VERSION ""

NS_ :

BS_:

BU_: Sender
VAL_TABLE_ FMI 31 "ConditionExists" 19 "Received network data in error" 18 "Below normal (moderately severe)" 17 "Below normal (least severe)" 16 "Above normal (moderately severe)" 15 "Above normal (least severe)" 14 "Special intstructions" 13 "Out of calibration" 12 "Bad intelligent device" 11 "Root cause not known" 10 "Abnormal rate of change" 9 "Abnormal update rate" 8 "Abnormal frequency" 7 "Mechanical system not responding" 6 "Current above normal" 5 "Current below normal" 4 "Voltage below normal" 3 "Voltage above normal" 2 "Data erratic" 1 "Below normal (most severe)" 0 "Above normal (most severe)" ;

BO_ 3221225472 VECTOR__INDEPENDENT_SIG_MSG: 0 Vector__XXX
 SG_ TireTemp : 0|16@1+ (0.03125,-273) [-273|1735] "deg" Vector__XXX
 SG_ TirePress : 0|8@1+ (4,0) [0|1000] "kPa" Vector__XXX
 SG_ SPN5 : 0|16@1+ (1,0) [0|65536] "" Vector__XXX
 SG_ SPN4 : 0|16@1+ (1,0) [0|65536] "" Vector__XXX
 SG_ SPN3 : 0|16@1+ (1,0) [0|65536] "" Vector__XXX
 SG_ SPN2 : 0|16@1+ (1,0) [0|65536] "" Vector__XXX
 SG_ FailureModeIdentifier5 : 0|5@1+ (1,0) [0|0] "" Vector__XXX
 SG_ FailureModeIdentifier4 : 0|5@1+ (1,0) [0|0] "" Vector__XXX
 SG_ FlashRedStopLamp : 0|2@1+ (1,0) [0|3] "" Vector__XXX
 SG_ FlashProtectLamp : 0|2@1+ (1,0) [0|3] "" Vector__XXX
 SG_ FlashMalfuncIndicatorLamp : 0|2@1+ (1,0) [0|3] "" Vector__XXX
 SG_ FlashAmberWarningLamp : 0|2@1+ (1,0) [0|3] "" Vector__XXX
 SG_ FailureModeIdentifier3 : 0|5@1+ (1,0) [0|0] "" Vector__XXX
 SG_ FailureModeIdentifier2 : 0|5@1+ (1,0) [0|0] "" Vector__XXX
 SG_ SPNConversionMethod5 : 0|1@1+ (1,0) [0|1] "" Vector__XXX
 SG_ SPNConversionMethod4 : 0|1@1+ (1,0) [0|1] "" Vector__XXX
 SG_ SPNConversionMethod3 : 0|1@1+ (1,0) [0|1] "" Vector__XXX
 SG_ SPNConversionMethod2 : 0|1@1+ (1,0) [0|1] "" Vector__XXX
 SG_ SPNConversionMethod1 : 0|1@1+ (1,0) [0|1] "" Vector__XXX
 SG_ FailureModeIdentifier1 : 0|5@1+ (1,0) [0|0] "" Vector__XXX
 SG_ SPN1 : 0|16@1+ (1,0) [0|65536] "" Vector__XXX
 SG_ MalfunctionIndicatorLampStatus : 0|2@1+ (1,0) [0|3] "" Vector__XXX
 SG_ RedStopLampState : 0|2@1+ (1,0) [0|3] "" Vector__XXX
 SG_ AmberWarningLampStatus : 0|2@1+ (1,0) [0|3] "" Vector__XXX
 SG_ ProtectLampStatus : 0|2@1+ (1,0) [0|3] "" Vector__XXX
 SG_ SPN5High : 0|3@1+ (1,0) [0|7] "" Vector__XXX
 SG_ SPN4High : 0|3@1+ (1,0) [0|7] "" Vector__XXX
 SG_ SPN3High : 0|3@1+ (1,0) [0|7] "" Vector__XXX
 SG_ SPN2High : 0|3@1+ (1,0) [0|7] "" Vector__XXX
 SG_ SPN1High : 0|3@1+ (1,0) [0|7] "" Vector__XXX
 SG_ SPNConversionMethod1 : 0|1@1+ (1,0) [0|1] "" Vector__XXX
 SG_ FailureModeIdentifier1 : 0|5@1+ (1,0) [0|0] "" Vector__XXX
 SG_ SPN1 : 0|16@1+ (1,0) [0|65536] "" Vector__XXX
 SG_ SPN1High : 0|3@1+ (1,0) [0|7] "" Vector__XXX
 SG_ SPNConversionMethod1 : 0|1@1+ (1,0) [0|1] "" Vector__XXX
 SG_ FailureModeIdentifier1 : 0|5@1+ (1,0) [0|0] "" Vector__XXX
 SG_ SPN1 : 0|16@1+ (1,0) [0|65536] "" Vector__XXX
 SG_ SPN1High : 0|3@1+ (1,0) [0|7] "" Vector__XXX
 SG_ SPN5 : 0|16@1+ (1,0) [0|65536] "" Vector__XXX
 SG_ SPN4 : 0|16@1+ (1,0) [0|65536] "" Vector__XXX
 SG_ SPN3 : 0|16@1+ (1,0) [0|65536] "" Vector__XXX
 SG_ SPN2 : 0|16@1+ (1,0) [0|65536] "" Vector__XXX
 SG_ FailureModeIdentifier5 : 0|5@1+ (1,0) [0|0] "" Vector__XXX
 SG_ FailureModeIdentifier4 : 0|5@1+ (1,0) [0|0] "" Vector__XXX
 SG_ SPNConversionMethod1 : 0|1@1+ (1,0) [0|1] "" Vector__XXX
 SG_ FailureModeIdentifier1 : 0|5@1+ (1,0) [0|0] "" Vector__XXX
 SG_ SPN1 : 0|16@1+ (1,0) [0|65536] "" Vector__XXX
 SG_ MalfunctionIndicatorLampStatus : 0|2@1+ (1,0) [0|3] "" Vector__XXX
 SG_ RedStopLampState : 0|2@1+ (1,0) [0|3] "" Vector__XXX
 SG_ AmberWarningLampStatus : 0|2@1+ (1,0) [0|3] "" Vector__XXX
 SG_ ProtectLampStatus : 0|2@1+ (1,0) [0|3] "" Vector__XXX
 SG_ FailureModeIdentifier3 : 0|5@1+ (1,0) [0|0] "" Vector__XXX
 SG_ FlashRedStopLamp : 0|2@1+ (1,0) [0|3] "" Vector__XXX
 SG_ FlashProtectLamp : 0|2@1+ (1,0) [0|3] "" Vector__XXX
 SG_ FlashMalfuncIndicatorLamp : 0|2@1+ (1,0) [0|3] "" Vector__XXX
 SG_ FlashAmberWarningLamp : 0|2@1+ (1,0) [0|3] "" Vector__XXX
 SG_ FailureModeIdentifier2 : 0|5@1+ (1,0) [0|0] "" Vector__XXX
 SG_ SPNConversionMethod5 : 0|1@1+ (1,0) [0|1] "" Vector__XXX
 SG_ SPNConversionMethod4 : 0|1@1+ (1,0) [0|1] "" Vector__XXX
 SG_ SPNConversionMethod3 : 0|1@1+ (1,0) [0|1] "" Vector__XXX
 SG_ SPNConversionMethod2 : 0|1@1+ (1,0) [0|1] "" Vector__XXX
 SG_ SPN5High : 0|3@1+ (1,0) [0|7] "" Vector__XXX
 SG_ SPN4High : 0|3@1+ (1,0) [0|7] "" Vector__XXX
 SG_ SPN3High : 0|3@1+ (1,0) [0|7] "" Vector__XXX
 SG_ SPN2High : 0|3@1+ (1,0) [0|7] "" Vector__XXX
 SG_ SPN1High : 0|3@1+ (1,0) [0|7] "" Vector__XXX
 SG_ SPN5 : 0|16@1+ (1,0) [0|65536] "" Vector__XXX
 SG_ SPN4 : 0|16@1+ (1,0) [0|65536] "" Vector__XXX
 SG_ SPN3 : 0|16@1+ (1,0) [0|65536] "" Vector__XXX
 SG_ SPN2 : 0|16@1+ (1,0) [0|65536] "" Vector__XXX
 SG_ FlashRedStopLamp : 0|2@1+ (1,0) [0|3] "" Vector__XXX
 SG_ FlashProtectLamp : 0|2@1+ (1,0) [0|3] "" Vector__XXX
 SG_ FailureModeIdentifier5 : 0|5@1+ (1,0) [0|0] "" Vector__XXX
 SG_ FailureModeIdentifier4 : 0|5@1+ (1,0) [0|0] "" Vector__XXX
 SG_ FailureModeIdentifier3 : 0|5@1+ (1,0) [0|0] "" Vector__XXX
 SG_ SPNConversionMethod1 : 0|1@1+ (1,0) [0|1] "" Vector__XXX
 SG_ FailureModeIdentifier1 : 0|5@1+ (1,0) [0|0] "" Vector__XXX
 SG_ MalfunctionIndicatorLampStatus : 0|2@1+ (1,0) [0|3] "" Vector__XXX
 SG_ RedStopLampState : 0|2@1+ (1,0) [0|3] "" Vector__XXX
 SG_ AmberWarningLampStatus : 0|2@1+ (1,0) [0|3] "" Vector__XXX
 SG_ ProtectLampStatus : 0|2@1+ (1,0) [0|3] "" Vector__XXX
 SG_ FlashMalfuncIndicatorLamp : 0|2@1+ (1,0) [0|3] "" Vector__XXX
 SG_ FlashAmberWarningLamp : 0|2@1+ (1,0) [0|3] "" Vector__XXX
 SG_ FailureModeIdentifier2 : 0|5@1+ (1,0) [0|0] "" Vector__XXX
 SG_ SPNConversionMethod5 : 0|1@1+ (1,0) [0|1] "" Vector__XXX
 SG_ SPNConversionMethod4 : 0|1@1+ (1,0) [0|1] "" Vector__XXX
 SG_ SPNConversionMethod3 : 0|1@1+ (1,0) [0|1] "" Vector__XXX
 SG_ SPNConversionMethod2 : 0|1@1+ (1,0) [0|1] "" Vector__XXX
 SG_ SPN5High : 0|3@1+ (1,0) [0|7] "" Vector__XXX
 SG_ SPN4High : 0|3@1+ (1,0) [0|7] "" Vector__XXX
 SG_ SPN3High : 0|3@1+ (1,0) [0|7] "" Vector__XXX
 SG_ SPN2High : 0|3@1+ (1,0) [0|7] "" Vector__XXX
 SG_ SPN1High : 0|3@1+ (1,0) [0|7] "" Vector__XXX
 SG_ SPN5 : 0|16@1+ (1,0) [0|65536] "" Vector__XXX
 SG_ SPN4 : 0|16@1+ (1,0) [0|65536] "" Vector__XXX
 SG_ SPN3 : 0|16@1+ (1,0) [0|65536] "" Vector__XXX
 SG_ SPN2 : 0|16@1+ (1,0) [0|65536] "" Vector__XXX
 SG_ FailureModeIdentifier5 : 0|5@1+ (1,0) [0|0] "" Vector__XXX
 SG_ FailureModeIdentifier4 : 0|5@1+ (1,0) [0|0] "" Vector__XXX
 SG_ FailureModeIdentifier3 : 0|5@1+ (1,0) [0|0] "" Vector__XXX
 SG_ SPNConversionMethod1 : 0|1@1+ (1,0) [0|1] "" Vector__XXX
 SG_ FailureModeIdentifier1 : 0|5@1+ (1,0) [0|0] "" Vector__XXX
 SG_ SPN1 : 0|16@1+ (1,0) [0|65536] "" Vector__XXX
 SG_ FailureModeIdentifier2 : 0|5@1+ (1,0) [0|0] "" Vector__XXX
 SG_ SPNConversionMethod5 : 0|1@1+ (1,0) [0|1] "" Vector__XXX
 SG_ SPNConversionMethod4 : 0|1@1+ (1,0) [0|1] "" Vector__XXX
 SG_ SPNConversionMethod3 : 0|1@1+ (1,0) [0|1] "" Vector__XXX
 SG_ SPNConversionMethod2 : 0|1@1+ (1,0) [0|1] "" Vector__XXX
 SG_ SPN5High : 0|3@1+ (1,0) [0|7] "" Vector__XXX
 SG_ SPN4High : 0|3@1+ (1,0) [0|7] "" Vector__XXX
 SG_ SPN3High : 0|3@1+ (1,0) [0|7] "" Vector__XXX
 SG_ SPN2High : 0|3@1+ (1,0) [0|7] "" Vector__XXX
 SG_ SPN1High : 0|3@1+ (1,0) [0|7] "" Vector__XXX
 SG_ LocalHourOffset : 0|8@1+ (1,-125) [-125|125] "hr" Vector__XXX
 SG_ LocalMinuteOffset : 0|8@1+ (1,-125) [-125|125] "mins" Vector__XXX
 SG_ Year : 0|8@1+ (1,1985) [1985|2235] "years" Vector__XXX
 SG_ Day : 0|8@1+ (0.25,0) [0|62.5] "days" Vector__XXX
 SG_ Month : 0|8@1+ (1,0) [0|250] "months" Vector__XXX
 SG_ Hours : 0|8@1+ (1,0) [0|250] "hr" Vector__XXX
 SG_ Minutes : 0|8@1+ (1,0) [0|250] "mins" Vector__XXX
 SG_ Seconds : 0|8@1+ (0.25,0) [0|62.5] "s" Vector__XXX
 SG_ ControlPurpose : 0|5@1+ (1,0) [0|31] "" Vector__XXX
 SG_ TransmissionRate : 0|3@1+ (1,0) [0|7] "" Vector__XXX
 SG_ EngRqedTorque_TorqueLimit : 0|8@1+ (1,-125) [-125|125] "%" Vector__XXX
 SG_ EngRqedSpeed_SpeedLimit : 0|16@1+ (0.125,0) [0|8031.875] "rpm" Vector__XXX
 SG_ OverrideCtrlModePriority : 0|2@1+ (1,0) [0|3] "" Vector__XXX
 SG_ EngRqedSpeedCtrlConditions : 0|2@1+ (1,0) [0|3] "" Vector__XXX
 SG_ EngOverrideCtrlMode : 0|2@1+ (1,0) [0|3] "" Vector__XXX
 SG_ ControlPurpose : 0|5@1+ (1,0) [0|31] "" Vector__XXX
 SG_ TransmissionRate : 0|3@1+ (1,0) [0|7] "" Vector__XXX
 SG_ EngRqedTorque_TorqueLimit : 0|8@1+ (1,-125) [-125|125] "%" Vector__XXX
 SG_ EngRqedSpeed_SpeedLimit : 0|16@1+ (0.125,0) [0|8031.875] "rpm" Vector__XXX
 SG_ OverrideCtrlModePriority : 0|2@1+ (1,0) [0|3] "" Vector__XXX
 SG_ EngRqedSpeedCtrlConditions : 0|2@1+ (1,0) [0|3] "" Vector__XXX
 SG_ EngOverrideCtrlMode : 0|2@1+ (1,0) [0|3] "" Vector__XXX
 SG_ ControlPurpose : 0|5@1+ (1,0) [0|31] "" Vector__XXX
 SG_ TransmissionRate : 0|3@1+ (1,0) [0|7] "" Vector__XXX
 SG_ EngRqed_TorqueLimit : 0|8@1+ (1,-125) [-125|125] "%" Vector__XXX
 SG_ EngRqed_SpeedLimit : 0|16@1+ (0.125,0) [0|8031.875] "rpm" Vector__XXX
 SG_ OverrideCtrlModePrio : 0|2@1+ (1,0) [0|3] "" Vector__XXX
 SG_ EngRqedSpeedCtrlCond : 0|2@1+ (1,0) [0|3] "" Vector__XXX
 SG_ EngOverrideCtrlMode : 0|2@1+ (1,0) [0|3] "" Vector__XXX
 SG_ ControlPurpose : 0|5@1+ (1,0) [0|31] "" Vector__XXX
 SG_ TransmissionRate : 0|3@1+ (1,0) [0|7] "" Vector__XXX
 SG_ EngRqedTorque_TorqueLimit : 0|8@1+ (1,-125) [-125|125] "%" Vector__XXX
 SG_ EngRqedSpeed_SpeedLimit : 0|16@1+ (0.125,0) [0|8031.875] "rpm" Vector__XXX
 SG_ OverrideCtrlModePriority : 0|2@1+ (1,0) [0|3] "" Vector__XXX
 SG_ EngRqedSpeedCtrlConditions : 0|2@1+ (1,0) [0|3] "" Vector__XXX
 SG_ EngOverrideCtrlMode : 0|2@1+ (1,0) [0|3] "" Vector__XXX
 SG_ ControlPurpose : 0|5@1+ (1,0) [0|31] "" Vector__XXX
 SG_ TransmissionRate : 0|3@1+ (1,0) [0|7] "" Vector__XXX
 SG_ EngRqedTorque_TorqueLimit : 0|8@1+ (1,-125) [-125|125] "%" Vector__XXX
 SG_ EngRqedSpeed_SpeedLimit : 0|16@1+ (0.125,0) [0|8031.875] "rpm" Vector__XXX
 SG_ OverrideCtrlModePriority : 0|2@1+ (1,0) [0|3] "" Vector__XXX
 SG_ EngRqedSpeedCtrlConditions : 0|2@1+ (1,0) [0|3] "" Vector__XXX
 SG_ EngOverrideCtrlMode : 0|2@1+ (1,0) [0|3] "" Vector__XXX
 SG_ ControlPurpose : 0|5@1+ (1,0) [0|31] "" Vector__XXX
 SG_ TransmissionRate : 0|3@1+ (1,0) [0|7] "" Vector__XXX
 SG_ EngRqed_TorqueLimit : 0|8@1+ (1,-125) [-125|125] "%" Vector__XXX
 SG_ EngRqed_SpeedLimit : 0|16@1+ (0.125,0) [0|8031.875] "rpm" Vector__XXX
 SG_ OverrideCtrlModePrio : 0|2@1+ (1,0) [0|3] "" Vector__XXX
 SG_ EngRqedSpeedCtrlCond : 0|2@1+ (1,0) [0|3] "" Vector__XXX
 SG_ EngOverrideCtrlMode : 0|2@1+ (1,0) [0|3] "" Vector__XXX
 SG_ TestLimitMinimum : 0|16@1+ (1,0) [0|64255] "" Vector__XXX
 SG_ TestLimitMaximum : 0|16@1+ (1,0) [0|64255] "" Vector__XXX
 SG_ TestValue : 0|16@1+ (1,0) [0|64255] "" Vector__XXX
 SG_ TestType : 0|8@1+ (1,0) [1|64] "" Vector__XXX
 SG_ TestIdentifier : 0|8@1+ (1,0) [1|64] "" Vector__XXX
 SG_ TestLimitMinimum : 0|16@1+ (1,0) [0|64255] "" Vector__XXX
 SG_ TestLimitMaximum : 0|16@1+ (1,0) [0|64255] "" Vector__XXX
 SG_ TestValue : 0|16@1+ (1,0) [0|64255] "" Vector__XXX
 SG_ TestType : 0|8@1+ (1,0) [1|64] "" Vector__XXX
 SG_ TestIdentifier : 0|8@1+ (1,0) [1|64] "" Vector__XXX
 SG_ TestLimitMinimum : 0|16@1+ (1,0) [0|64255] "" Vector__XXX
 SG_ TestLimitMaximum : 0|16@1+ (1,0) [0|64255] "" Vector__XXX
 SG_ TestValue : 0|16@1+ (1,0) [0|64255] "" Vector__XXX
 SG_ SlotId : 0|16@1+ (1,0) [0|64255] "" Vector__XXX
 SG_ TestIdentifier : 0|8@1+ (1,0) [1|64] "" Vector__XXX
 SG_ FailureModeIdentifier1 : 0|5@1+ (1,0) [0|0] "" Vector__XXX
 SG_ SPN1High : 0|3@1+ (1,0) [0|7] "" Vector__XXX
 SG_ SPN1 : 0|16@1+ (1,0) [0|65536] "" Vector__XXX
 SG_ TestLimitMinimum : 0|16@1+ (1,0) [0|64255] "" Vector__XXX
 SG_ TestLimitMaximum : 0|16@1+ (1,0) [0|64255] "" Vector__XXX
 SG_ TestValue : 0|16@1+ (1,0) [0|64255] "" Vector__XXX
 SG_ SlotId : 0|16@1+ (1,0) [0|64255] "" Vector__XXX
 SG_ TestIdentifier : 0|8@1+ (1,0) [1|64] "" Vector__XXX
 SG_ FailureModeIdentifier1 : 0|5@1+ (1,0) [0|0] "" Vector__XXX
 SG_ SPN1High : 0|3@1+ (1,0) [0|7] "" Vector__XXX
 SG_ SPN1 : 0|16@1+ (1,0) [0|65536] "" Vector__XXX
 SG_ PercentTorqueAtPeakTorquePoint5 : 0|8@1+ (1,-125) [-125|125] "%" Vector__XXX
 SG_ ReferenceRetarderTorque : 0|16@1+ (1,0) [0|64255] "Nm" Vector__XXX
 SG_ RetarderSpeedAtPeakTorquePoint5 : 0|16@1+ (0.125,0) [0|8031.875] "rpm" Vector__XXX
 SG_ PercentTorqueAtPoint4 : 0|8@1+ (1,-125) [-125|125] "%" Vector__XXX
 SG_ RetarderSpeedAtPoint4 : 0|16@1+ (0.125,0) [0|8031.875] "rpm" Vector__XXX
 SG_ PercentTorqueAtPoint3 : 0|8@1+ (1,-125) [-125|125] "%" Vector__XXX
 SG_ RetarderSpeedAtPoint3 : 0|16@1+ (0.125,0) [0|8031.875] "rpm" Vector__XXX
 SG_ PercentTorqueAtMaxSpeedPoint2 : 0|8@1+ (1,-125) [-125|125] "%" Vector__XXX
 SG_ MaxRetarderSpeedPoint2 : 0|16@1+ (0.125,0) [0|8031.875] "rpm" Vector__XXX
 SG_ PercentTorqueAtIdlePoint1 : 0|8@1+ (1,-125) [-125|125] "%" Vector__XXX
 SG_ RetarderSpeedAtIdlePoint1 : 0|16@1+ (0.125,0) [0|8031.875] "rpm" Vector__XXX
 SG_ RetarderCtrlMethod : 0|8@1+ (1,0) [0|250] "steps" Vector__XXX
 SG_ RetarderLocation : 0|4@1+ (1,0) [0|15] "" Vector__XXX
 SG_ RetarderType : 0|4@1+ (1,0) [0|15] "" Vector__XXX
 SG_ RetarderSelectionNonEng : 0|8@1+ (0.4,0) [0|100] "%" Vector__XXX
 SG_ ActlMxAvlblRtarderPercentTorque : 0|8@1+ (1,-125) [-125|125] "%" Vector__XXX
 SG_ DrvrsDmandRetarderPercentTorque : 0|8@1+ (1,-125) [-125|125] "%" Vector__XXX
 SG_ SrcAddrssOfCtrllngDvcFrRtrdrCtrl : 0|8@1+ (1,0) [0|255] "" Vector__XXX
 SG_ RetarderRqingBrakeLight : 0|2@1+ (1,0) [0|3] "" Vector__XXX
 SG_ EngCoolantLoadIncrease : 0|2@1+ (1,0) [0|3] "" Vector__XXX
 SG_ IntendedRetarderPercentTorque : 0|8@1+ (1,-125) [-125|125] "%" Vector__XXX
 SG_ ActualRetarderPercentTorque : 0|8@1+ (1,-125) [-125|125] "%" Vector__XXX
 SG_ RetarderEnableShiftAssistSwitch : 0|2@1+ (1,0) [0|3] "" Vector__XXX
 SG_ RetarderEnableBrakeAssistSwitch : 0|2@1+ (1,0) [0|3] "" Vector__XXX
 SG_ RetarderTorqueMode : 0|4@1+ (1,0) [0|15] "" Vector__XXX

BO_ 2684354558 CAPL_MSG: 1785 Sender

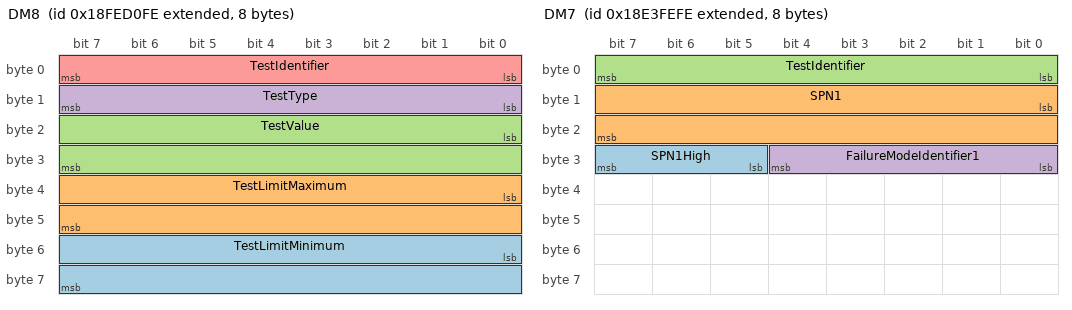
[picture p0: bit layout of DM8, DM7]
BO_ 2566836478 DM8: 8 Sender
 SG_ TestLimitMinimum : 48|16@1+ (1,0) [0|64255] "" Vector__XXX
 SG_ TestLimitMaximum : 32|16@1+ (1,0) [0|64255] "" Vector__XXX
 SG_ TestValue : 16|16@1+ (1,0) [0|64255] "" Vector__XXX
 SG_ TestType : 8|8@1+ (1,0) [1|64] "" Vector__XXX
 SG_ TestIdentifier : 0|8@1+ (1,0) [1|64] "" Vector__XXX

BO_ 2565078782 DM7: 8 Sender
 SG_ SPN1High : 29|3@1+ (1,0) [0|7] "" Vector__XXX
 SG_ SPN1 : 8|16@1+ (1,0) [0|65536] "" Vector__XXX
 SG_ TestIdentifier : 0|8@1+ (1,0) [1|64] "" Vector__XXX
 SG_ FailureModeIdentifier1 : 24|5@1+ (1,0) [0|0] "" Vector__XXX

BO_ 2560950014 DM30: 12 Sender
 SG_ TestLimitMinimum : 80|16@1+ (1,0) [0|64255] "" Vector__XXX
 SG_ TestLimitMaximum : 64|16@1+ (1,0) [0|64255] "" Vector__XXX
 SG_ TestValue : 48|16@1+ (1,0) [0|64255] "" Vector__XXX
 SG_ SlotId : 32|16@1+ (1,0) [0|64255] "" Vector__XXX
 SG_ TestIdentifier : 0|8@1+ (1,0) [1|64] "" Vector__XXX
 SG_ FailureModeIdentifier1 : 24|5@1+ (1,0) [0|0] "" Vector__XXX
 SG_ SPN1High : 29|3@1+ (1,0) [0|7] "" Vector__XXX
 SG_ SPN1 : 8|16@1+ (1,0) [0|65536] "" Vector__XXX

BO_ 2348941054 TC1: 8 Sender
 SG_ TrnsShftSlctorDisplayModeSwitch : 54|2@1+ (1,0) [0|3] "" Vector__XXX
 SG_ TransMode4 : 46|2@1+ (1,0) [0|3] "" Vector__XXX
 SG_ TransMode3 : 44|2@1+ (1,0) [0|3] "" Vector__XXX
 SG_ TransMode2 : 42|2@1+ (1,0) [0|3] "" Vector__XXX
 SG_ TransMode1 : 40|2@1+ (1,0) [0|3] "" Vector__XXX
 SG_ DisengageDiffLockRqCentralRear : 36|2@1+ (1,0) [0|3] "" Vector__XXX
 SG_ DisengageDiffLockRqCentralFront : 34|2@1+ (1,0) [0|3] "" Vector__XXX
 SG_ DisengageDiffLockRqCentral : 32|2@1+ (1,0) [0|3] "" Vector__XXX
 SG_ DisengageDiffLockRqRearAxle2 : 30|2@1+ (1,0) [0|3] "" Vector__XXX
 SG_ DisengageDiffLockRqRearAxle1 : 28|2@1+ (1,0) [0|3] "" Vector__XXX
 SG_ DisengageDiffLockRqFrontAxle2 : 26|2@1+ (1,0) [0|3] "" Vector__XXX
 SG_ DisengageDiffLockRqFrontAxle1 : 24|2@1+ (1,0) [0|3] "" Vector__XXX
 SG_ TransRqedGear : 16|8@1+ (1,-125) [-125|125] "" Vector__XXX
 SG_ RqedPercentClutchSlip : 8|8@1+ (0.4,0) [0|100] "%" Vector__XXX
 SG_ DisengageDrivelineRq : 4|2@1+ (1,0) [0|3] "" Vector__XXX
 SG_ TorqueConverterLockupDisableRq : 2|2@1+ (1,0) [0|3] "" Vector__XXX
 SG_ TransGearShiftInhibitRq : 0|2@1+ (1,0) [0|3] "" Vector__XXX

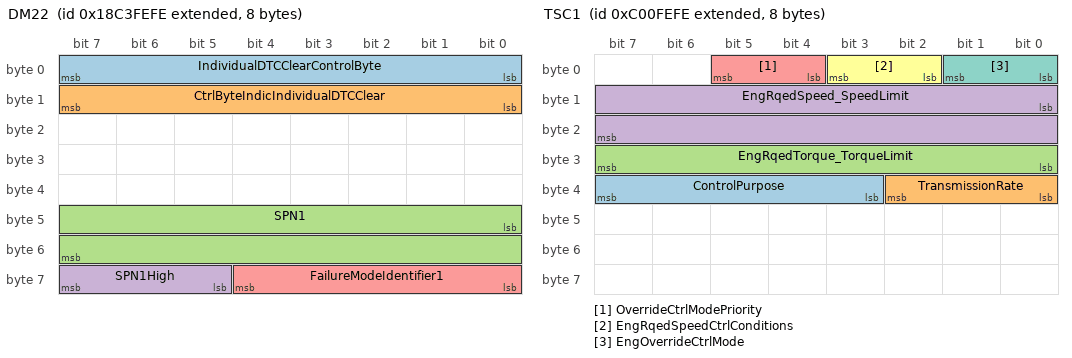
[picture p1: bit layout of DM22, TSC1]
BO_ 2562981630 DM22: 8 Sender
 SG_ IndividualDTCClearControlByte : 0|8@1+ (1,0) [0|255] "" Vector__XXX
 SG_ CtrlByteIndicIndividualDTCClear : 8|8@1+ (1,0) [0|255] "" Vector__XXX
 SG_ SPN1 : 40|16@1+ (1,0) [0|65536] "" Vector__XXX
 SG_ SPN1High : 61|3@1+ (1,0) [0|7] "" Vector__XXX
 SG_ FailureModeIdentifier1 : 56|5@1+ (1,0) [0|0] "" Vector__XXX

BO_ 2348875518 TSC1: 8 Sender
 SG_ ControlPurpose : 35|5@1+ (1,0) [0|31] "" Vector__XXX
 SG_ TransmissionRate : 32|3@1+ (1,0) [0|7] "" Vector__XXX
 SG_ EngRqedTorque_TorqueLimit : 24|8@1+ (1,-125) [-125|125] "%" Vector__XXX
 SG_ EngRqedSpeed_SpeedLimit : 8|16@1+ (0.125,0) [0|8031.875] "rpm" Vector__XXX
 SG_ OverrideCtrlModePriority : 4|2@1+ (1,0) [0|3] "" Vector__XXX
 SG_ EngRqedSpeedCtrlConditions : 2|2@1+ (1,0) [0|3] "" Vector__XXX
 SG_ EngOverrideCtrlMode : 0|2@1+ (1,0) [0|3] "" Vector__XXX

BO_ 2566840830 RC: 19 Sender
 SG_ PercentTorqueAtPeakTorquePoint5 : 144|8@1+ (1,-125) [-125|125] "%" Vector__XXX
 SG_ ReferenceRetarderTorque : 128|16@1+ (1,0) [0|64255] "Nm" Vector__XXX
 SG_ RetarderSpeedAtPeakTorquePoint5 : 112|16@1+ (0.125,0) [0|8031.875] "rpm" Vector__XXX
 SG_ PercentTorqueAtPoint4 : 104|8@1+ (1,-125) [-125|125] "%" Vector__XXX
 SG_ RetarderSpeedAtPoint4 : 88|16@1+ (0.125,0) [0|8031.875] "rpm" Vector__XXX
 SG_ PercentTorqueAtPoint3 : 80|8@1+ (1,-125) [-125|125] "%" Vector__XXX
 SG_ RetarderSpeedAtPoint3 : 64|16@1+ (0.125,0) [0|8031.875] "rpm" Vector__XXX
 SG_ PercentTorqueAtMaxSpeedPoint2 : 56|8@1+ (1,-125) [-125|125] "%" Vector__XXX
 SG_ MaxRetarderSpeedPoint2 : 40|16@1+ (0.125,0) [0|8031.875] "rpm" Vector__XXX
 SG_ PercentTorqueAtIdlePoint1 : 32|8@1+ (1,-125) [-125|125] "%" Vector__XXX
 SG_ RetarderSpeedAtIdlePoint1 : 16|16@1+ (0.125,0) [0|8031.875] "rpm" Vector__XXX
 SG_ RetarderCtrlMethod : 8|8@1+ (1,0) [0|250] "steps" Vector__XXX
 SG_ RetarderLocation : 4|4@1+ (1,0) [0|15] "" Vector__XXX
 SG_ RetarderType : 0|4@1+ (1,0) [0|15] "" Vector__XXX

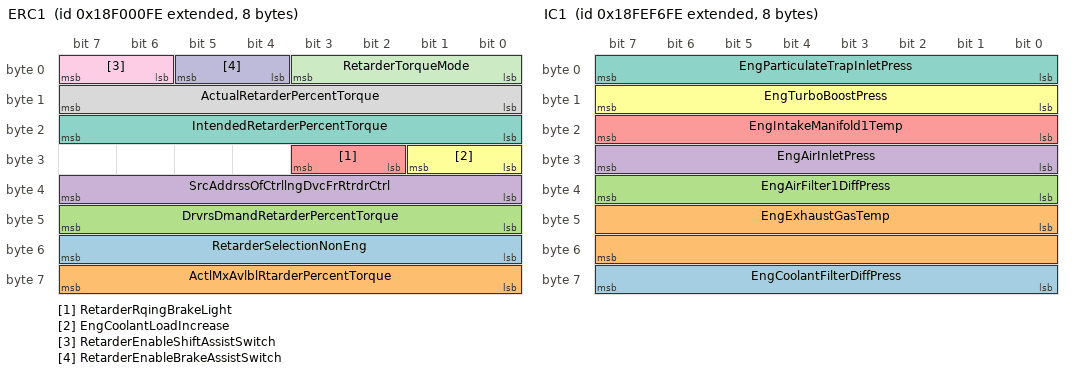
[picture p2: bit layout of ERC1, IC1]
BO_ 2565865726 ERC1: 8 Sender
 SG_ RetarderSelectionNonEng : 48|8@1+ (0.4,0) [0|100] "%" Vector__XXX
 SG_ ActlMxAvlblRtarderPercentTorque : 56|8@1+ (1,-125) [-125|125] "%" Vector__XXX
 SG_ DrvrsDmandRetarderPercentTorque : 40|8@1+ (1,-125) [-125|125] "%" Vector__XXX
 SG_ SrcAddrssOfCtrllngDvcFrRtrdrCtrl : 32|8@1+ (1,0) [0|255] "" Vector__XXX
 SG_ RetarderRqingBrakeLight : 26|2@1+ (1,0) [0|3] "" Vector__XXX
 SG_ EngCoolantLoadIncrease : 24|2@1+ (1,0) [0|3] "" Vector__XXX
 SG_ IntendedRetarderPercentTorque : 16|8@1+ (1,-125) [-125|125] "%" Vector__XXX
 SG_ ActualRetarderPercentTorque : 8|8@1+ (1,-125) [-125|125] "%" Vector__XXX
 SG_ RetarderEnableShiftAssistSwitch : 6|2@1+ (1,0) [0|3] "" Vector__XXX
 SG_ RetarderEnableBrakeAssistSwitch : 4|2@1+ (1,0) [0|3] "" Vector__XXX
 SG_ RetarderTorqueMode : 0|4@1+ (1,0) [0|15] "" Vector__XXX

BO_ 2566846206 IC1: 8 Sender
 SG_ EngCoolantFilterDiffPress : 56|8@1+ (0.5,0) [0|125] "kPa" Vector__XXX
 SG_ EngExhaustGasTemp : 40|16@1+ (0.03125,-273) [-273|1735] "deg" Vector__XXX
 SG_ EngAirFilter1DiffPress : 32|8@1+ (0.05,0) [0|12.5] "kPa" Vector__XXX
 SG_ EngAirInletPress : 24|8@1+ (2,0) [0|500] "kPa" Vector__XXX
 SG_ EngIntakeManifold1Temp : 16|8@1+ (1,-40) [-40|210] "deg" Vector__XXX
 SG_ EngTurboBoostPress : 8|8@1+ (2,0) [0|500] "kPa" Vector__XXX
 SG_ EngParticulateTrapInletPress : 0|8@1+ (0.5,0) [0|125] "kPa" Vector__XXX

BO_ 2566841854 HOURS: 8 Sender
 SG_ EngTotalRevolutions : 32|32@1+ (1000,0) [0|4211081215000] "r" Vector__XXX
 SG_ EngTotalHoursOfOperation : 0|32@1+ (0.05,0) [0|210554060.75] "hr" Vector__XXX

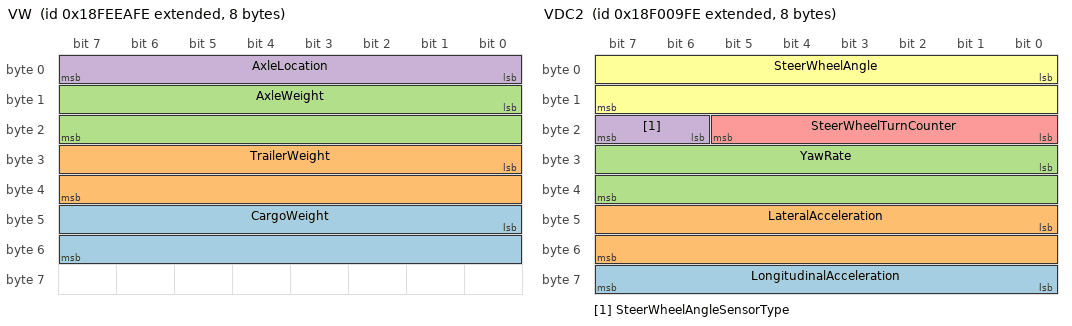
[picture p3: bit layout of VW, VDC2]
BO_ 2566843134 VW: 8 Sender
 SG_ CargoWeight : 40|16@1+ (2,0) [0|128510] "kg" Vector__XXX
 SG_ TrailerWeight : 24|16@1+ (2,0) [0|128510] "kg" Vector__XXX
 SG_ AxleWeight : 8|16@1+ (0.5,0) [0|32127.5] "kg" Vector__XXX
 SG_ AxleLocation : 0|8@1+ (1,0) [0|255] "" Vector__XXX

BO_ 2566843646 VI: 8 Sender
 SG_ VehicleIdentificationNumber : 0|8@1+ (1,0) [0|255] "" Vector__XXX

BO_ 2566832638 VDHR: 8 Sender
 SG_ HighResolutionTripDistance : 32|32@1+ (5,0) [0|21055406] "km" Vector__XXX
 SG_ HghRslutionTotalVehicleDistance : 0|32@1+ (5,0) [0|21055406] "km" Vector__XXX

BO_ 2565868030 VDC2: 8 Sender
 SG_ LongitudinalAcceleration : 56|8@1+ (0.1,-12.5) [-12.5|12.5] "m/s²" Vector__XXX
 SG_ LateralAcceleration : 40|16@1+ (0.000488281,-15.687) [-15.687|15.687] "m/s²" Vector__XXX
 SG_ YawRate : 24|16@1+ (0.00012207,-3.92) [-3.92|3.92] "rad/s" Vector__XXX
 SG_ SteerWheelAngleSensorType : 22|2@1+ (1,0) [0|3] "" Vector__XXX
 SG_ SteerWheelTurnCounter : 16|6@1+ (1,-32) [-32|29] "turns" Vector__XXX
 SG_ SteerWheelAngle : 0|16@1+ (0.000976563,-31.374) [-31.374|31.374] "rad" Vector__XXX

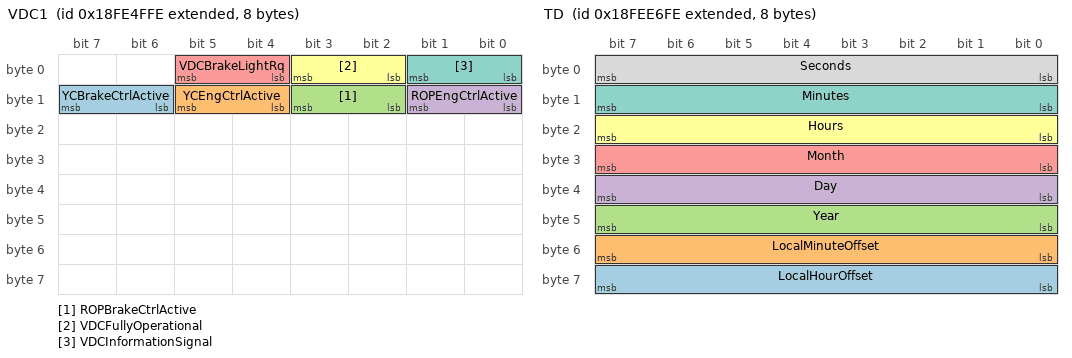
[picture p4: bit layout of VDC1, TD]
BO_ 2566803454 VDC1: 8 Sender
 SG_ YCBrakeCtrlActive : 14|2@1+ (1,0) [0|3] "" Vector__XXX
 SG_ YCEngCtrlActive : 12|2@1+ (1,0) [0|3] "" Vector__XXX
 SG_ ROPBrakeCtrlActive : 10|2@1+ (1,0) [0|3] "" Vector__XXX
 SG_ ROPEngCtrlActive : 8|2@1+ (1,0) [0|3] "" Vector__XXX
 SG_ VDCBrakeLightRq : 4|2@1+ (1,0) [0|3] "" Vector__XXX
 SG_ VDCFullyOperational : 2|2@1+ (1,0) [0|3] "" Vector__XXX
 SG_ VDCInformationSignal : 0|2@1+ (1,0) [0|3] "" Vector__XXX

BO_ 2566840574 VD: 8 Sender
 SG_ TotalVehicleDistance : 32|32@1+ (0.125,0) [0|526385151.9] "km" Vector__XXX
 SG_ TripDistance : 0|32@1+ (0.125,0) [0|526385151.9] "km" Vector__XXX

BO_ 2561605374 TPRS: 8 Sender
 SG_ ReferenceTirePressSetting : 8|8@1+ (8,0) [0|2000] "kPa" Vector__XXX
 SG_ TireLocation : 0|8@1+ (1,0) [0|255] "" Vector__XXX

BO_ 2566765054 TPRI: 8 Sender
 SG_ ReferenceTirePress : 8|8@1+ (8,0) [0|2000] "kPa" Vector__XXX
 SG_ TireLocation : 0|8@1+ (1,0) [0|255] "" Vector__XXX

BO_ 2566845694 TIRE: 8 Sender
 SG_ TireTemp_21 m33 : 16|16@1+ (0.03125,-273) [-273|1735] "deg" Vector__XXX
 SG_ TireTemp_20 m32 : 16|16@1+ (0.03125,-273) [-273|1735] "deg" Vector__XXX
 SG_ TireTemp_11 m17 : 16|16@1+ (0.03125,-273) [-273|1735] "deg" Vector__XXX
 SG_ TireTemp_10 m16 : 16|16@1+ (0.03125,-273) [-273|1735] "deg" Vector__XXX
 SG_ TireTemp_01 m1 : 16|16@1+ (0.03125,-273) [-273|1735] "deg" Vector__XXX
 SG_ TireTemp_00 m0 : 16|16@1+ (0.03125,-273) [-273|1735] "deg" Vector__XXX
 SG_ TirePressThresholdDetection_21 m33 : 61|3@1+ (1,0) [0|7] "" Vector__XXX
 SG_ TirePressThresholdDetection_20 m32 : 61|3@1+ (1,0) [0|7] "" Vector__XXX
 SG_ TirePressThresholdDetection_11 m17 : 61|3@1+ (1,0) [0|7] "" Vector__XXX
 SG_ TirePressThresholdDetection_10 m16 : 61|3@1+ (1,0) [0|7] "" Vector__XXX
 SG_ TirePressThresholdDetection_01 m1 : 61|3@1+ (1,0) [0|7] "" Vector__XXX
 SG_ TirePressThresholdDetection_00 m0 : 61|3@1+ (1,0) [0|7] "" Vector__XXX
 SG_ TirePress_21 m33 : 8|8@1+ (4,0) [0|1000] "kPa" Vector__XXX
 SG_ TirePress_20 m32 : 8|8@1+ (4,0) [0|1000] "kPa" Vector__XXX
 SG_ TirePress_11 m17 : 8|8@1+ (4,0) [0|1000] "kPa" Vector__XXX
 SG_ TirePress_10 m16 : 8|8@1+ (4,0) [0|1000] "kPa" Vector__XXX
 SG_ TirePress_01 m1 : 8|8@1+ (4,0) [0|1000] "kPa" Vector__XXX
 SG_ TirePress_00 m0 : 8|8@1+ (4,0) [0|1000] "kPa" Vector__XXX
 SG_ TireAirLeakageRate_21 m33 : 40|16@1+ (0.1,0) [0|6425.5] "Pa/s" Vector__XXX
 SG_ TireAirLeakageRate_20 m32 : 40|16@1+ (0.1,0) [0|6425.5] "Pa/s" Vector__XXX
 SG_ TireAirLeakageRate_11 m17 : 40|16@1+ (0.1,0) [0|6425.5] "Pa/s" Vector__XXX
 SG_ TireAirLeakageRate_10 m16 : 40|16@1+ (0.1,0) [0|6425.5] "Pa/s" Vector__XXX
 SG_ TireAirLeakageRate_01 m1 : 40|16@1+ (0.1,0) [0|6425.5] "Pa/s" Vector__XXX
 SG_ TireAirLeakageRate_00 m0 : 40|16@1+ (0.1,0) [0|6425.5] "Pa/s" Vector__XXX
 SG_ CTIWheelSensorStatus_21 m33 : 32|2@1+ (1,0) [0|3] "" Vector__XXX
 SG_ CTIWheelSensorStatus_20 m32 : 32|2@1+ (1,0) [0|3] "" Vector__XXX
 SG_ CTIWheelSensorStatus_11 m17 : 32|2@1+ (1,0) [0|3] "" Vector__XXX
 SG_ CTIWheelSensorStatus_10 m16 : 32|2@1+ (1,0) [0|3] "" Vector__XXX
 SG_ CTIWheelSensorStatus_01 m1 : 32|2@1+ (1,0) [0|3] "" Vector__XXX
 SG_ CTIWheelSensorStatus_00 m0 : 32|2@1+ (1,0) [0|3] "" Vector__XXX
 SG_ CTIWheelEndElectricalFault_21 m33 : 36|2@1+ (1,0) [0|3] "" Vector__XXX
 SG_ CTIWheelEndElectricalFault_20 m32 : 36|2@1+ (1,0) [0|3] "" Vector__XXX
 SG_ CTIWheelEndElectricalFault_11 m17 : 36|2@1+ (1,0) [0|3] "" Vector__XXX
 SG_ CTIWheelEndElectricalFault_10 m16 : 36|2@1+ (1,0) [0|3] "" Vector__XXX
 SG_ CTIWheelEndElectricalFault_01 m1 : 36|2@1+ (1,0) [0|3] "" Vector__XXX
 SG_ CTIWheelEndElectricalFault_00 m0 : 36|2@1+ (1,0) [0|3] "" Vector__XXX
 SG_ CTITireStatus_21 m33 : 34|2@1+ (1,0) [0|3] "" Vector__XXX
 SG_ CTITireStatus_20 m32 : 34|2@1+ (1,0) [0|3] "" Vector__XXX
 SG_ CTITireStatus_11 m17 : 34|2@1+ (1,0) [0|3] "" Vector__XXX
 SG_ CTITireStatus_10 m16 : 34|2@1+ (1,0) [0|3] "" Vector__XXX
 SG_ CTITireStatus_01 m1 : 34|2@1+ (1,0) [0|3] "" Vector__XXX
 SG_ CTITireStatus_00 m0 : 34|2@1+ (1,0) [0|3] "" Vector__XXX
 SG_ TireLocation M : 0|8@1+ (1,0) [0|255] "" Vector__XXX

BO_ 2566842110 TD: 8 Sender
 SG_ LocalHourOffset : 56|8@1+ (1,-125) [-125|125] "hr" Vector__XXX
 SG_ LocalMinuteOffset : 48|8@1+ (1,-125) [-125|125] "mins" Vector__XXX
 SG_ Year : 40|8@1+ (1,1985) [1985|2235] "years" Vector__XXX
 SG_ Day : 32|8@1+ (0.25,0) [0|62.5] "days" Vector__XXX
 SG_ Month : 24|8@1+ (1,0) [0|250] "months" Vector__XXX
 SG_ Hours : 16|8@1+ (1,0) [0|250] "hr" Vector__XXX
 SG_ Minutes : 8|8@1+ (1,0) [0|250] "mins" Vector__XXX
 SG_ Seconds : 0|8@1+ (0.25,0) [0|62.5] "s" Vector__XXX

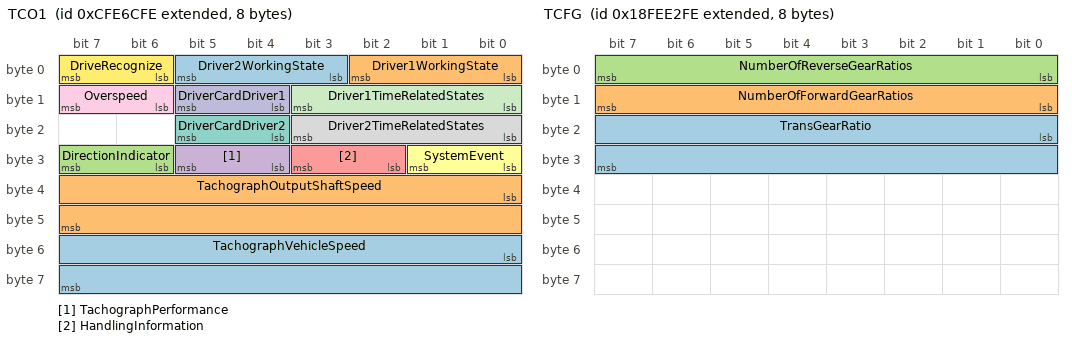
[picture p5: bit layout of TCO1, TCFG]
BO_ 2365484286 TCO1: 8 Sender
 SG_ TachographVehicleSpeed : 48|16@1+ (0.00390625,0) [0|250.996] "km/h" Vector__XXX
 SG_ TachographOutputShaftSpeed : 32|16@1+ (0.125,0) [0|8031.875] "rpm" Vector__XXX
 SG_ DirectionIndicator : 30|2@1+ (1,0) [0|3] "" Vector__XXX
 SG_ TachographPerformance : 28|2@1+ (1,0) [0|3] "" Vector__XXX
 SG_ HandlingInformation : 26|2@1+ (1,0) [0|3] "" Vector__XXX
 SG_ SystemEvent : 24|2@1+ (1,0) [0|3] "" Vector__XXX
 SG_ DriverCardDriver2 : 20|2@1+ (1,0) [0|3] "" Vector__XXX
 SG_ Driver2TimeRelatedStates : 16|4@1+ (1,0) [0|15] "" Vector__XXX
 SG_ Overspeed : 14|2@1+ (1,0) [0|3] "" Vector__XXX
 SG_ DriverCardDriver1 : 12|2@1+ (1,0) [0|3] "" Vector__XXX
 SG_ Driver1TimeRelatedStates : 8|4@1+ (1,0) [0|15] "" Vector__XXX
 SG_ DriveRecognize : 6|2@1+ (1,0) [0|3] "" Vector__XXX
 SG_ Driver2WorkingState : 3|3@1+ (1,0) [0|7] "" Vector__XXX
 SG_ Driver1WorkingState : 0|3@1+ (1,0) [0|7] "" Vector__XXX

BO_ 2566802430 TCFG2: 8 Sender
 SG_ TransTorqueLimit : 0|16@1+ (1,0) [0|64255] "Nm" Vector__XXX

BO_ 2566841086 TCFG: 8 Sender
 SG_ TransGearRatio : 16|16@1+ (0.001,0) [0|64.255] "" Vector__XXX
 SG_ NumberOfForwardGearRatios : 8|8@1+ (1,0) [0|250] "" Vector__XXX
 SG_ NumberOfReverseGearRatios : 0|8@1+ (1,0) [0|250] "" Vector__XXX

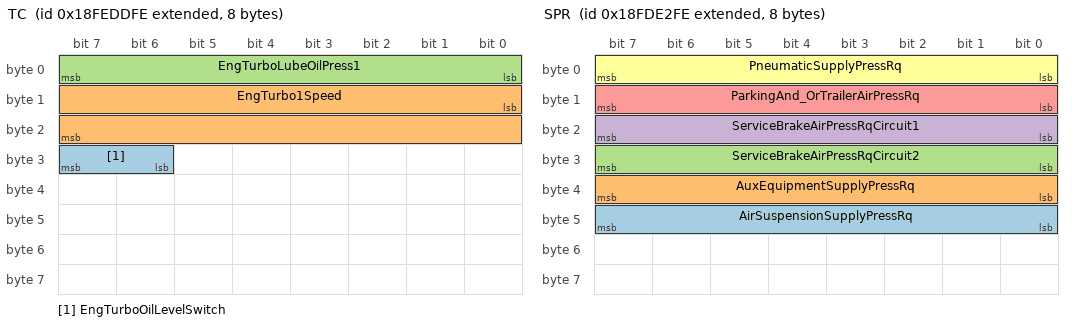
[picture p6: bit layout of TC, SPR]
BO_ 2566839806 TC: 8 Sender
 SG_ EngTurboOilLevelSwitch : 30|2@1+ (1,0) [0|3] "" Vector__XXX
 SG_ EngTurbo1Speed : 8|16@1+ (4,0) [0|257020] "rpm" Vector__XXX
 SG_ EngTurboLubeOilPress1 : 0|8@1+ (4,0) [0|1000] "kPa" Vector__XXX

BO_ 2566775550 SPR: 8 Sender
 SG_ AirSuspensionSupplyPressRq : 40|8@1+ (8,0) [0|2000] "kPa" Vector__XXX
 SG_ AuxEquipmentSupplyPressRq : 32|8@1+ (8,0) [0|2000] "kPa" Vector__XXX
 SG_ ServiceBrakeAirPressRqCircuit2 : 24|8@1+ (8,0) [0|2000] "kPa" Vector__XXX
 SG_ ServiceBrakeAirPressRqCircuit1 : 16|8@1+ (8,0) [0|2000] "kPa" Vector__XXX
 SG_ ParkingAnd_OrTrailerAirPressRq : 8|8@1+ (8,0) [0|2000] "kPa" Vector__XXX
 SG_ PneumaticSupplyPressRq : 0|8@1+ (8,0) [0|2000] "kPa" Vector__XXX

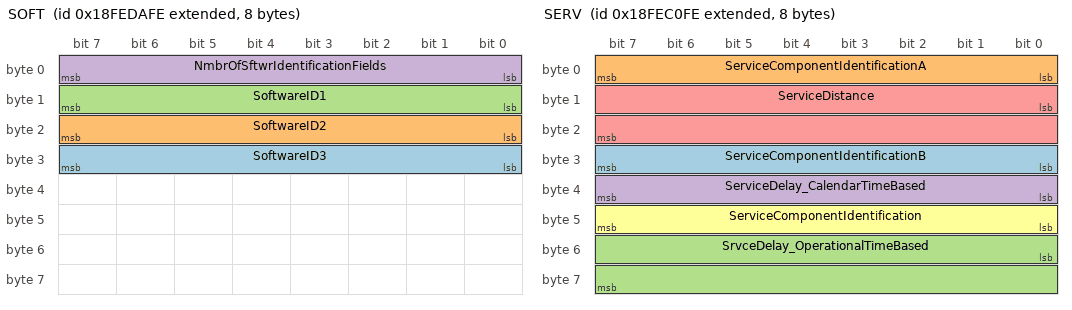
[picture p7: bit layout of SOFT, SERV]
BO_ 2566839038 SOFT: 8 Sender
 SG_ SoftwareID3 : 24|8@1+ (1,0) [0|255] "" Vector__XXX
 SG_ SoftwareID2 : 16|8@1+ (1,0) [0|255] "" Vector__XXX
 SG_ SoftwareID1 : 8|8@1+ (1,0) [0|255] "" Vector__XXX
 SG_ NmbrOfSftwrIdentificationFields : 0|8@1+ (1,0) [0|250] "steps" Vector__XXX

BO_ 2566841598 SHUTDOW: 8 Sender
 SG_ EngOverspeedTest : 54|2@1+ (1,0) [0|3] "" Vector__XXX
 SG_ EngAirShutoffCmdStatus : 52|2@1+ (1,0) [0|3] "" Vector__XXX
 SG_ EngAlarmOutputCmdStatus : 50|2@1+ (1,0) [0|3] "" Vector__XXX
 SG_ EngAlarmAcknowledge : 48|2@1+ (1,0) [0|3] "" Vector__XXX
 SG_ EngProtectionSystemConfig : 46|2@1+ (1,0) [0|3] "" Vector__XXX
 SG_ EngProtectionSystemTimerState : 38|2@1+ (1,0) [0|3] "" Vector__XXX
 SG_ EngPrtectionSystemTimerOverride : 36|2@1+ (1,0) [0|3] "" Vector__XXX
 SG_ EngPrtctnSystmApprchingShutdown : 34|2@1+ (1,0) [0|3] "" Vector__XXX
 SG_ EngPrtctionSystemHasShutdownEng : 32|2@1+ (1,0) [0|3] "" Vector__XXX
 SG_ EngWaitToStartLamp : 24|2@1+ (1,0) [0|3] "" Vector__XXX
 SG_ RefrigerantHighPressSwitch : 20|2@1+ (1,0) [0|3] "" Vector__XXX
 SG_ RefrigerantLowPressSwitch : 18|2@1+ (1,0) [0|3] "" Vector__XXX
 SG_ A_CHighPressFanSwitch : 16|2@1+ (1,0) [0|3] "" Vector__XXX
 SG_ EngIdleShutdownTimerFunction : 14|2@1+ (1,0) [0|3] "" Vector__XXX
 SG_ EngIdleShutdownTimerState : 6|2@1+ (1,0) [0|3] "" Vector__XXX
 SG_ EngIdleShutdownTimerOverride : 4|2@1+ (1,0) [0|3] "" Vector__XXX
 SG_ EngIdleShutdownDriverAlertMode : 2|2@1+ (1,0) [0|3] "" Vector__XXX
 SG_ EngIdleShutdownHasShutdownEng : 0|2@1+ (1,0) [0|3] "" Vector__XXX

BO_ 2566832382 SERV: 8 Sender
 SG_ ServiceComponentIdentificationB : 24|8@1+ (1,0) [0|250] "ID" Vector__XXX
 SG_ ServiceComponentIdentificationA : 0|8@1+ (1,0) [0|250] "ID" Vector__XXX
 SG_ SrvceDelay_OperationalTimeBased : 48|16@1+ (1,-31873) [-31873|32128] "hr" Vector__XXX
 SG_ ServiceDelay_CalendarTimeBased : 32|8@1+ (1,-125) [-125|125] "weeks" Vector__XXX
 SG_ ServiceDistance : 8|16@1+ (5,-159365) [-159365|160640] "km" Vector__XXX
 SG_ ServiceComponentIdentification : 40|8@1+ (1,0) [0|250] "ID" Vector__XXX

BO_ 2566847486 RF: 8 Sender
 SG_ HydRetarderOilTemp : 8|8@1+ (1,-40) [-40|210] "deg" Vector__XXX
 SG_ HydRetarderPress : 0|8@1+ (16,0) [0|4000] "kPa" Vector__XXX

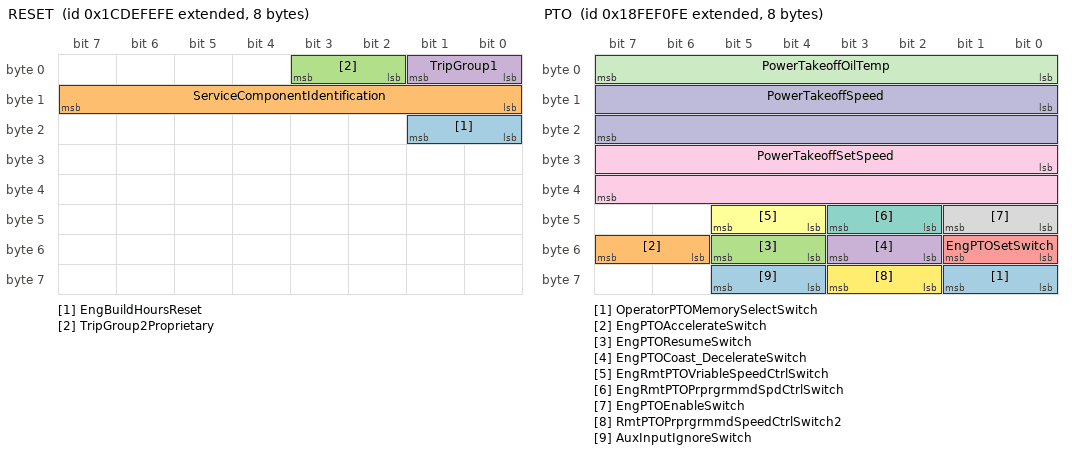
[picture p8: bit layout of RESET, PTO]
BO_ 2631859966 RESET: 8 Sender
 SG_ EngBuildHoursReset : 16|2@1+ (1,0) [0|3] "" Vector__XXX
 SG_ ServiceComponentIdentification : 8|8@1+ (1,0) [0|250] "ID" Vector__XXX
 SG_ TripGroup2Proprietary : 2|2@1+ (1,0) [0|3] "" Vector__XXX
 SG_ TripGroup1 : 0|2@1+ (1,0) [0|3] "" Vector__XXX

BO_ 2566844670 PTO: 8 Sender
 SG_ OperatorPTOMemorySelectSwitch : 56|2@1+ (1,0) [0|3] "" Vector__XXX
 SG_ EngPTOAccelerateSwitch : 54|2@1+ (1,0) [0|3] "" Vector__XXX
 SG_ EngPTOResumeSwitch : 52|2@1+ (1,0) [0|3] "" Vector__XXX
 SG_ EngPTOCoast_DecelerateSwitch : 50|2@1+ (1,0) [0|3] "" Vector__XXX
 SG_ EngPTOSetSwitch : 48|2@1+ (1,0) [0|3] "" Vector__XXX
 SG_ EngRmtPTOVriableSpeedCtrlSwitch : 44|2@1+ (1,0) [0|3] "" Vector__XXX
 SG_ EngRmtPTOPrprgrmmdSpdCtrlSwitch : 42|2@1+ (1,0) [0|3] "" Vector__XXX
 SG_ EngPTOEnableSwitch : 40|2@1+ (1,0) [0|3] "" Vector__XXX
 SG_ PowerTakeoffSetSpeed : 24|16@1+ (0.125,0) [0|8031.875] "rpm" Vector__XXX
 SG_ PowerTakeoffSpeed : 8|16@1+ (0.125,0) [0|8031.875] "rpm" Vector__XXX
 SG_ PowerTakeoffOilTemp : 0|8@1+ (1,-40) [-40|210] "deg" Vector__XXX
 SG_ RmtPTOPrprgrmmdSpeedCtrlSwitch2 : 58|2@1+ (1,0) [0|3] "" Vector__XXX
 SG_ AuxInputIgnoreSwitch : 60|2@1+ (1,0) [0|3] "" Vector__XXX

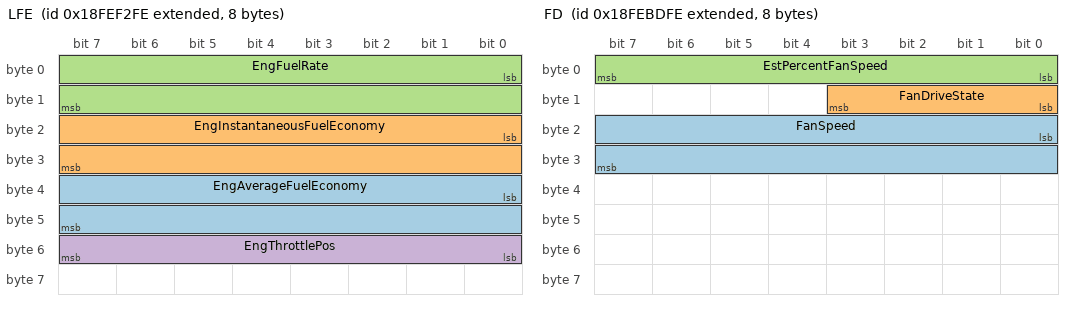
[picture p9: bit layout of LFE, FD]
BO_ 2566845182 LFE: 8 Sender
 SG_ EngAverageFuelEconomy : 32|16@1+ (0.001953125,0) [0|125.5] "km/L" Vector__XXX
 SG_ EngInstantaneousFuelEconomy : 16|16@1+ (0.001953125,0) [0|125.5] "km/L" Vector__XXX
 SG_ EngFuelRate : 0|16@1+ (0.05,0) [0|3212.75] "L/h" Vector__XXX
 SG_ EngThrottlePos : 48|8@1+ (0.4,0) [0|100] "%" Vector__XXX

BO_ 2566842878 LFC: 8 Sender
 SG_ EngTotalFuelUsed : 32|32@1+ (0.5,0) [0|2105540607.5] "L" Vector__XXX
 SG_ EngTripFuel : 0|32@1+ (0.5,0) [0|2105540607.5] "L" Vector__XXX

BO_ 2566831614 FD: 8 Sender
 SG_ FanSpeed : 16|16@1+ (0.125,0) [0|8031.875] "rpm" Vector__XXX
 SG_ FanDriveState : 8|4@1+ (1,0) [0|15] "" Vector__XXX
 SG_ EstPercentFanSpeed : 0|8@1+ (0.4,0) [0|100] "%" Vector__XXX

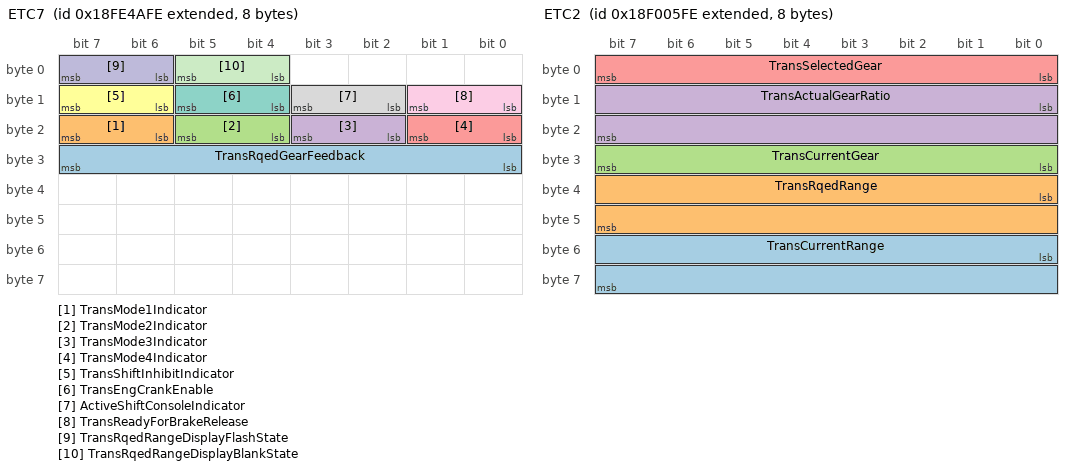
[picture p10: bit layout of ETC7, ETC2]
BO_ 2566802174 ETC7: 8 Sender
 SG_ TransRqedGearFeedback : 24|8@1+ (1,-125) [-125|125] "" Vector__XXX
 SG_ TransMode1Indicator : 22|2@1+ (1,0) [0|3] "" Vector__XXX
 SG_ TransMode2Indicator : 20|2@1+ (1,0) [0|3] "" Vector__XXX
 SG_ TransMode3Indicator : 18|2@1+ (1,0) [0|3] "" Vector__XXX
 SG_ TransMode4Indicator : 16|2@1+ (1,0) [0|3] "" Vector__XXX
 SG_ TransShiftInhibitIndicator : 14|2@1+ (1,0) [0|3] "" Vector__XXX
 SG_ TransEngCrankEnable : 12|2@1+ (1,0) [0|3] "" Vector__XXX
 SG_ ActiveShiftConsoleIndicator : 10|2@1+ (1,0) [0|3] "" Vector__XXX
 SG_ TransReadyForBrakeRelease : 8|2@1+ (1,0) [0|3] "" Vector__XXX
 SG_ TransRqedRangeDisplayFlashState : 6|2@1+ (1,0) [0|3] "" Vector__XXX
 SG_ TransRqedRangeDisplayBlankState : 4|2@1+ (1,0) [0|3] "" Vector__XXX

BO_ 2565867006 ETC2: 8 Sender
 SG_ TransCurrentRange : 48|16@1+ (1,0) [0|255] "" Vector__XXX
 SG_ TransRqedRange : 32|16@1+ (1,0) [0|255] "" Vector__XXX
 SG_ TransCurrentGear : 24|8@1+ (1,-125) [-125|125] "" Vector__XXX
 SG_ TransActualGearRatio : 8|16@1+ (0.001,0) [0|64.255] "" Vector__XXX
 SG_ TransSelectedGear : 0|8@1+ (1,-125) [-125|125] "" Vector__XXX

CM_ BO_ 3221225472 "This is a message for not used signals, created by Vector CANdb++ DBC OLE DB Provider.";
CM_ SG_ 3221225472 TireTemp "Temperature at the surface of the tire sidewall. (SP242)";
CM_ SG_ 3221225472 TirePress "Pressure at which air is contained in cavity formed by tire and rim. (SP241)";
CM_ SG_ 3221225472 SPN5 "SPN #5 (Conversion Version 4)SPN #5 (Conversion Version 4)SPN #5 (Conversion Version 4)SPN #5 (Conversion Version 4)";
CM_ SG_ 3221225472 SPN4 "SPN #4 (Conversion Version 4)SPN #4 (Conversion Version 4)SPN #4 (Conversion Version 4)SPN #4 (Conversion Version 4)";
CM_ SG_ 3221225472 SPN3 "SPN #3 (Conversion Version 4)SPN #3 (Conversion Version 4)SPN #3 (Conversion Version 4)SPN #3 (Conversion Version 4)";
CM_ SG_ 3221225472 SPN2 "SPN #2 (Conversion Version 4)SPN #2 (Conversion Version 4)SPN #2 (Conversion Version 4)SPN #2 (Conversion Version 4)";
CM_ SG_ 3221225472 FailureModeIdentifier5 "The FMI defines the type of failure detected in the subsystem identified by an SPN.The FMI defines the type of failure detected in the subsystem identified by an SPN.The FMI defines the type of failure detected in the subsystem identified by an SPN.The FMI defines the type of failure detected in the subsystem identified by an SPN.";
CM_ SG_ 3221225472 FailureModeIdentifier4 "The FMI defines the type of failure detected in the subsystem identified by an SPN.The FMI defines the type of failure detected in the subsystem identified by an SPN.The FMI defines the type of failure detected in the subsystem identified by an SPN.The FMI defines the type of failure detected in the subsystem identified by an SPN.";
CM_ SG_ 3221225472 FlashRedStopLamp "This parameter provides the capability to flash the RSL (SPN 3039).This parameter provides the capability to flash the RSL (SPN 3039).This parameter provides the capability to flash the RSL (SPN 3039).";
CM_ SG_ 3221225472 FlashProtectLamp "This parameter provides the capability to flash the engine protect lamp (SPN 3041).This parameter provides the capability to flash the engine protect lamp (SPN 3041).This parameter provides the capability to flash the engine protect lamp (SPN 3041).";
CM_ SG_ 3221225472 FlashMalfuncIndicatorLamp "This parameter provides the capability to flash the MIL (SPN 3038).This parameter provides the capability to flash the MIL (SPN 3038).This parameter provides the capability to flash the MIL (SPN 3038).";
CM_ SG_ 3221225472 FlashAmberWarningLamp "This parameter provides the capability to flash the AWL (SPN 3040). This parameter provides the capability to flash the AWL (SPN 3040). This parameter provides the capability to flash the AWL (SPN 3040). ";
CM_ SG_ 3221225472 FailureModeIdentifier3 "The FMI defines the type of failure detected in the subsystem identified by an SPN.The FMI defines the type of failure detected in the subsystem identified by an SPN.The FMI defines the type of failure detected in the subsystem identified by an SPN.The FMI defines the type of failure detected in the subsystem identified by an SPN.";
CM_ SG_ 3221225472 FailureModeIdentifier2 "The FMI defines the type of failure detected in the subsystem identified by an SPN.The FMI defines the type of failure detected in the subsystem identified by an SPN.The FMI defines the type of failure detected in the subsystem identified by an SPN.The FMI defines the type of failure detected in the subsystem identified by an SPN.";
CM_ SG_ 3221225472 FailureModeIdentifier1 "The FMI defines the type of failure detected in the subsystem identified by an SPN.The FMI defines the type of failure detected in the subsystem identified by an SPN.The FMI defines the type of failure detected in the subsystem identified by an SPN.The FMI defines the type of failure detected in the subsystem identified by an SPN.The FMI defines the type of failure detected in the subsystem identified by an SPN.The FMI defines the type of failure detected in the subsystem identified by an SPN.The FMI defines the type of failure detected in the subsystem identified by an SPN.The FMI defines the type of failure detected in the subsystem identified by an SPN.";
CM_ SG_ 3221225472 SPN1 "SPN #1 (Conversion Version 4)SPN #1 (Conversion Version 4)SPN #1 (Conversion Version 4)SPN #1 (Conversion Version 4)SPN #1 (Conversion Version 4)SPN #1 (Conversion Version 4)SPN #1 (Conversion Version 4)";
CM_ SG_ 3221225472 MalfunctionIndicatorLampStatus "A lamp used to relay only emissions-related trouble code information.A lamp used to relay only emissions-related trouble code information.A lamp used to relay only emissions-related trouble code information.";
CM_ SG_ 3221225472 RedStopLampState "This lamp is uesed to relay trouble code information that is of a severe enought condition that it warrants stopping the vehicle.This lamp is uesed to relay trouble code information that is of a severe enought condition that it warrants stopping the vehicle.This lamp is uesed to relay trouble code information that is of a severe enought condition that it warrants stopping the vehicle.";
CM_ SG_ 3221225472 AmberWarningLampStatus "This lamp is used to relay trouble code information that is reporting a problem with the vehicle system but the vehicle need
not be immediately stopped.This lamp is used to relay trouble code information that is reporting a problem with the vehicle system but the vehicle need
not be immediately stopped.This lamp is used to relay trouble code information that is reporting a problem with the vehicle system but the vehicle need
not be immediately stopped.";
CM_ SG_ 3221225472 ProtectLampStatus "This lamp is used to relay trouble code informatio that is reporting a problem with a vehicle system that is most
probably not electronic subsystem related.This lamp is used to relay trouble code informatio that is reporting a problem with a vehicle system that is most
probably not electronic subsystem related.This lamp is used to relay trouble code informatio that is reporting a problem with a vehicle system that is most
probably not electronic subsystem related.";
CM_ SG_ 3221225472 SPN5High "SPN #5 (Conversion Version 4)SPN #5 (Conversion Version 4)SPN #5 (Conversion Version 4)SPN #5 (Conversion Version 4)";
CM_ SG_ 3221225472 SPN4High "SPN #4 (Conversion Version 4)SPN #4 (Conversion Version 4)SPN #4 (Conversion Version 4)SPN #4 (Conversion Version 4)";
CM_ SG_ 3221225472 SPN3High "SPN #3 (Conversion Version 4)SPN #3 (Conversion Version 4)SPN #3 (Conversion Version 4)SPN #3 (Conversion Version 4)";
CM_ SG_ 3221225472 SPN2High "SPN #2 (Conversion Version 4)SPN #2 (Conversion Version 4)SPN #2 (Conversion Version 4)SPN #2 (Conversion Version 4)";
CM_ SG_ 3221225472 SPN1High "SPN #1 (Conversion Version 4)SPN #1 (Conversion Version 4)SPN #1 (Conversion Version 4)SPN #1 (Conversion Version 4)SPN #1 (Conversion Version 4)SPN #1 (Conversion Version 4)SPN #1 (Conversion Version 4)SPN #1 (Conversion Version 4)";
CM_ SG_ 3221225472 LocalMinuteOffset "Local offset in minutes from a reference time.";
CM_ SG_ 3221225472 Year "Part of a parameter used to represent a calendar date.";
CM_ SG_ 3221225472 Day "Part of a parameter used to represent a calendar date.";
CM_ SG_ 3221225472 Month "Part of a parameter used to represent a calendar date.";
CM_ SG_ 3221225472 Hours "Part of a parameter used to represent time.";
CM_ SG_ 3221225472 Minutes "Part of a parameter used to represent time.";
CM_ SG_ 3221225472 Seconds "Part of a parameter used to represent time.";
CM_ SG_ 3221225472 ControlPurpose "State signal which indicates which control mode the sending device is using to generate the TSC1 command.State signal which indicates which control mode the sending device is using to generate the TSC1 command.State signal which indicates which control mode the sending device is using to generate the TSC1 command.State signal which indicates which control mode the sending device is using to generate the TSC1 command.State signal which indicates which control mode the sending device is using to generate the TSC1 command.State signal which indicates which control mode the sending device is using to generate the TSC1 command.";
CM_ SG_ 3221225472 TransmissionRate "This parameter indicates the transmission rate at which the sending device will transmit the TSC1 message.This parameter indicates the transmission rate at which the sending device will transmit the TSC1 message.This parameter indicates the transmission rate at which the sending device will transmit the TSC1 message.This parameter indicates the transmission rate at which the sending device will transmit the TSC1 message.This parameter indicates the transmission rate at which the sending device will transmit the TSC1 message.This parameter indicates the transmission rate at which the sending device will transmit the TSC1 message.";
CM_ SG_ 3221225472 EngRqedTorque_TorqueLimit "Parameter provided to the engine or retarder in the torque/speed control message for controlling or limiting the output torque.Parameter provided to the engine or retarder in the torque/speed control message for controlling or limiting the output torque.Parameter provided to the engine or retarder in the torque/speed control message for controlling or limiting the output torque.Parameter provided to the engine or retarder in the torque/speed control message for controlling or limiting the output torque.";
CM_ SG_ 3221225472 EngRqedSpeed_SpeedLimit "Parameter provided to the engine from external sources in the torque/speed control message.Parameter provided to the engine from external sources in the torque/speed control message.Parameter provided to the engine from external sources in the torque/speed control message.Parameter provided to the engine from external sources in the torque/speed control message.";
CM_ SG_ 3221225472 EngRqedSpeedCtrlConditions "This mode tells the engine control system the governor characteristics that are desired during speed control.This mode tells the engine control system the governor characteristics that are desired during speed control.This mode tells the engine control system the governor characteristics that are desired during speed control.This mode tells the engine control system the governor characteristics that are desired during speed control.";
CM_ SG_ 3221225472 EngRqed_TorqueLimit "Parameter provided to the engine or retarder in the torque/speed control message for controlling or limiting the output torque.Parameter provided to the engine or retarder in the torque/speed control message for controlling or limiting the output torque.";
CM_ SG_ 3221225472 EngRqed_SpeedLimit "Parameter provided to the engine from external sources in the torque/speed control message.Parameter provided to the engine from external sources in the torque/speed control message.";
CM_ SG_ 3221225472 EngRqedSpeedCtrlCond "This mode tells the engine control system the governor characteristics that are desired during speed control.This mode tells the engine control system the governor characteristics that are desired during speed control.";
CM_ SG_ 3221225472 TestLimitMinimum "The threshold which the test value must be above to pass the test.The threshold which the test value must be above to pass the test.The threshold which the test value must be above to pass the test.The threshold which the test value must be above to pass the test.";
CM_ SG_ 3221225472 TestLimitMaximum "The threshold which the test value must be below to pass the test.The threshold which the test value must be below to pass the test.The threshold which the test value must be below to pass the test.The threshold which the test value must be below to pass the test.";
CM_ SG_ 3221225472 TestValue "The test value collected during the test.The test value collected during the test.The test value collected during the test.The test value collected during the test.";
CM_ SG_ 3221225472 TestType "Identifies the non-continously monitored component identifier that was tested.Identifies the non-continously monitored component identifier that was tested.";
CM_ SG_ 3221225472 TestIdentifier "Designates the test to be run.Designates the test to be run.Designates the test to be run.Designates the test to be run.";
CM_ SG_ 3221225472 SlotId "The SLOT Identifer is used to determine the multiplier and offset to be used to scale the test value.The SLOT Identifer is used to determine the multiplier and offset to be used to scale the test value.";
CM_ SG_ 3221225472 ReferenceRetarderTorque "This parameter is the 100% reference value for all defined indicated retarder torque parameters.";
CM_ SG_ 3221225472 RetarderSpeedAtPoint4 "Retarder speed of point 4 of the engine retarder torque map.";
CM_ SG_ 3221225472 RetarderSpeedAtPoint3 "Retarder speed of point 3 of the engine retarder torque map.";
CM_ SG_ 3221225472 PercentTorqueAtMaxSpeedPoint2 "The torque limit that indicates the available retarder torque which can be provided by the retarder at its maximum speed.";
CM_ SG_ 3221225472 MaxRetarderSpeedPoint2 "Maximum speed of retarder (Please reference PGN 65249).";
CM_ SG_ 3221225472 PercentTorqueAtIdlePoint1 "The torque limit that indicates the available retarder torque which can be provided by the retarder at idle speed.";
CM_ SG_ 3221225472 RetarderCtrlMethod "This parameter identifies the number of steps used by the retarder.";
CM_ SG_ 3221225472 RetarderType "A vehicle retarder is a supplementary device to the wheel brakes for the driver to better control the vehicle.";
CM_ SG_ 3221225472 ActlMxAvlblRtarderPercentTorque "This is the maximum amount of torque that the retarder can immediately deliver.";
CM_ SG_ 3221225472 SrcAddrssOfCtrllngDvcFrRtrdrCtrl "The source address of the SAE J1939 device currently controlling the retarder.";
CM_ SG_ 3221225472 EngCoolantLoadIncrease "Status of an event, external to the engine, that may increase the nominal temperature of the engine coolant liquid.";
CM_ SG_ 3221225472 IntendedRetarderPercentTorque "Braking torque of retarder that the retarder is currently trying to achieve.";
CM_ SG_ 3221225472 ActualRetarderPercentTorque "Actual braking torque of the retarder as a percent of retarder configuration reference torque SPN 556.";
CM_ SG_ 3221225472 RetarderEnableShiftAssistSwitch "Switch signal which indicates whether the operator wishes the retarder to be enabled for transmission shift assist.";
CM_ SG_ 3221225472 RetarderEnableBrakeAssistSwitch "Switch signal which indicates whether the operator wishes the retarder to be enabled for vehicle braking assist.";
CM_ SG_ 3221225472 RetarderTorqueMode "State signal which indicates which retarder torque mode is currently generating, limiting, or controlling the torque.";
CM_ BO_ 2566836478 "Test results for non-continously monitored systems.";
CM_ SG_ 2566836478 TestLimitMinimum "The threshold which the test value must be above to pass the test.";
CM_ SG_ 2566836478 TestLimitMaximum "The threshold which the test value must be below to pass the test.";
CM_ SG_ 2566836478 TestValue "The test value collected during the test.";
CM_ SG_ 2566836478 TestType "Identifies the non-continously monitored component identifier that was tested.";
CM_ SG_ 2566836478 TestIdentifier "Designates the test to be run.";
CM_ BO_ 2565078782 "Command non-continously monitored test";
CM_ SG_ 2565078782 SPN1High "SPN #1 (Conversion Version 4)";
CM_ SG_ 2565078782 SPN1 "SPN #1 (Conversion Version 4)";
CM_ SG_ 2565078782 TestIdentifier "Designates the test to be run.";
CM_ SG_ 2565078782 FailureModeIdentifier1 "The FMI defines the type of failure detected in the subsystem identified by an SPN.";
CM_ BO_ 2560950014 "This message conveys the scaled test results for the applicable test requested in DM7.";
CM_ SG_ 2560950014 TestLimitMinimum "The threshold which the test value must be above to pass the test.";
CM_ SG_ 2560950014 TestLimitMaximum "The threshold which the test value must be below to pass the test.";
CM_ SG_ 2560950014 TestValue "The test value collected during the test.";
CM_ SG_ 2560950014 SlotId "The SLOT Identifer is used to determine the multiplier and offset to be used to scale the test value.";
CM_ SG_ 2560950014 TestIdentifier "Designates the test to be run.";
CM_ SG_ 2560950014 FailureModeIdentifier1 "The FMI defines the type of failure detected in the subsystem identified by an SPN.";
CM_ SG_ 2560950014 SPN1High "SPN #1 (Conversion Version 4)";
CM_ SG_ 2560950014 SPN1 "SPN #1 (Conversion Version 4)";
CM_ BO_ 2348941054 "Transmission Control 1";
CM_ SG_ 2348941054 TrnsShftSlctorDisplayModeSwitch "Status of the operator’s switch used to ‘toggle’ through multiple display modes of a shift selector display.";
CM_ SG_ 2348941054 TransMode4 "Indicates whether transmission mode 4 is enabled.";
CM_ SG_ 2348941054 TransMode3 "Indicates whether transmission mode 3 is enabled.";
CM_ SG_ 2348941054 TransMode2 "Indicates whether transmission mode 2 is enabled.";
CM_ SG_ 2348941054 TransMode1 "Indicates whether transmission mode 1 is enabled.";
CM_ SG_ 2348941054 DisengageDiffLockRqCentralRear "Command signal used to disengage the various differential locks, e.";
CM_ SG_ 2348941054 DisengageDiffLockRqCentralFront "Command signal used to disengage the various differential locks, e.";
CM_ SG_ 2348941054 DisengageDiffLockRqCentral "Command signal used to disengage the various differential locks, e.";
CM_ SG_ 2348941054 DisengageDiffLockRqRearAxle2 "Command signal used to disengage the various differential locks, e.";
CM_ SG_ 2348941054 DisengageDiffLockRqRearAxle1 "Command signal used to disengage the various differential locks, e.";
CM_ SG_ 2348941054 DisengageDiffLockRqFrontAxle2 "Command signal used to disengage the various differential locks, e.";
CM_ SG_ 2348941054 DisengageDiffLockRqFrontAxle1 "Command signal used to disengage the various differential locks, e.";
CM_ SG_ 2348941054 TransRqedGear "Gear requested by the operator, ABS, or engine.";
CM_ SG_ 2348941054 RqedPercentClutchSlip "Parameter which represents the percent clutch slip requested by a device.";
CM_ SG_ 2348941054 DisengageDrivelineRq "Command signal used to simply disengage the driveline, e.";
CM_ SG_ 2348941054 TorqueConverterLockupDisableRq "Command signal to prevent torque converter lockup, which may cause problems in certain circumstances for ASR.";
CM_ SG_ 2348941054 TransGearShiftInhibitRq "Command signal to inhibit gear shifts.";
CM_ BO_ 2562981630 "Individual Clear/Reset of active and previously active DTC.";
CM_ SG_ 2562981630 SPN1 "SPN #1 (Conversion Version 4)";
CM_ SG_ 2562981630 SPN1High "SPN #1 (Conversion Version 4)";
CM_ SG_ 2562981630 FailureModeIdentifier1 "The FMI defines the type of failure detected in the subsystem identified by an SPN.";
CM_ BO_ 2348875518 "Torque/Speed Control 1";
CM_ SG_ 2348875518 ControlPurpose "State signal which indicates which control mode the sending device is using to generate the TSC1 command.";
CM_ SG_ 2348875518 TransmissionRate "This parameter indicates the transmission rate at which the sending device will transmit the TSC1 message.";
CM_ SG_ 2348875518 EngRqedTorque_TorqueLimit "Parameter provided to the engine or retarder in the torque/speed control message for controlling or limiting the output torque.";
CM_ SG_ 2348875518 EngRqedSpeed_SpeedLimit "Parameter provided to the engine from external sources in the torque/speed control message.";
CM_ SG_ 2348875518 EngRqedSpeedCtrlConditions "This mode tells the engine control system the governor characteristics that are desired during speed control.";
CM_ BO_ 2566840830 "Retarder Configuration";
CM_ SG_ 2566840830 ReferenceRetarderTorque "This parameter is the 100% reference value for all defined indicated retarder torque parameters.";
CM_ SG_ 2566840830 RetarderSpeedAtPoint4 "Retarder speed of point 4 of the engine retarder torque map.";
CM_ SG_ 2566840830 RetarderSpeedAtPoint3 "Retarder speed of point 3 of the engine retarder torque map.";
CM_ SG_ 2566840830 PercentTorqueAtMaxSpeedPoint2 "The torque limit that indicates the available retarder torque which can be provided by the retarder at its maximum speed.";
CM_ SG_ 2566840830 MaxRetarderSpeedPoint2 "Maximum speed of retarder (Please reference PGN 65249).";
CM_ SG_ 2566840830 PercentTorqueAtIdlePoint1 "The torque limit that indicates the available retarder torque which can be provided by the retarder at idle speed.";
CM_ SG_ 2566840830 RetarderCtrlMethod "This parameter identifies the number of steps used by the retarder.";
CM_ SG_ 2566840830 RetarderType "A vehicle retarder is a supplementary device to the wheel brakes for the driver to better control the vehicle.";
CM_ BO_ 2565865726 "Electronic Retarder Controller 1";
CM_ SG_ 2565865726 ActlMxAvlblRtarderPercentTorque "This is the maximum amount of torque that the retarder can immediately deliver.";
CM_ SG_ 2565865726 SrcAddrssOfCtrllngDvcFrRtrdrCtrl "The source address of the SAE J1939 device currently controlling the retarder.";
CM_ SG_ 2565865726 EngCoolantLoadIncrease "Status of an event, external to the engine, that may increase the nominal temperature of the engine coolant liquid.";
CM_ SG_ 2565865726 IntendedRetarderPercentTorque "Braking torque of retarder that the retarder is currently trying to achieve.";
CM_ SG_ 2565865726 ActualRetarderPercentTorque "Actual braking torque of the retarder as a percent of retarder configuration reference torque SPN 556.";
CM_ SG_ 2565865726 RetarderEnableShiftAssistSwitch "Switch signal which indicates whether the operator wishes the retarder to be enabled for transmission shift assist.";
CM_ SG_ 2565865726 RetarderEnableBrakeAssistSwitch "Switch signal which indicates whether the operator wishes the retarder to be enabled for vehicle braking assist.";
CM_ SG_ 2565865726 RetarderTorqueMode "State signal which indicates which retarder torque mode is currently generating, limiting, or controlling the torque.";
CM_ BO_ 2566846206 "Inlet/Exhaust Conditions 1";
CM_ SG_ 2566846206 EngExhaustGasTemp "Temperature of combustion byproducts leaving the engine.";
CM_ SG_ 2566846206 EngAirInletPress "Absolute air pressure at inlet to intake manifold or air box.";
CM_ SG_ 2566846206 EngIntakeManifold1Temp "Temperature of pre-combustion air found in intake manifold of engine air supply system.";
CM_ SG_ 2566846206 EngTurboBoostPress "Gage pressure of air measured downstream on the compressor discharge side of the turbocharger.";
CM_ SG_ 2566846206 EngParticulateTrapInletPress "Exhaust back pressure as a result of particle accumulation on filter media placed in the exhaust stream.";
CM_ BO_ 2566841854 "Engine Hours, Revolutions";
CM_ SG_ 2566841854 EngTotalRevolutions "Accumulated number of revolutions of engine crankshaft during its operation.";
CM_ SG_ 2566841854 EngTotalHoursOfOperation "Accumulated time of operation of engine.";
CM_ BO_ 2566843134 "Vehicle Weight";
CM_ SG_ 2566843134 CargoWeight "The mass of freight carried.";
CM_ SG_ 2566843134 TrailerWeight "Total mass of freight-carrying vehicle designed to be pulled by truck, including the weight of the contents.";
CM_ SG_ 2566843134 AxleWeight "Total mass imposed by the tires on the road surface at the specified axle.";
CM_ SG_ 2566843134 AxleLocation "To identify to which of several similar devices (such as tires or fuel tanks) the information applies.";
CM_ BO_ 2566843646 "Vehicle Identification";
CM_ SG_ 2566843646 VehicleIdentificationNumber "Vehicle Identification Number";
CM_ BO_ 2566832638 "High Resolution Vehicle Distance";
CM_ SG_ 2566832638 HighResolutionTripDistance "Distance traveled during all or part of a journey.";
CM_ SG_ 2566832638 HghRslutionTotalVehicleDistance "Accumulated distance traveled by the vehicle during its operation.";
CM_ BO_ 2565868030 "Vehicle Dynamic Stability Control 2";
CM_ SG_ 2565868030 LongitudinalAcceleration "Indicates the longitudinal acceleration of the vehicle.";
CM_ SG_ 2565868030 LateralAcceleration "Indicates a lateral acceleration of the vehicle.";
CM_ SG_ 2565868030 YawRate "Indicates the rotation about the vertical axis.";
CM_ SG_ 2565868030 SteerWheelTurnCounter "Indicates number of steering wheel turns, absolute position or relative position at ignition on.";
CM_ SG_ 2565868030 SteerWheelAngle "The main operator`s steering wheel angle (on the steering column, not the actual wheel angle).";
CM_ BO_ 2566803454 "Vehicle Dynamic Stability Control 1";
CM_ SG_ 2566803454 YCBrakeCtrlActive "State signal which indicates that Yaw Control (YC) has activated brake control.";
CM_ SG_ 2566803454 YCEngCtrlActive "State Signal which indicates that the Yaw Control (YC) has commanded engine control to be active.";
CM_ SG_ 2566803454 ROPBrakeCtrlActive "State signal which indicates that Roll over Prevention (ROP) has activated brake control.";
CM_ SG_ 2566803454 ROPEngCtrlActive "State Signal which indicates that the Roll Over Prevention (ROP) has commanded engine control to be active.";
CM_ SG_ 2566803454 VDCFullyOperational "Signal that indicates whether VDC is fully operational or whether its functionality is reduced by a permanent or temporary (e.";
CM_ SG_ 2566803454 VDCInformationSignal "This parameter commands the VDC information signal, for example a dash lamp.";
CM_ BO_ 2566840574 "Vehicle Distance";
CM_ SG_ 2566840574 TotalVehicleDistance "Accumulated distance traveled by vehicle during its operation.";
CM_ SG_ 2566840574 TripDistance "Distance traveled during all or part of a journey.";
CM_ BO_ 2561605374 "Tire Pressure Reference Setting";
CM_ SG_ 2561605374 TireLocation "Identifies which tire is associated with the parametric data in this PGN.";
CM_ BO_ 2566765054 "Tire Pressure Reference Information";
CM_ SG_ 2566765054 TireLocation "Identifies which tire is associated with the parametric data in this PGN.";
CM_ BO_ 2566845694 "Tire Condition";
CM_ SG_ 2566845694 TireTemp_21 "Temperature at the surface of the tire sidewall. (SP242)";
CM_ SG_ 2566845694 TireTemp_20 "Temperature at the surface of the tire sidewall. (SP242)";
CM_ SG_ 2566845694 TireTemp_11 "Temperature at the surface of the tire sidewall. (SP242)";
CM_ SG_ 2566845694 TireTemp_10 "Temperature at the surface of the tire sidewall. (SP242)";
CM_ SG_ 2566845694 TireTemp_01 "Temperature at the surface of the tire sidewall. (SP242)";
CM_ SG_ 2566845694 TireTemp_00 "Temperature at the surface of the tire sidewall. (SP242)";
CM_ SG_ 2566845694 TirePressThresholdDetection_21 "Signal indicating the pressure level of the tire. (SP2587)";
CM_ SG_ 2566845694 TirePressThresholdDetection_20 "Signal indicating the pressure level of the tire. (SP2587)";
CM_ SG_ 2566845694 TirePressThresholdDetection_11 "Signal indicating the pressure level of the tire. (SP2587)";
CM_ SG_ 2566845694 TirePressThresholdDetection_10 "Signal indicating the pressure level of the tire. (SP2587)";
CM_ SG_ 2566845694 TirePressThresholdDetection_01 "Signal indicating the pressure level of the tire. (SP2587)";
CM_ SG_ 2566845694 TirePressThresholdDetection_00 "Signal indicating the pressure level of the tire. (SP2587)";
CM_ SG_ 2566845694 TirePress_21 "Pressure at which air is contained in cavity formed by tire and rim. (SP241)";
CM_ SG_ 2566845694 TirePress_20 "Pressure at which air is contained in cavity formed by tire and rim. (SP241)";
CM_ SG_ 2566845694 TirePress_11 "Pressure at which air is contained in cavity formed by tire and rim. (SP241)";
CM_ SG_ 2566845694 TirePress_10 "Pressure at which air is contained in cavity formed by tire and rim. (SP241)";
CM_ SG_ 2566845694 TirePress_01 "Pressure at which air is contained in cavity formed by tire and rim. (SP241)";
CM_ SG_ 2566845694 TirePress_00 "Pressure at which air is contained in cavity formed by tire and rim. (SP241)";
CM_ SG_ 2566845694 TireAirLeakageRate_21 "The pressure loss rate of a tire. (SP2586)";
CM_ SG_ 2566845694 TireAirLeakageRate_20 "The pressure loss rate of a tire. (SP2586)";
CM_ SG_ 2566845694 TireAirLeakageRate_11 "The pressure loss rate of a tire. (SP2586)";
CM_ SG_ 2566845694 TireAirLeakageRate_10 "The pressure loss rate of a tire. (SP2586)";
CM_ SG_ 2566845694 TireAirLeakageRate_01 "The pressure loss rate of a tire. (SP2586)";
CM_ SG_ 2566845694 TireAirLeakageRate_00 "The pressure loss rate of a tire. (SP2586)";
CM_ SG_ 2566845694 CTIWheelSensorStatus_21 "Indicates whether the wheel is being monitored by the CTI controller. (SP1699)";
CM_ SG_ 2566845694 CTIWheelSensorStatus_20 "Indicates whether the wheel is being monitored by the CTI controller. (SP1699)";
CM_ SG_ 2566845694 CTIWheelSensorStatus_11 "Indicates whether the wheel is being monitored by the CTI controller. (SP1699)";
CM_ SG_ 2566845694 CTIWheelSensorStatus_10 "Indicates whether the wheel is being monitored by the CTI controller. (SP1699)";
CM_ SG_ 2566845694 CTIWheelSensorStatus_01 "Indicates whether the wheel is being monitored by the CTI controller. (SP1699)";
CM_ SG_ 2566845694 CTIWheelSensorStatus_00 "Indicates whether the wheel is being monitored by the CTI controller. (SP1699)";
CM_ SG_ 2566845694 CTIWheelEndElectricalFault_21 "Indicates the status of electrical fault on CTI wheel interface. (SP1697)";
CM_ SG_ 2566845694 CTIWheelEndElectricalFault_20 "Indicates the status of electrical fault on CTI wheel interface. (SP1697)";
CM_ SG_ 2566845694 CTIWheelEndElectricalFault_11 "Indicates the status of electrical fault on CTI wheel interface. (SP1697)";
CM_ SG_ 2566845694 CTIWheelEndElectricalFault_10 "Indicates the status of electrical fault on CTI wheel interface. (SP1697)";
CM_ SG_ 2566845694 CTIWheelEndElectricalFault_01 "Indicates the status of electrical fault on CTI wheel interface. (SP1697)";
CM_ SG_ 2566845694 CTIWheelEndElectricalFault_00 "Indicates the status of electrical fault on CTI wheel interface. (SP1697)";
CM_ SG_ 2566845694 CTITireStatus_21 "Indicates the status of the tire. (SP1698)";
CM_ SG_ 2566845694 CTITireStatus_20 "Indicates the status of the tire. (SP1698)";
CM_ SG_ 2566845694 CTITireStatus_11 "Indicates the status of the tire. (SP1698)";
CM_ SG_ 2566845694 CTITireStatus_10 "Indicates the status of the tire. (SP1698)";
CM_ SG_ 2566845694 CTITireStatus_01 "Indicates the status of the tire. (SP1698)";
CM_ SG_ 2566845694 CTITireStatus_00 "Indicates the status of the tire. (SP1698)";
CM_ SG_ 2566845694 TireLocation "Identifies which tire is associated with the parametric data in this PGN.";
CM_ BO_ 2566842110 "Time/Date";
CM_ SG_ 2566842110 LocalMinuteOffset "Local offset in minutes from a reference time.";
CM_ SG_ 2566842110 Year "Part of a parameter used to represent a calendar date.";
CM_ SG_ 2566842110 Day "Part of a parameter used to represent a calendar date.";
CM_ SG_ 2566842110 Month "Part of a parameter used to represent a calendar date.";
CM_ SG_ 2566842110 Hours "Part of a parameter used to represent time.";
CM_ SG_ 2566842110 Minutes "Part of a parameter used to represent time.";
CM_ SG_ 2566842110 Seconds "Part of a parameter used to represent time.";
CM_ BO_ 2365484286 "Tachograph";
CM_ SG_ 2365484286 TachographVehicleSpeed "Speed of the vehicle registered by the tachograph.";
CM_ SG_ 2365484286 TachographOutputShaftSpeed "Calculated speed of the transmission output shaft.";
CM_ SG_ 2365484286 DirectionIndicator "Indicates the direction of the vehicle.";
CM_ SG_ 2365484286 HandlingInformation "Indicates that handling information is present.";
CM_ SG_ 2365484286 SystemEvent "Indicates that a tachograph event has occurred.";
CM_ SG_ 2365484286 Driver2TimeRelatedStates "Indicates if the driver approaches or exceeds working time limits (or other limits).";
CM_ SG_ 2365484286 Overspeed "Indicates whether the vehicle is exceeding the legal speed limit set in the tachograph.";
CM_ SG_ 2365484286 Driver1TimeRelatedStates "Indicates if the driver approaches or exceeds working time limits (or other limits).";
CM_ SG_ 2365484286 DriveRecognize "Indicates whether motion of the vehicle is detected or not.";
CM_ SG_ 2365484286 Driver2WorkingState "State of work of the driver.";
CM_ SG_ 2365484286 Driver1WorkingState "State of work of the driver.";
CM_ BO_ 2566802430 "Transmission Configuration 2";
CM_ BO_ 2566841086 "Transmission Configuration";
CM_ SG_ 2566841086 NumberOfForwardGearRatios "Number of forward gear ratios in the transmission, provided as part of the configuration.";
CM_ SG_ 2566841086 NumberOfReverseGearRatios "Number of reverse gear ratios in the transmission, provided as part of the transmission configuration.";
CM_ BO_ 2566839806 "Turbocharger";
CM_ SG_ 2566839806 EngTurbo1Speed "Rotational velocity of rotor in the turbocharger.";
CM_ SG_ 2566839806 EngTurboLubeOilPress1 "Gage pressure of oil in turbocharger lubrication system.";
CM_ BO_ 2566775550 "Supply Pressure Demand";
CM_ SG_ 2566775550 AirSuspensionSupplyPressRq "Command signal to influence the pneumatic pressure in the circuit for the electronically controlled air suspension system.";
CM_ SG_ 2566775550 AuxEquipmentSupplyPressRq "Command signal to influence the pneumatic pressure in the auxiliary circuit.";
CM_ SG_ 2566775550 ServiceBrakeAirPressRqCircuit2 "Command signal to influence the pneumatic pressure in the service brake circuit or reservoir #2.";
CM_ SG_ 2566775550 ServiceBrakeAirPressRqCircuit1 "Command signal to influence the pneumatic pressure in the service brake circuit or reservoir #1.";
CM_ SG_ 2566775550 ParkingAnd_OrTrailerAirPressRq "Command signal to influence the pneumatic pressure in the circuit or reservoir for the parking brake and/or the trailer supply.";
CM_ SG_ 2566775550 PneumaticSupplyPressRq "Command signal to influence the pneumatic pressure in the main reservoir.";
CM_ BO_ 2566839038 "Software Identification";
CM_ SG_ 2566839038 SoftwareID3 "Software ID";
CM_ SG_ 2566839038 SoftwareID2 "Software ID";
CM_ SG_ 2566839038 SoftwareID1 "Software ID";
CM_ SG_ 2566839038 NmbrOfSftwrIdentificationFields "Number of software identification designators represented in the software identification parameter group.";
CM_ BO_ 2566841598 "Shutdown";
CM_ SG_ 2566841598 EngOverspeedTest "The engine overspeed test signal as measured by the reporting ECM.";
CM_ SG_ 2566841598 EngAirShutoffCmdStatus "State signal which indicates when the Air Shutoff driver output is being driven.";
CM_ SG_ 2566841598 EngAlarmOutputCmdStatus "State signal which indicates when the Alarm driver output is being driven.";
CM_ SG_ 2566841598 EngAlarmAcknowledge "The Engine Alarm Acknowledge Input signal as measured by the reporting ECM.";
CM_ SG_ 2566841598 EngProtectionSystemConfig "Parameter which indicates the configuration of the engine shutdown system.";
CM_ SG_ 2566841598 EngProtectionSystemTimerState "Status signal which indicates the current mode of the engine protection system timer system.";
CM_ SG_ 2566841598 EngPrtectionSystemTimerOverride "Status signal which indicates the status of the override feature of the engine protection system timer.";
CM_ SG_ 2566841598 EngPrtctnSystmApprchingShutdown "Status signal which indicates that engine shutdown is imminent.";
CM_ SG_ 2566841598 EngPrtctionSystemHasShutdownEng "Status signal which indicates whether or not the engine protection system has shutdown the engine.";
CM_ SG_ 2566841598 RefrigerantHighPressSwitch "Switch signal which indicates the position of the high pressure switch in the coolant circuit of an air conditioning system.";
CM_ SG_ 2566841598 RefrigerantLowPressSwitch "Switch signal which indicates the position of the low pressure switch in the coolant circuit of an air conditioning system.";
CM_ SG_ 2566841598 EngIdleShutdownTimerFunction "Parameter which indicates the configuration of the idle shutdown timer system.";
CM_ SG_ 2566841598 EngIdleShutdownTimerState "Status signal which indicates the current mode of operation of the idle shutdown timer system.";
CM_ SG_ 2566841598 EngIdleShutdownTimerOverride "Status signal which indicates the status of the override feature of the idle shutdown timer system.";
CM_ SG_ 2566841598 EngIdleShutdownDriverAlertMode "Status signal which indicates the status of the driver alert mode of the idle shutdown timer system.";
CM_ SG_ 2566841598 EngIdleShutdownHasShutdownEng "Status signal which identifies whether or not the engine has been shutdown by the idle shutdown timer system.";
CM_ BO_ 2566832382 "Service Information";
CM_ SG_ 2566832382 ServiceComponentIdentificationB "Identification of component needing service.";
CM_ SG_ 2566832382 ServiceComponentIdentificationA "Identification of component needing service.";
CM_ SG_ 2566832382 SrvceDelay_OperationalTimeBased "The time in vehicle operational time until the next vehicle service inspection is required.";
CM_ SG_ 2566832382 ServiceDelay_CalendarTimeBased "The time in weeks until the next vehicle service inspection is required.";
CM_ SG_ 2566832382 ServiceDistance "The distance which can be traveled by the vehicle before the next service inspection is required.";
CM_ SG_ 2566832382 ServiceComponentIdentification "Identification of component needing service.";
CM_ BO_ 2566847486 "Retarder fluids";
CM_ SG_ 2566847486 HydRetarderOilTemp "Temperature of oil found in a hydraulic retarder.";
CM_ SG_ 2566847486 HydRetarderPress "Gage pressure of oil in hydraulic retarder system.";
CM_ BO_ 2631859966 "Reset";
CM_ SG_ 2631859966 EngBuildHoursReset "Command signal used to reset the engine rebuild hours.";
CM_ SG_ 2631859966 ServiceComponentIdentification "Identification of component needing service.";
CM_ SG_ 2631859966 TripGroup2Proprietary "Command signal used to reset proprietary parameters associated with a trip but not defined within this document.";
CM_ SG_ 2631859966 TripGroup1 "Command signal used to reset the PGNs and parameters as defined in Table SPN988_A.";
CM_ BO_ 2566844670 "Power Takeoff Information";
CM_ SG_ 2566844670 OperatorPTOMemorySelectSwitch "Measured state of the operator PTO memory select switch.";
CM_ SG_ 2566844670 EngPTOAccelerateSwitch "Switch signal of the PTO control activator which indicates that the activator is in the position \"accelerate\".";
CM_ SG_ 2566844670 EngPTOResumeSwitch "Switch signal of the PTO control activator which indicates that the activator is in the position \"resume\".";
CM_ SG_ 2566844670 EngPTOCoast_DecelerateSwitch "Switch signal of the PTO control activator which indicates that the activator is in the position \"coast/decelerate\".";
CM_ SG_ 2566844670 EngPTOSetSwitch "Switch signal of the PTO control activator which indicates that the activator is in the position \"set\".";
CM_ SG_ 2566844670 EngRmtPTOVriableSpeedCtrlSwitch "Switch signal which indicates that the remote PTO toggle switch is in the enabled (ON) position.";
CM_ SG_ 2566844670 EngRmtPTOPrprgrmmdSpdCtrlSwitch "Switch signal which indicates that the remote PTO toggle switch is in the enabled (ON) position.";
CM_ SG_ 2566844670 PowerTakeoffSetSpeed "Rotational velocity selected by operator for device used to transmit engine power to auxiliary equipment.";
CM_ SG_ 2566844670 PowerTakeoffSpeed "Rotational velocity of device used to transmit engine power to auxiliary equipment.";
CM_ SG_ 2566844670 PowerTakeoffOilTemp "Temperature of lubricant in device used to transmit engine power to auxiliary equipment.";
CM_ SG_ 2566844670 RmtPTOPrprgrmmdSpeedCtrlSwitch2 "Switch signal which indicates that the remote PTO toggle switch #2 is in the enabled (ON) position.";
CM_ SG_ 2566844670 AuxInputIgnoreSwitch "Switch signal which overrides other switch input's ability to kick out of an engine's operating condition.";
CM_ BO_ 2566845182 "Fuel Economy (Liquid)";
CM_ SG_ 2566845182 EngAverageFuelEconomy "Average of instantaneous fuel economy for that segment of vehicle operation of interest.";
CM_ SG_ 2566845182 EngInstantaneousFuelEconomy "Current fuel economy at current vehicle velocity.";
CM_ SG_ 2566845182 EngFuelRate "Amount of fuel consumed by engine per unit of time.";
CM_ SG_ 2566845182 EngThrottlePos "The position of the valve used to regulate the supply of a fluid, usually air or fuel/air mixture, to an engine.";
CM_ BO_ 2566842878 "Fuel Consumption (Liquid)";
CM_ SG_ 2566842878 EngTotalFuelUsed "Accumulated amount of fuel used during vehicle operation.";
CM_ SG_ 2566842878 EngTripFuel "Fuel consumed during all or part of a journey.";
CM_ BO_ 2566831614 "Fan Drive";
CM_ SG_ 2566831614 FanSpeed "The speed of the fan associated with engine coolant system.";
CM_ SG_ 2566831614 FanDriveState "This parameter is used to indicate the current state or mode of operation by the fan drive.";
CM_ SG_ 2566831614 EstPercentFanSpeed "Estimated fan speed as a ratio of the fan drive (current speed) to the fully engaged fan drive (maximum fan speed).";
CM_ BO_ 2566802174 "Electronic Transmission Controller 7";
CM_ SG_ 2566802174 TransShiftInhibitIndicator "State signal indicating a transmission request for the Shift Inhibit Indicator to be active or inactive.";
CM_ SG_ 2566802174 TransEngCrankEnable "State signal from the transmission indicating if the transmission’s status is such that engine cranking is allowed (i.";
CM_ BO_ 2565867006 "Electronic Transmission Controller 2";
CM_ SG_ 2565867006 TransCurrentRange "Range currently being commanded by the transmission control system.";
CM_ SG_ 2565867006 TransRqedRange "Range selected by the operator.";
CM_ SG_ 2565867006 TransActualGearRatio "Actual ratio of input shaft speed to output shaft speed.";
BA_DEF_ SG_  "SigType" ENUM  "Default","Range","RangeSigned","ASCII","Discrete","Control","ReferencePGN","DTC","StringDelimiter","StringLength","StringLengthControl";
BA_DEF_ SG_  "GenSigStartValue" FLOAT 0 10000;
BA_DEF_ SG_  "GenSigSendType" ENUM  "Cyclic","OnWrite","OnWriteWithRepetition","OnChange","OnChangeWithRepetition","IfActive","IfActiveWithRepetition","NoSigSendType";
BA_DEF_ SG_  "GenSigILSupport" ENUM  "No","Yes";
BA_DEF_ BO_  "GenMsgILSupport" ENUM  "No","Yes";
BA_DEF_ SG_  "SPN" INT 0 524287;
BA_DEF_ BO_  "GenMsgRequestable" INT 0 1;
BA_DEF_ BO_  "GenMsgSendType" ENUM  "cyclic","NotUsed","NotUsed","NotUsed","NotUsed","NotUsed","NotUsed","IfActive","noMsgSendType";
BA_DEF_ BO_  "VFrameFormat" ENUM  "StandardCAN","ExtendedCAN","reserved","J1939PG";
BA_DEF_ BO_  "GenMsgCycleTime" INT 0 3600000;
BA_DEF_ BU_  "NodeLayerModules" STRING ;
BA_DEF_ BU_  "NmStationAddress" INT 0 255;
BA_DEF_ BU_  "NmJ1939AAC" INT 0 1;
BA_DEF_ BU_  "NmJ1939ManufacturerCode" INT 0 2047;
BA_DEF_  "DatabaseVersion" STRING ;
BA_DEF_  "BusType" STRING ;
BA_DEF_  "ProtocolType" STRING ;
BA_DEF_DEF_  "SigType" "Default";
BA_DEF_DEF_  "GenSigStartValue" 0;
BA_DEF_DEF_  "GenSigSendType" "NoSigSendType";
BA_DEF_DEF_  "GenSigILSupport" "Yes";
BA_DEF_DEF_  "GenMsgILSupport" "Yes";
BA_DEF_DEF_  "SPN" 0;
BA_DEF_DEF_  "GenMsgRequestable" 1;
BA_DEF_DEF_  "GenMsgSendType" "noMsgSendType";
BA_DEF_DEF_  "VFrameFormat" "J1939PG";
BA_DEF_DEF_  "GenMsgCycleTime" 0;
BA_DEF_DEF_  "NodeLayerModules" "";
BA_DEF_DEF_  "NmStationAddress" 254;
BA_DEF_DEF_  "NmJ1939AAC" 0;
BA_DEF_DEF_  "NmJ1939ManufacturerCode" 0;
BA_DEF_DEF_  "DatabaseVersion" "";
BA_DEF_DEF_  "BusType" "";
BA_DEF_DEF_  "ProtocolType" "";
BA_ "BusType" "CAN";
BA_ "ProtocolType" "J1939";
BA_ "DatabaseVersion" "7.0";
BA_ "NmStationAddress" BU_ Sender 10;
BA_ "NodeLayerModules" BU_ Sender "J1939_IL.vmodule";
BA_ "NmJ1939ManufacturerCode" BU_ Sender 1861;
BA_ "NmJ1939AAC" BU_ Sender 1;
BA_ "GenMsgCycleTime" BO_ 2565865726 100;
BA_ "GenMsgSendType" BO_ 2565865726 0;
BA_ "GenMsgSendType" BO_ 2566846206 0;
BA_ "GenMsgCycleTime" BO_ 2566846206 500;
BA_ "GenMsgSendType" BO_ 2566832638 0;
BA_ "GenMsgCycleTime" BO_ 2566832638 1000;
BA_ "GenMsgSendType" BO_ 2565868030 0;
BA_ "GenMsgCycleTime" BO_ 2565868030 10;
BA_ "GenMsgSendType" BO_ 2566803454 0;
BA_ "GenMsgCycleTime" BO_ 2566803454 100;
BA_ "GenMsgSendType" BO_ 2566840574 0;
BA_ "GenMsgCycleTime" BO_ 2566840574 100;
BA_ "GenMsgSendType" BO_ 2566845694 0;
BA_ "GenMsgCycleTime" BO_ 2566845694 100;
BA_ "GenMsgSendType" BO_ 2365484286 0;
BA_ "GenMsgCycleTime" BO_ 2365484286 50;
BA_ "GenMsgSendType" BO_ 2566839806 0;
BA_ "GenMsgCycleTime" BO_ 2566839806 1000;
BA_ "GenMsgSendType" BO_ 2566775550 2;
BA_ "GenMsgCycleTime" BO_ 2566775550 1000;
BA_ "GenMsgSendType" BO_ 2566841598 0;
BA_ "GenMsgCycleTime" BO_ 2566841598 1000;
BA_ "GenMsgSendType" BO_ 2566847486 0;
BA_ "GenMsgCycleTime" BO_ 2566847486 1000;
BA_ "GenMsgSendType" BO_ 2566844670 0;
BA_ "GenMsgCycleTime" BO_ 2566844670 100;
BA_ "GenMsgSendType" BO_ 2566845182 0;
BA_ "GenMsgCycleTime" BO_ 2566845182 100;
BA_ "GenMsgSendType" BO_ 2566831614 0;
BA_ "GenMsgCycleTime" BO_ 2566831614 1000;
BA_ "GenMsgSendType" BO_ 2566802174 0;
BA_ "GenMsgCycleTime" BO_ 2566802174 100;
BA_ "GenMsgSendType" BO_ 2565867006 0;
BA_ "GenMsgCycleTime" BO_ 2565867006 100;
BA_ "SigType" SG_ 3221225472 TireTemp 1;
BA_ "GenSigStartValue" SG_ 3221225472 TireTemp 9312;
BA_ "SPN" SG_ 3221225472 TireTemp 242;
BA_ "SigType" SG_ 3221225472 TirePress 1;
BA_ "SPN" SG_ 3221225472 TirePress 241;
BA_ "SPN" SG_ 3221225472 FlashRedStopLamp 3039;
BA_ "SPN" SG_ 3221225472 FlashProtectLamp 3041;
BA_ "SPN" SG_ 3221225472 FlashMalfuncIndicatorLamp 3038;
BA_ "SigType" SG_ 3221225472 FlashMalfuncIndicatorLamp 4;
BA_ "SPN" SG_ 3221225472 FlashAmberWarningLamp 3040;
BA_ "SPN" SG_ 3221225472 SPNConversionMethod1 1706;
BA_ "SPN" SG_ 3221225472 FailureModeIdentifier1 1215;
BA_ "SPN" SG_ 3221225472 SPN1 1214;
BA_ "SPN" SG_ 3221225472 MalfunctionIndicatorLampStatus 1213;
BA_ "SigType" SG_ 3221225472 MalfunctionIndicatorLampStatus 4;
BA_ "SPN" SG_ 3221225472 RedStopLampState 623;
BA_ "SigType" SG_ 3221225472 RedStopLampState 4;
BA_ "SPN" SG_ 3221225472 AmberWarningLampStatus 624;
BA_ "SigType" SG_ 3221225472 AmberWarningLampStatus 4;
BA_ "SPN" SG_ 3221225472 ProtectLampStatus 987;
BA_ "SigType" SG_ 3221225472 ProtectLampStatus 4;
BA_ "SPN" SG_ 3221225472 SPN1High 1214;
BA_ "SPN" SG_ 3221225472 LocalHourOffset 1602;
BA_ "SigType" SG_ 3221225472 LocalHourOffset 1;
BA_ "SPN" SG_ 3221225472 LocalMinuteOffset 1601;
BA_ "SigType" SG_ 3221225472 LocalMinuteOffset 1;
BA_ "SPN" SG_ 3221225472 Year 964;
BA_ "SigType" SG_ 3221225472 Year 1;
BA_ "SPN" SG_ 3221225472 Day 962;
BA_ "SigType" SG_ 3221225472 Day 1;
BA_ "SPN" SG_ 3221225472 Month 963;
BA_ "SigType" SG_ 3221225472 Month 1;
BA_ "SPN" SG_ 3221225472 Hours 961;
BA_ "SigType" SG_ 3221225472 Hours 1;
BA_ "SPN" SG_ 3221225472 Minutes 960;
BA_ "SigType" SG_ 3221225472 Minutes 1;
BA_ "SPN" SG_ 3221225472 Seconds 959;
BA_ "SigType" SG_ 3221225472 Seconds 1;
BA_ "SPN" SG_ 3221225472 ControlPurpose 3350;
BA_ "SigType" SG_ 3221225472 ControlPurpose 4;
BA_ "SPN" SG_ 3221225472 TransmissionRate 3349;
BA_ "SigType" SG_ 3221225472 TransmissionRate 4;
BA_ "SPN" SG_ 3221225472 EngRqedTorque_TorqueLimit 518;
BA_ "SigType" SG_ 3221225472 EngRqedTorque_TorqueLimit 1;
BA_ "SPN" SG_ 3221225472 EngRqedSpeed_SpeedLimit 898;
BA_ "SigType" SG_ 3221225472 EngRqedSpeed_SpeedLimit 1;
BA_ "SPN" SG_ 3221225472 OverrideCtrlModePriority 897;
BA_ "SigType" SG_ 3221225472 OverrideCtrlModePriority 4;
BA_ "SPN" SG_ 3221225472 EngRqedSpeedCtrlConditions 696;
BA_ "SigType" SG_ 3221225472 EngRqedSpeedCtrlConditions 4;
BA_ "SPN" SG_ 3221225472 EngOverrideCtrlMode 695;
BA_ "SigType" SG_ 3221225472 EngOverrideCtrlMode 4;
BA_ "SPN" SG_ 3221225472 EngRqed_TorqueLimit 518;
BA_ "SigType" SG_ 3221225472 EngRqed_TorqueLimit 1;
BA_ "SPN" SG_ 3221225472 EngRqed_SpeedLimit 898;
BA_ "SigType" SG_ 3221225472 EngRqed_SpeedLimit 1;
BA_ "SPN" SG_ 3221225472 OverrideCtrlModePrio 897;
BA_ "SigType" SG_ 3221225472 OverrideCtrlModePrio 4;
BA_ "SPN" SG_ 3221225472 EngRqedSpeedCtrlCond 696;
BA_ "SigType" SG_ 3221225472 EngRqedSpeedCtrlCond 4;
BA_ "SigType" SG_ 3221225472 TestLimitMinimum 1;
BA_ "SPN" SG_ 3221225472 TestLimitMinimum 1228;
BA_ "SigType" SG_ 3221225472 TestLimitMaximum 1;
BA_ "SPN" SG_ 3221225472 TestLimitMaximum 1227;
BA_ "SigType" SG_ 3221225472 TestValue 1;
BA_ "SPN" SG_ 3221225472 TestValue 1226;
BA_ "SigType" SG_ 3221225472 TestType 1;
BA_ "SPN" SG_ 3221225472 TestType 1225;
BA_ "SigType" SG_ 3221225472 TestIdentifier 1;
BA_ "SPN" SG_ 3221225472 TestIdentifier 1224;
BA_ "SigType" SG_ 3221225472 SlotId 1;
BA_ "SPN" SG_ 3221225472 SlotId 4109;
BA_ "SPN" SG_ 3221225472 PercentTorqueAtPeakTorquePoint5 555;
BA_ "SigType" SG_ 3221225472 PercentTorqueAtPeakTorquePoint5 1;
BA_ "SPN" SG_ 3221225472 ReferenceRetarderTorque 556;
BA_ "SigType" SG_ 3221225472 ReferenceRetarderTorque 1;
BA_ "SPN" SG_ 3221225472 RetarderSpeedAtPeakTorquePoint5 547;
BA_ "SigType" SG_ 3221225472 RetarderSpeedAtPeakTorquePoint5 1;
BA_ "SPN" SG_ 3221225472 PercentTorqueAtPoint4 554;
BA_ "SigType" SG_ 3221225472 PercentTorqueAtPoint4 1;
BA_ "SPN" SG_ 3221225472 RetarderSpeedAtPoint4 550;
BA_ "SigType" SG_ 3221225472 RetarderSpeedAtPoint4 1;
BA_ "SPN" SG_ 3221225472 PercentTorqueAtPoint3 553;
BA_ "SigType" SG_ 3221225472 PercentTorqueAtPoint3 1;
BA_ "SPN" SG_ 3221225472 RetarderSpeedAtPoint3 549;
BA_ "SigType" SG_ 3221225472 RetarderSpeedAtPoint3 1;
BA_ "SPN" SG_ 3221225472 PercentTorqueAtMaxSpeedPoint2 552;
BA_ "SigType" SG_ 3221225472 PercentTorqueAtMaxSpeedPoint2 1;
BA_ "SPN" SG_ 3221225472 MaxRetarderSpeedPoint2 548;
BA_ "SigType" SG_ 3221225472 MaxRetarderSpeedPoint2 1;
BA_ "SPN" SG_ 3221225472 PercentTorqueAtIdlePoint1 551;
BA_ "SigType" SG_ 3221225472 PercentTorqueAtIdlePoint1 1;
BA_ "SPN" SG_ 3221225472 RetarderSpeedAtIdlePoint1 546;
BA_ "SigType" SG_ 3221225472 RetarderSpeedAtIdlePoint1 1;
BA_ "SPN" SG_ 3221225472 RetarderCtrlMethod 557;
BA_ "SigType" SG_ 3221225472 RetarderCtrlMethod 1;
BA_ "SPN" SG_ 3221225472 RetarderLocation 902;
BA_ "SigType" SG_ 3221225472 RetarderLocation 4;
BA_ "SPN" SG_ 3221225472 RetarderType 901;
BA_ "SigType" SG_ 3221225472 RetarderType 4;
BA_ "SPN" SG_ 3221225472 RetarderSelectionNonEng 1716;
BA_ "SigType" SG_ 3221225472 RetarderSelectionNonEng 1;
BA_ "SPN" SG_ 3221225472 ActlMxAvlblRtarderPercentTorque 1717;
BA_ "SigType" SG_ 3221225472 ActlMxAvlblRtarderPercentTorque 1;
BA_ "SPN" SG_ 3221225472 DrvrsDmandRetarderPercentTorque 1715;
BA_ "SigType" SG_ 3221225472 DrvrsDmandRetarderPercentTorque 1;
BA_ "SPN" SG_ 3221225472 SrcAddrssOfCtrllngDvcFrRtrdrCtrl 1480;
BA_ "SigType" SG_ 3221225472 SrcAddrssOfCtrllngDvcFrRtrdrCtrl 1;
BA_ "SPN" SG_ 3221225472 RetarderRqingBrakeLight 1667;
BA_ "SigType" SG_ 3221225472 RetarderRqingBrakeLight 4;
BA_ "SPN" SG_ 3221225472 EngCoolantLoadIncrease 1082;
BA_ "SigType" SG_ 3221225472 EngCoolantLoadIncrease 4;
BA_ "SPN" SG_ 3221225472 IntendedRetarderPercentTorque 1085;
BA_ "SigType" SG_ 3221225472 IntendedRetarderPercentTorque 1;
BA_ "SPN" SG_ 3221225472 ActualRetarderPercentTorque 520;
BA_ "SigType" SG_ 3221225472 ActualRetarderPercentTorque 1;
BA_ "SPN" SG_ 3221225472 RetarderEnableShiftAssistSwitch 572;
BA_ "SigType" SG_ 3221225472 RetarderEnableShiftAssistSwitch 4;
BA_ "SPN" SG_ 3221225472 RetarderEnableBrakeAssistSwitch 571;
BA_ "SigType" SG_ 3221225472 RetarderEnableBrakeAssistSwitch 4;
BA_ "SPN" SG_ 3221225472 RetarderTorqueMode 900;
BA_ "SigType" SG_ 3221225472 RetarderTorqueMode 4;
BA_ "SigType" SG_ 2566836478 TestLimitMinimum 1;
BA_ "SPN" SG_ 2566836478 TestLimitMinimum 1228;
BA_ "SigType" SG_ 2566836478 TestLimitMaximum 1;
BA_ "SPN" SG_ 2566836478 TestLimitMaximum 1227;
BA_ "SigType" SG_ 2566836478 TestValue 1;
BA_ "SPN" SG_ 2566836478 TestValue 1226;
BA_ "SigType" SG_ 2566836478 TestType 1;
BA_ "SPN" SG_ 2566836478 TestType 1225;
BA_ "SigType" SG_ 2566836478 TestIdentifier 1;
BA_ "SPN" SG_ 2566836478 TestIdentifier 1224;
BA_ "SPN" SG_ 2565078782 SPN1High 1214;
BA_ "SPN" SG_ 2565078782 SPN1 1214;
BA_ "SigType" SG_ 2565078782 TestIdentifier 1;
BA_ "SPN" SG_ 2565078782 TestIdentifier 1224;
BA_ "SPN" SG_ 2565078782 FailureModeIdentifier1 1215;
BA_ "SigType" SG_ 2560950014 TestLimitMinimum 1;
BA_ "SPN" SG_ 2560950014 TestLimitMinimum 1228;
BA_ "SigType" SG_ 2560950014 TestLimitMaximum 1;
BA_ "SPN" SG_ 2560950014 TestLimitMaximum 1227;
BA_ "SigType" SG_ 2560950014 TestValue 1;
BA_ "SPN" SG_ 2560950014 TestValue 1226;
BA_ "SigType" SG_ 2560950014 SlotId 1;
BA_ "SPN" SG_ 2560950014 SlotId 4109;
BA_ "SigType" SG_ 2560950014 TestIdentifier 1;
BA_ "SPN" SG_ 2560950014 TestIdentifier 1224;
BA_ "SPN" SG_ 2560950014 FailureModeIdentifier1 1215;
BA_ "SPN" SG_ 2560950014 SPN1High 1214;
BA_ "SPN" SG_ 2560950014 SPN1 1214;
BA_ "SPN" SG_ 2348941054 TrnsShftSlctorDisplayModeSwitch 2985;
BA_ "SigType" SG_ 2348941054 TrnsShftSlctorDisplayModeSwitch 4;
BA_ "SPN" SG_ 2348941054 TransMode4 1855;
BA_ "SigType" SG_ 2348941054 TransMode4 4;
BA_ "SPN" SG_ 2348941054 TransMode3 1854;
BA_ "SigType" SG_ 2348941054 TransMode3 4;
BA_ "SPN" SG_ 2348941054 TransMode2 1853;
BA_ "SigType" SG_ 2348941054 TransMode2 4;
BA_ "SPN" SG_ 2348941054 TransMode1 1852;
BA_ "SigType" SG_ 2348941054 TransMode1 4;
BA_ "SPN" SG_ 2348941054 DisengageDiffLockRqCentralRear 691;
BA_ "SigType" SG_ 2348941054 DisengageDiffLockRqCentralRear 4;
BA_ "SPN" SG_ 2348941054 DisengageDiffLockRqCentralFront 690;
BA_ "SigType" SG_ 2348941054 DisengageDiffLockRqCentralFront 4;
BA_ "SPN" SG_ 2348941054 DisengageDiffLockRqCentral 689;
BA_ "SigType" SG_ 2348941054 DisengageDiffLockRqCentral 4;
BA_ "SPN" SG_ 2348941054 DisengageDiffLockRqRearAxle2 688;
BA_ "SigType" SG_ 2348941054 DisengageDiffLockRqRearAxle2 4;
BA_ "SPN" SG_ 2348941054 DisengageDiffLockRqRearAxle1 687;
BA_ "SigType" SG_ 2348941054 DisengageDiffLockRqRearAxle1 4;
BA_ "SPN" SG_ 2348941054 DisengageDiffLockRqFrontAxle2 686;
BA_ "SigType" SG_ 2348941054 DisengageDiffLockRqFrontAxle2 4;
BA_ "SPN" SG_ 2348941054 DisengageDiffLockRqFrontAxle1 685;
BA_ "SigType" SG_ 2348941054 DisengageDiffLockRqFrontAxle1 4;
BA_ "SPN" SG_ 2348941054 TransRqedGear 525;
BA_ "SigType" SG_ 2348941054 TransRqedGear 1;
BA_ "SPN" SG_ 2348941054 RqedPercentClutchSlip 684;
BA_ "SigType" SG_ 2348941054 RqedPercentClutchSlip 1;
BA_ "SPN" SG_ 2348941054 DisengageDrivelineRq 683;
BA_ "SigType" SG_ 2348941054 DisengageDrivelineRq 4;
BA_ "SPN" SG_ 2348941054 TorqueConverterLockupDisableRq 682;
BA_ "SigType" SG_ 2348941054 TorqueConverterLockupDisableRq 4;
BA_ "SPN" SG_ 2348941054 TransGearShiftInhibitRq 681;
BA_ "SigType" SG_ 2348941054 TransGearShiftInhibitRq 4;
BA_ "SPN" SG_ 2562981630 IndividualDTCClearControlByte 3034;
BA_ "SPN" SG_ 2562981630 CtrlByteIndicIndividualDTCClear 3035;
BA_ "SPN" SG_ 2562981630 SPN1 1214;
BA_ "SPN" SG_ 2562981630 SPN1High 1214;
BA_ "SPN" SG_ 2562981630 FailureModeIdentifier1 1215;
BA_ "SPN" SG_ 2348875518 ControlPurpose 3350;
BA_ "SigType" SG_ 2348875518 ControlPurpose 4;
BA_ "SPN" SG_ 2348875518 TransmissionRate 3349;
BA_ "SigType" SG_ 2348875518 TransmissionRate 4;
BA_ "SPN" SG_ 2348875518 EngRqedTorque_TorqueLimit 518;
BA_ "SigType" SG_ 2348875518 EngRqedTorque_TorqueLimit 1;
BA_ "SPN" SG_ 2348875518 EngRqedSpeed_SpeedLimit 898;
BA_ "SigType" SG_ 2348875518 EngRqedSpeed_SpeedLimit 1;
BA_ "SPN" SG_ 2348875518 OverrideCtrlModePriority 897;
BA_ "SigType" SG_ 2348875518 OverrideCtrlModePriority 4;
BA_ "SPN" SG_ 2348875518 EngRqedSpeedCtrlConditions 696;
BA_ "SigType" SG_ 2348875518 EngRqedSpeedCtrlConditions 4;
BA_ "SPN" SG_ 2348875518 EngOverrideCtrlMode 695;
BA_ "SigType" SG_ 2348875518 EngOverrideCtrlMode 4;
BA_ "SPN" SG_ 2566840830 PercentTorqueAtPeakTorquePoint5 555;
BA_ "SigType" SG_ 2566840830 PercentTorqueAtPeakTorquePoint5 1;
BA_ "SPN" SG_ 2566840830 ReferenceRetarderTorque 556;
BA_ "SigType" SG_ 2566840830 ReferenceRetarderTorque 1;
BA_ "SPN" SG_ 2566840830 RetarderSpeedAtPeakTorquePoint5 547;
BA_ "SigType" SG_ 2566840830 RetarderSpeedAtPeakTorquePoint5 1;
BA_ "SPN" SG_ 2566840830 PercentTorqueAtPoint4 554;
BA_ "SigType" SG_ 2566840830 PercentTorqueAtPoint4 1;
BA_ "SPN" SG_ 2566840830 RetarderSpeedAtPoint4 550;
BA_ "SigType" SG_ 2566840830 RetarderSpeedAtPoint4 1;
BA_ "SPN" SG_ 2566840830 PercentTorqueAtPoint3 553;
BA_ "SigType" SG_ 2566840830 PercentTorqueAtPoint3 1;
BA_ "SPN" SG_ 2566840830 RetarderSpeedAtPoint3 549;
BA_ "SigType" SG_ 2566840830 RetarderSpeedAtPoint3 1;
BA_ "SPN" SG_ 2566840830 PercentTorqueAtMaxSpeedPoint2 552;
BA_ "SigType" SG_ 2566840830 PercentTorqueAtMaxSpeedPoint2 1;
BA_ "SPN" SG_ 2566840830 MaxRetarderSpeedPoint2 548;
BA_ "SigType" SG_ 2566840830 MaxRetarderSpeedPoint2 1;
BA_ "SPN" SG_ 2566840830 PercentTorqueAtIdlePoint1 551;
BA_ "SigType" SG_ 2566840830 PercentTorqueAtIdlePoint1 1;
BA_ "SPN" SG_ 2566840830 RetarderSpeedAtIdlePoint1 546;
BA_ "SigType" SG_ 2566840830 RetarderSpeedAtIdlePoint1 1;
BA_ "SPN" SG_ 2566840830 RetarderCtrlMethod 557;
BA_ "SigType" SG_ 2566840830 RetarderCtrlMethod 1;
BA_ "SPN" SG_ 2566840830 RetarderLocation 902;
BA_ "SigType" SG_ 2566840830 RetarderLocation 4;
BA_ "SPN" SG_ 2566840830 RetarderType 901;
BA_ "SigType" SG_ 2566840830 RetarderType 4;
BA_ "SPN" SG_ 2565865726 RetarderSelectionNonEng 1716;
BA_ "SigType" SG_ 2565865726 RetarderSelectionNonEng 1;
BA_ "SPN" SG_ 2565865726 ActlMxAvlblRtarderPercentTorque 1717;
BA_ "SigType" SG_ 2565865726 ActlMxAvlblRtarderPercentTorque 1;
BA_ "SPN" SG_ 2565865726 DrvrsDmandRetarderPercentTorque 1715;
BA_ "SigType" SG_ 2565865726 DrvrsDmandRetarderPercentTorque 1;
BA_ "GenSigStartValue" SG_ 2565865726 SrcAddrssOfCtrllngDvcFrRtrdrCtrl 14;
BA_ "SPN" SG_ 2565865726 SrcAddrssOfCtrllngDvcFrRtrdrCtrl 1480;
BA_ "SigType" SG_ 2565865726 SrcAddrssOfCtrllngDvcFrRtrdrCtrl 1;
BA_ "SPN" SG_ 2565865726 RetarderRqingBrakeLight 1667;
BA_ "SigType" SG_ 2565865726 RetarderRqingBrakeLight 4;
BA_ "SPN" SG_ 2565865726 EngCoolantLoadIncrease 1082;
BA_ "SigType" SG_ 2565865726 EngCoolantLoadIncrease 4;
BA_ "SPN" SG_ 2565865726 IntendedRetarderPercentTorque 1085;
BA_ "SigType" SG_ 2565865726 IntendedRetarderPercentTorque 1;
BA_ "SPN" SG_ 2565865726 ActualRetarderPercentTorque 520;
BA_ "SigType" SG_ 2565865726 ActualRetarderPercentTorque 1;
BA_ "SPN" SG_ 2565865726 RetarderEnableShiftAssistSwitch 572;
BA_ "SigType" SG_ 2565865726 RetarderEnableShiftAssistSwitch 4;
BA_ "SPN" SG_ 2565865726 RetarderEnableBrakeAssistSwitch 571;
BA_ "SigType" SG_ 2565865726 RetarderEnableBrakeAssistSwitch 4;
BA_ "SPN" SG_ 2565865726 RetarderTorqueMode 900;
BA_ "SigType" SG_ 2565865726 RetarderTorqueMode 4;
BA_ "SPN" SG_ 2566846206 EngCoolantFilterDiffPress 112;
BA_ "SigType" SG_ 2566846206 EngCoolantFilterDiffPress 1;
BA_ "SPN" SG_ 2566846206 EngExhaustGasTemp 173;
BA_ "SigType" SG_ 2566846206 EngExhaustGasTemp 1;
BA_ "SPN" SG_ 2566846206 EngAirFilter1DiffPress 107;
BA_ "SigType" SG_ 2566846206 EngAirFilter1DiffPress 1;
BA_ "SPN" SG_ 2566846206 EngAirInletPress 106;
BA_ "SigType" SG_ 2566846206 EngAirInletPress 1;
BA_ "SPN" SG_ 2566846206 EngIntakeManifold1Temp 105;
BA_ "SigType" SG_ 2566846206 EngIntakeManifold1Temp 1;
BA_ "SPN" SG_ 2566846206 EngTurboBoostPress 102;
BA_ "SigType" SG_ 2566846206 EngTurboBoostPress 1;
BA_ "SPN" SG_ 2566846206 EngParticulateTrapInletPress 81;
BA_ "SigType" SG_ 2566846206 EngParticulateTrapInletPress 1;
BA_ "SPN" SG_ 2566841854 EngTotalRevolutions 249;
BA_ "SigType" SG_ 2566841854 EngTotalRevolutions 1;
BA_ "SPN" SG_ 2566841854 EngTotalHoursOfOperation 247;
BA_ "SigType" SG_ 2566841854 EngTotalHoursOfOperation 1;
BA_ "SPN" SG_ 2566843134 CargoWeight 181;
BA_ "SigType" SG_ 2566843134 CargoWeight 1;
BA_ "SPN" SG_ 2566843134 TrailerWeight 180;
BA_ "SigType" SG_ 2566843134 TrailerWeight 1;
BA_ "SPN" SG_ 2566843134 AxleWeight 582;
BA_ "SigType" SG_ 2566843134 AxleWeight 1;
BA_ "SPN" SG_ 2566843134 AxleLocation 2928;
BA_ "SigType" SG_ 2566843134 AxleLocation 1;
BA_ "SigType" SG_ 2566843646 VehicleIdentificationNumber 8;
BA_ "SPN" SG_ 2566843646 VehicleIdentificationNumber 237;
BA_ "SPN" SG_ 2566832638 HighResolutionTripDistance 918;
BA_ "SigType" SG_ 2566832638 HighResolutionTripDistance 1;
BA_ "SPN" SG_ 2566832638 HghRslutionTotalVehicleDistance 917;
BA_ "SigType" SG_ 2566832638 HghRslutionTotalVehicleDistance 1;
BA_ "SPN" SG_ 2565868030 LongitudinalAcceleration 1810;
BA_ "SigType" SG_ 2565868030 LongitudinalAcceleration 1;
BA_ "SPN" SG_ 2565868030 LateralAcceleration 1809;
BA_ "SigType" SG_ 2565868030 LateralAcceleration 1;
BA_ "SPN" SG_ 2565868030 YawRate 1808;
BA_ "SigType" SG_ 2565868030 YawRate 1;
BA_ "SPN" SG_ 2565868030 SteerWheelAngleSensorType 1812;
BA_ "SigType" SG_ 2565868030 SteerWheelAngleSensorType 4;
BA_ "SPN" SG_ 2565868030 SteerWheelTurnCounter 1811;
BA_ "SigType" SG_ 2565868030 SteerWheelTurnCounter 4;
BA_ "SPN" SG_ 2565868030 SteerWheelAngle 1807;
BA_ "SigType" SG_ 2565868030 SteerWheelAngle 1;
BA_ "SPN" SG_ 2566803454 YCBrakeCtrlActive 1819;
BA_ "SigType" SG_ 2566803454 YCBrakeCtrlActive 4;
BA_ "SPN" SG_ 2566803454 YCEngCtrlActive 1817;
BA_ "SigType" SG_ 2566803454 YCEngCtrlActive 4;
BA_ "SPN" SG_ 2566803454 ROPBrakeCtrlActive 1818;
BA_ "SigType" SG_ 2566803454 ROPBrakeCtrlActive 4;
BA_ "SPN" SG_ 2566803454 ROPEngCtrlActive 1816;
BA_ "SigType" SG_ 2566803454 ROPEngCtrlActive 4;
BA_ "SPN" SG_ 2566803454 VDCBrakeLightRq 1815;
BA_ "SigType" SG_ 2566803454 VDCBrakeLightRq 4;
BA_ "SPN" SG_ 2566803454 VDCFullyOperational 1814;
BA_ "SigType" SG_ 2566803454 VDCFullyOperational 4;
BA_ "SPN" SG_ 2566803454 VDCInformationSignal 1813;
BA_ "SigType" SG_ 2566803454 VDCInformationSignal 4;
BA_ "SPN" SG_ 2566840574 TotalVehicleDistance 245;
BA_ "SigType" SG_ 2566840574 TotalVehicleDistance 1;
BA_ "SPN" SG_ 2566840574 TripDistance 244;
BA_ "SigType" SG_ 2566840574 TripDistance 1;
BA_ "SPN" SG_ 2561605374 ReferenceTirePressSetting 3193;
BA_ "SigType" SG_ 2561605374 ReferenceTirePressSetting 1;
BA_ "SPN" SG_ 2561605374 TireLocation 929;
BA_ "SigType" SG_ 2561605374 TireLocation 1;
BA_ "SPN" SG_ 2566765054 ReferenceTirePress 3191;
BA_ "SigType" SG_ 2566765054 ReferenceTirePress 1;
BA_ "SPN" SG_ 2566765054 TireLocation 929;
BA_ "SigType" SG_ 2566765054 TireLocation 1;
BA_ "SPN" SG_ 2566845694 TireTemp_21 521121;
BA_ "GenSigStartValue" SG_ 2566845694 TireTemp_21 9312;
BA_ "SigType" SG_ 2566845694 TireTemp_21 1;
BA_ "SPN" SG_ 2566845694 TireTemp_20 521120;
BA_ "GenSigStartValue" SG_ 2566845694 TireTemp_20 9312;
BA_ "SigType" SG_ 2566845694 TireTemp_20 1;
BA_ "SPN" SG_ 2566845694 TireTemp_11 521111;
BA_ "GenSigStartValue" SG_ 2566845694 TireTemp_11 9312;
BA_ "SigType" SG_ 2566845694 TireTemp_11 1;
BA_ "SPN" SG_ 2566845694 TireTemp_10 521110;
BA_ "GenSigStartValue" SG_ 2566845694 TireTemp_10 9312;
BA_ "SigType" SG_ 2566845694 TireTemp_10 1;
BA_ "SPN" SG_ 2566845694 TireTemp_01 521101;
BA_ "GenSigStartValue" SG_ 2566845694 TireTemp_01 9312;
BA_ "SigType" SG_ 2566845694 TireTemp_01 1;
BA_ "SPN" SG_ 2566845694 TireTemp_00 521100;
BA_ "GenSigStartValue" SG_ 2566845694 TireTemp_00 9312;
BA_ "SigType" SG_ 2566845694 TireTemp_00 1;
BA_ "SPN" SG_ 2566845694 TirePressThresholdDetection_21 521621;
BA_ "SigType" SG_ 2566845694 TirePressThresholdDetection_21 4;
BA_ "SPN" SG_ 2566845694 TirePressThresholdDetection_20 521620;
BA_ "SigType" SG_ 2566845694 TirePressThresholdDetection_20 4;
BA_ "SPN" SG_ 2566845694 TirePressThresholdDetection_11 521611;
BA_ "SigType" SG_ 2566845694 TirePressThresholdDetection_11 4;
BA_ "SPN" SG_ 2566845694 TirePressThresholdDetection_10 521610;
BA_ "SigType" SG_ 2566845694 TirePressThresholdDetection_10 4;
BA_ "SPN" SG_ 2566845694 TirePressThresholdDetection_01 521601;
BA_ "SigType" SG_ 2566845694 TirePressThresholdDetection_01 4;
BA_ "SPN" SG_ 2566845694 TirePressThresholdDetection_00 521600;
BA_ "SigType" SG_ 2566845694 TirePressThresholdDetection_00 4;
BA_ "SPN" SG_ 2566845694 TirePress_21 521021;
BA_ "SigType" SG_ 2566845694 TirePress_21 1;
BA_ "SPN" SG_ 2566845694 TirePress_20 521020;
BA_ "SigType" SG_ 2566845694 TirePress_20 1;
BA_ "SPN" SG_ 2566845694 TirePress_11 521011;
BA_ "SigType" SG_ 2566845694 TirePress_11 1;
BA_ "SPN" SG_ 2566845694 TirePress_10 521010;
BA_ "SigType" SG_ 2566845694 TirePress_10 1;
BA_ "SPN" SG_ 2566845694 TirePress_01 521001;
BA_ "SigType" SG_ 2566845694 TirePress_01 1;
BA_ "SPN" SG_ 2566845694 TirePress_00 521000;
BA_ "SigType" SG_ 2566845694 TirePress_00 1;
BA_ "SPN" SG_ 2566845694 TireAirLeakageRate_21 521521;
BA_ "SigType" SG_ 2566845694 TireAirLeakageRate_21 1;
BA_ "SPN" SG_ 2566845694 TireAirLeakageRate_20 521520;
BA_ "SigType" SG_ 2566845694 TireAirLeakageRate_20 1;
BA_ "SPN" SG_ 2566845694 TireAirLeakageRate_11 521511;
BA_ "SigType" SG_ 2566845694 TireAirLeakageRate_11 1;
BA_ "SPN" SG_ 2566845694 TireAirLeakageRate_10 521510;
BA_ "SigType" SG_ 2566845694 TireAirLeakageRate_10 1;
BA_ "SPN" SG_ 2566845694 TireAirLeakageRate_01 521501;
BA_ "SigType" SG_ 2566845694 TireAirLeakageRate_01 1;
BA_ "SPN" SG_ 2566845694 TireAirLeakageRate_00 521500;
BA_ "SigType" SG_ 2566845694 TireAirLeakageRate_00 1;
BA_ "SPN" SG_ 2566845694 CTIWheelSensorStatus_21 521421;
BA_ "SigType" SG_ 2566845694 CTIWheelSensorStatus_21 4;
BA_ "SPN" SG_ 2566845694 CTIWheelSensorStatus_20 521420;
BA_ "SigType" SG_ 2566845694 CTIWheelSensorStatus_20 4;
BA_ "SPN" SG_ 2566845694 CTIWheelSensorStatus_11 521411;
BA_ "SigType" SG_ 2566845694 CTIWheelSensorStatus_11 4;
BA_ "SPN" SG_ 2566845694 CTIWheelSensorStatus_10 521410;
BA_ "SigType" SG_ 2566845694 CTIWheelSensorStatus_10 4;
BA_ "SPN" SG_ 2566845694 CTIWheelSensorStatus_01 521401;
BA_ "SigType" SG_ 2566845694 CTIWheelSensorStatus_01 4;
BA_ "SPN" SG_ 2566845694 CTIWheelSensorStatus_00 521400;
BA_ "SigType" SG_ 2566845694 CTIWheelSensorStatus_00 4;
BA_ "SPN" SG_ 2566845694 CTIWheelEndElectricalFault_21 521221;
BA_ "SigType" SG_ 2566845694 CTIWheelEndElectricalFault_21 4;
BA_ "SPN" SG_ 2566845694 CTIWheelEndElectricalFault_20 521220;
BA_ "SigType" SG_ 2566845694 CTIWheelEndElectricalFault_20 4;
BA_ "SPN" SG_ 2566845694 CTIWheelEndElectricalFault_11 521211;
BA_ "SigType" SG_ 2566845694 CTIWheelEndElectricalFault_11 4;
BA_ "SPN" SG_ 2566845694 CTIWheelEndElectricalFault_10 521210;
BA_ "SigType" SG_ 2566845694 CTIWheelEndElectricalFault_10 4;
BA_ "SPN" SG_ 2566845694 CTIWheelEndElectricalFault_01 521201;
BA_ "SigType" SG_ 2566845694 CTIWheelEndElectricalFault_01 4;
BA_ "SPN" SG_ 2566845694 CTIWheelEndElectricalFault_00 521200;
BA_ "SigType" SG_ 2566845694 CTIWheelEndElectricalFault_00 4;
BA_ "SPN" SG_ 2566845694 CTITireStatus_21 521321;
BA_ "SigType" SG_ 2566845694 CTITireStatus_21 4;
BA_ "SPN" SG_ 2566845694 CTITireStatus_20 521320;
BA_ "SigType" SG_ 2566845694 CTITireStatus_20 4;
BA_ "SPN" SG_ 2566845694 CTITireStatus_11 521311;
BA_ "SigType" SG_ 2566845694 CTITireStatus_11 4;
BA_ "SPN" SG_ 2566845694 CTITireStatus_10 521310;
BA_ "SigType" SG_ 2566845694 CTITireStatus_10 4;
BA_ "SPN" SG_ 2566845694 CTITireStatus_01 521301;
BA_ "SigType" SG_ 2566845694 CTITireStatus_01 4;
BA_ "SPN" SG_ 2566845694 CTITireStatus_00 521300;
BA_ "SigType" SG_ 2566845694 CTITireStatus_00 4;
BA_ "SPN" SG_ 2566845694 TireLocation 929;
BA_ "SigType" SG_ 2566845694 TireLocation 1;
BA_ "SPN" SG_ 2566842110 LocalHourOffset 1602;
BA_ "SigType" SG_ 2566842110 LocalHourOffset 1;
BA_ "SPN" SG_ 2566842110 LocalMinuteOffset 1601;
BA_ "SigType" SG_ 2566842110 LocalMinuteOffset 1;
BA_ "SPN" SG_ 2566842110 Year 964;
BA_ "SigType" SG_ 2566842110 Year 1;
BA_ "SPN" SG_ 2566842110 Day 962;
BA_ "SigType" SG_ 2566842110 Day 1;
BA_ "SPN" SG_ 2566842110 Month 963;
BA_ "SigType" SG_ 2566842110 Month 1;
BA_ "SPN" SG_ 2566842110 Hours 961;
BA_ "SigType" SG_ 2566842110 Hours 1;
BA_ "SPN" SG_ 2566842110 Minutes 960;
BA_ "SigType" SG_ 2566842110 Minutes 1;
BA_ "SPN" SG_ 2566842110 Seconds 959;
BA_ "SigType" SG_ 2566842110 Seconds 1;
BA_ "SPN" SG_ 2365484286 TachographVehicleSpeed 1624;
BA_ "SigType" SG_ 2365484286 TachographVehicleSpeed 1;
BA_ "SPN" SG_ 2365484286 TachographOutputShaftSpeed 1623;
BA_ "SigType" SG_ 2365484286 TachographOutputShaftSpeed 1;
BA_ "SPN" SG_ 2365484286 DirectionIndicator 1619;
BA_ "SigType" SG_ 2365484286 DirectionIndicator 4;
BA_ "SPN" SG_ 2365484286 TachographPerformance 1620;
BA_ "SigType" SG_ 2365484286 TachographPerformance 4;
BA_ "SPN" SG_ 2365484286 HandlingInformation 1621;
BA_ "SigType" SG_ 2365484286 HandlingInformation 4;
BA_ "SPN" SG_ 2365484286 SystemEvent 1622;
BA_ "SigType" SG_ 2365484286 SystemEvent 4;
BA_ "SPN" SG_ 2365484286 DriverCardDriver2 1616;
BA_ "SigType" SG_ 2365484286 DriverCardDriver2 4;
BA_ "SPN" SG_ 2365484286 Driver2TimeRelatedStates 1618;
BA_ "SigType" SG_ 2365484286 Driver2TimeRelatedStates 4;
BA_ "SPN" SG_ 2365484286 Overspeed 1614;
BA_ "SigType" SG_ 2365484286 Overspeed 4;
BA_ "SPN" SG_ 2365484286 DriverCardDriver1 1615;
BA_ "SigType" SG_ 2365484286 DriverCardDriver1 4;
BA_ "SPN" SG_ 2365484286 Driver1TimeRelatedStates 1617;
BA_ "SigType" SG_ 2365484286 Driver1TimeRelatedStates 4;
BA_ "SPN" SG_ 2365484286 DriveRecognize 1611;
BA_ "SigType" SG_ 2365484286 DriveRecognize 4;
BA_ "SPN" SG_ 2365484286 Driver2WorkingState 1613;
BA_ "SigType" SG_ 2365484286 Driver2WorkingState 4;
BA_ "SPN" SG_ 2365484286 Driver1WorkingState 1612;
BA_ "SigType" SG_ 2365484286 Driver1WorkingState 4;
BA_ "SPN" SG_ 2566802430 TransTorqueLimit 1845;
BA_ "SigType" SG_ 2566802430 TransTorqueLimit 1;
BA_ "SPN" SG_ 2566841086 TransGearRatio 581;
BA_ "SigType" SG_ 2566841086 TransGearRatio 1;
BA_ "SPN" SG_ 2566841086 NumberOfForwardGearRatios 957;
BA_ "SigType" SG_ 2566841086 NumberOfForwardGearRatios 1;
BA_ "SPN" SG_ 2566841086 NumberOfReverseGearRatios 958;
BA_ "SigType" SG_ 2566841086 NumberOfReverseGearRatios 1;
BA_ "SPN" SG_ 2566839806 EngTurboOilLevelSwitch 1665;
BA_ "SigType" SG_ 2566839806 EngTurboOilLevelSwitch 4;
BA_ "SPN" SG_ 2566839806 EngTurbo1Speed 103;
BA_ "SigType" SG_ 2566839806 EngTurbo1Speed 1;
BA_ "SPN" SG_ 2566839806 EngTurboLubeOilPress1 104;
BA_ "SigType" SG_ 2566839806 EngTurboLubeOilPress1 1;
BA_ "SPN" SG_ 2566775550 AirSuspensionSupplyPressRq 2608;
BA_ "SigType" SG_ 2566775550 AirSuspensionSupplyPressRq 1;
BA_ "SPN" SG_ 2566775550 AuxEquipmentSupplyPressRq 2607;
BA_ "SigType" SG_ 2566775550 AuxEquipmentSupplyPressRq 1;
BA_ "SPN" SG_ 2566775550 ServiceBrakeAirPressRqCircuit2 2606;
BA_ "SigType" SG_ 2566775550 ServiceBrakeAirPressRqCircuit2 1;
BA_ "SPN" SG_ 2566775550 ServiceBrakeAirPressRqCircuit1 2605;
BA_ "SigType" SG_ 2566775550 ServiceBrakeAirPressRqCircuit1 1;
BA_ "SPN" SG_ 2566775550 ParkingAnd_OrTrailerAirPressRq 2604;
BA_ "SigType" SG_ 2566775550 ParkingAnd_OrTrailerAirPressRq 1;
BA_ "SPN" SG_ 2566775550 PneumaticSupplyPressRq 2603;
BA_ "SigType" SG_ 2566775550 PneumaticSupplyPressRq 1;
BA_ "SigType" SG_ 2566839038 SoftwareID3 8;
BA_ "SPN" SG_ 2566839038 SoftwareID3 234;
BA_ "SigType" SG_ 2566839038 SoftwareID2 8;
BA_ "SPN" SG_ 2566839038 SoftwareID2 234;
BA_ "SigType" SG_ 2566839038 SoftwareID1 8;
BA_ "SPN" SG_ 2566839038 SoftwareID1 234;
BA_ "SPN" SG_ 2566839038 NmbrOfSftwrIdentificationFields 965;
BA_ "SigType" SG_ 2566839038 NmbrOfSftwrIdentificationFields 1;
BA_ "SPN" SG_ 2566841598 EngOverspeedTest 2812;
BA_ "SigType" SG_ 2566841598 EngOverspeedTest 4;
BA_ "SPN" SG_ 2566841598 EngAirShutoffCmdStatus 2813;
BA_ "SigType" SG_ 2566841598 EngAirShutoffCmdStatus 4;
BA_ "SPN" SG_ 2566841598 EngAlarmOutputCmdStatus 2814;
BA_ "SigType" SG_ 2566841598 EngAlarmOutputCmdStatus 4;
BA_ "SPN" SG_ 2566841598 EngAlarmAcknowledge 2815;
BA_ "SigType" SG_ 2566841598 EngAlarmAcknowledge 4;
BA_ "SPN" SG_ 2566841598 EngProtectionSystemConfig 1111;
BA_ "SigType" SG_ 2566841598 EngProtectionSystemConfig 4;
BA_ "SPN" SG_ 2566841598 EngProtectionSystemTimerState 1107;
BA_ "SigType" SG_ 2566841598 EngProtectionSystemTimerState 4;
BA_ "SPN" SG_ 2566841598 EngPrtectionSystemTimerOverride 1108;
BA_ "SigType" SG_ 2566841598 EngPrtectionSystemTimerOverride 4;
BA_ "SPN" SG_ 2566841598 EngPrtctnSystmApprchingShutdown 1109;
BA_ "SigType" SG_ 2566841598 EngPrtctnSystmApprchingShutdown 4;
BA_ "SPN" SG_ 2566841598 EngPrtctionSystemHasShutdownEng 1110;
BA_ "SigType" SG_ 2566841598 EngPrtctionSystemHasShutdownEng 4;
BA_ "SPN" SG_ 2566841598 EngWaitToStartLamp 1081;
BA_ "SigType" SG_ 2566841598 EngWaitToStartLamp 4;
BA_ "SPN" SG_ 2566841598 RefrigerantHighPressSwitch 605;
BA_ "SigType" SG_ 2566841598 RefrigerantHighPressSwitch 4;
BA_ "SPN" SG_ 2566841598 RefrigerantLowPressSwitch 875;
BA_ "SigType" SG_ 2566841598 RefrigerantLowPressSwitch 4;
BA_ "SPN" SG_ 2566841598 A_CHighPressFanSwitch 985;
BA_ "SigType" SG_ 2566841598 A_CHighPressFanSwitch 4;
BA_ "SPN" SG_ 2566841598 EngIdleShutdownTimerFunction 591;
BA_ "SigType" SG_ 2566841598 EngIdleShutdownTimerFunction 4;
BA_ "SPN" SG_ 2566841598 EngIdleShutdownTimerState 590;
BA_ "SigType" SG_ 2566841598 EngIdleShutdownTimerState 4;
BA_ "SPN" SG_ 2566841598 EngIdleShutdownTimerOverride 592;
BA_ "SigType" SG_ 2566841598 EngIdleShutdownTimerOverride 4;
BA_ "SPN" SG_ 2566841598 EngIdleShutdownDriverAlertMode 594;
BA_ "SigType" SG_ 2566841598 EngIdleShutdownDriverAlertMode 4;
BA_ "SPN" SG_ 2566841598 EngIdleShutdownHasShutdownEng 593;
BA_ "SigType" SG_ 2566841598 EngIdleShutdownHasShutdownEng 4;
BA_ "SPN" SG_ 2566832382 ServiceComponentIdentificationB 912;
BA_ "SigType" SG_ 2566832382 ServiceComponentIdentificationB 1;
BA_ "SPN" SG_ 2566832382 ServiceComponentIdentificationA 911;
BA_ "SigType" SG_ 2566832382 ServiceComponentIdentificationA 1;
BA_ "SPN" SG_ 2566832382 SrvceDelay_OperationalTimeBased 916;
BA_ "SigType" SG_ 2566832382 SrvceDelay_OperationalTimeBased 1;
BA_ "SPN" SG_ 2566832382 ServiceDelay_CalendarTimeBased 915;
BA_ "SigType" SG_ 2566832382 ServiceDelay_CalendarTimeBased 1;
BA_ "SPN" SG_ 2566832382 ServiceDistance 914;
BA_ "SigType" SG_ 2566832382 ServiceDistance 1;
BA_ "SPN" SG_ 2566832382 ServiceComponentIdentification 1584;
BA_ "SigType" SG_ 2566832382 ServiceComponentIdentification 1;
BA_ "SPN" SG_ 2566847486 HydRetarderOilTemp 120;
BA_ "SigType" SG_ 2566847486 HydRetarderOilTemp 1;
BA_ "SPN" SG_ 2566847486 HydRetarderPress 119;
BA_ "SigType" SG_ 2566847486 HydRetarderPress 1;
BA_ "SPN" SG_ 2631859966 EngBuildHoursReset 1211;
BA_ "SigType" SG_ 2631859966 EngBuildHoursReset 4;
BA_ "SPN" SG_ 2631859966 ServiceComponentIdentification 1584;
BA_ "SigType" SG_ 2631859966 ServiceComponentIdentification 1;
BA_ "SPN" SG_ 2631859966 TripGroup2Proprietary 989;
BA_ "SigType" SG_ 2631859966 TripGroup2Proprietary 4;
BA_ "SPN" SG_ 2631859966 TripGroup1 988;
BA_ "SigType" SG_ 2631859966 TripGroup1 4;
BA_ "SPN" SG_ 2566844670 OperatorPTOMemorySelectSwitch 2897;
BA_ "SigType" SG_ 2566844670 OperatorPTOMemorySelectSwitch 4;
BA_ "SPN" SG_ 2566844670 EngPTOAccelerateSwitch 981;
BA_ "SigType" SG_ 2566844670 EngPTOAccelerateSwitch 4;
BA_ "SPN" SG_ 2566844670 EngPTOResumeSwitch 982;
BA_ "SigType" SG_ 2566844670 EngPTOResumeSwitch 4;
BA_ "SPN" SG_ 2566844670 EngPTOCoast_DecelerateSwitch 983;
BA_ "SigType" SG_ 2566844670 EngPTOCoast_DecelerateSwitch 4;
BA_ "SPN" SG_ 2566844670 EngPTOSetSwitch 984;
BA_ "SigType" SG_ 2566844670 EngPTOSetSwitch 4;
BA_ "SPN" SG_ 2566844670 EngRmtPTOVriableSpeedCtrlSwitch 978;
BA_ "SigType" SG_ 2566844670 EngRmtPTOVriableSpeedCtrlSwitch 4;
BA_ "SPN" SG_ 2566844670 EngRmtPTOPrprgrmmdSpdCtrlSwitch 979;
BA_ "SigType" SG_ 2566844670 EngRmtPTOPrprgrmmdSpdCtrlSwitch 4;
BA_ "SPN" SG_ 2566844670 EngPTOEnableSwitch 980;
BA_ "SigType" SG_ 2566844670 EngPTOEnableSwitch 4;
BA_ "SPN" SG_ 2566844670 PowerTakeoffSetSpeed 187;
BA_ "SigType" SG_ 2566844670 PowerTakeoffSetSpeed 1;
BA_ "SPN" SG_ 2566844670 PowerTakeoffSpeed 186;
BA_ "SigType" SG_ 2566844670 PowerTakeoffSpeed 1;
BA_ "SPN" SG_ 2566844670 PowerTakeoffOilTemp 90;
BA_ "SigType" SG_ 2566844670 PowerTakeoffOilTemp 1;
BA_ "SPN" SG_ 2566844670 RmtPTOPrprgrmmdSpeedCtrlSwitch2 3447;
BA_ "SigType" SG_ 2566844670 RmtPTOPrprgrmmdSpeedCtrlSwitch2 4;
BA_ "SPN" SG_ 2566844670 AuxInputIgnoreSwitch 3448;
BA_ "SigType" SG_ 2566844670 AuxInputIgnoreSwitch 4;
BA_ "SPN" SG_ 2566845182 EngAverageFuelEconomy 185;
BA_ "SigType" SG_ 2566845182 EngAverageFuelEconomy 1;
BA_ "SPN" SG_ 2566845182 EngInstantaneousFuelEconomy 184;
BA_ "SigType" SG_ 2566845182 EngInstantaneousFuelEconomy 1;
BA_ "SPN" SG_ 2566845182 EngFuelRate 183;
BA_ "SigType" SG_ 2566845182 EngFuelRate 1;
BA_ "SPN" SG_ 2566845182 EngThrottlePos 51;
BA_ "SigType" SG_ 2566845182 EngThrottlePos 1;
BA_ "SPN" SG_ 2566842878 EngTotalFuelUsed 250;
BA_ "SigType" SG_ 2566842878 EngTotalFuelUsed 1;
BA_ "SPN" SG_ 2566842878 EngTripFuel 182;
BA_ "SigType" SG_ 2566842878 EngTripFuel 1;
BA_ "SPN" SG_ 2566831614 FanSpeed 1639;
BA_ "SigType" SG_ 2566831614 FanSpeed 1;
BA_ "SPN" SG_ 2566831614 FanDriveState 977;
BA_ "SigType" SG_ 2566831614 FanDriveState 4;
BA_ "SPN" SG_ 2566831614 EstPercentFanSpeed 975;
BA_ "SigType" SG_ 2566831614 EstPercentFanSpeed 1;
BA_ "SPN" SG_ 2566802174 TransRqedGearFeedback 3289;
BA_ "SigType" SG_ 2566802174 TransRqedGearFeedback 1;
BA_ "SPN" SG_ 2566802174 TransMode1Indicator 2536;
BA_ "SigType" SG_ 2566802174 TransMode1Indicator 4;
BA_ "SPN" SG_ 2566802174 TransMode2Indicator 2537;
BA_ "SigType" SG_ 2566802174 TransMode2Indicator 4;
BA_ "SPN" SG_ 2566802174 TransMode3Indicator 2538;
BA_ "SigType" SG_ 2566802174 TransMode3Indicator 4;
BA_ "SPN" SG_ 2566802174 TransMode4Indicator 2539;
BA_ "SigType" SG_ 2566802174 TransMode4Indicator 4;
BA_ "SPN" SG_ 2566802174 TransShiftInhibitIndicator 1851;
BA_ "SigType" SG_ 2566802174 TransShiftInhibitIndicator 4;
BA_ "SPN" SG_ 2566802174 TransEngCrankEnable 2900;
BA_ "SigType" SG_ 2566802174 TransEngCrankEnable 4;
BA_ "SPN" SG_ 2566802174 ActiveShiftConsoleIndicator 2945;
BA_ "SigType" SG_ 2566802174 ActiveShiftConsoleIndicator 4;
BA_ "SPN" SG_ 2566802174 TransReadyForBrakeRelease 3086;
BA_ "SigType" SG_ 2566802174 TransReadyForBrakeRelease 4;
BA_ "SPN" SG_ 2566802174 TransRqedRangeDisplayFlashState 1849;
BA_ "SigType" SG_ 2566802174 TransRqedRangeDisplayFlashState 4;
BA_ "SPN" SG_ 2566802174 TransRqedRangeDisplayBlankState 1850;
BA_ "SigType" SG_ 2566802174 TransRqedRangeDisplayBlankState 4;
BA_ "SPN" SG_ 2565867006 TransCurrentRange 163;
BA_ "SigType" SG_ 2565867006 TransCurrentRange 1;
BA_ "SPN" SG_ 2565867006 TransRqedRange 162;
BA_ "SigType" SG_ 2565867006 TransRqedRange 1;
BA_ "SPN" SG_ 2565867006 TransCurrentGear 523;
BA_ "SigType" SG_ 2565867006 TransCurrentGear 1;
BA_ "SPN" SG_ 2565867006 TransActualGearRatio 526;
BA_ "SigType" SG_ 2565867006 TransActualGearRatio 1;
BA_ "SPN" SG_ 2565867006 TransSelectedGear 524;
BA_ "SigType" SG_ 2565867006 TransSelectedGear 1;
VAL_ 3221225472 FailureModeIdentifier5 31 "Not available" 19 "Received network data in error" 18 "Below normal (moderately severe)" 17 "Below normal (least severe)" 16 "Above normal (moderately severe)" 15 "Above normal (least severe)" 14 "Special intstructions" 13 "Out of calibration" 12 "Bad intelligent device" 11 "Root cause not known" 10 "Abnormal rate of change" 9 "Abnormal update rate" 8 "Abnormal frequency" 7 "Mechanical system not responding" 6 "Current above normal" 5 "Current below normal" 4 "Voltage below normal" 3 "Voltage above normal" 2 "Data erratic" 1 "Below normal (most severe)" 0 "Above normal (most severe)" ;
VAL_ 3221225472 FailureModeIdentifier4 31 "Not available" 19 "Received network data in error" 18 "Below normal (moderately severe)" 17 "Below normal (least severe)" 16 "Above normal (moderately severe)" 15 "Above normal (least severe)" 14 "Special intstructions" 13 "Out of calibration" 12 "Bad intelligent device" 11 "Root cause not known" 10 "Abnormal rate of change" 9 "Abnormal update rate" 8 "Abnormal frequency" 7 "Mechanical system not responding" 6 "Current above normal" 5 "Current below normal" 4 "Voltage below normal" 3 "Voltage above normal" 2 "Data erratic" 1 "Below normal (most severe)" 0 "Above normal (most severe)" ;
VAL_ 3221225472 FlashRedStopLamp 3 "Unavailable / Do Not Flash" 2 "Reserved" 1 "Fast Flash" 0 "Slow Flash" ;
VAL_ 3221225472 FlashProtectLamp 3 "Unavailable / Do Not Flash" 2 "Reserved" 1 "Fast Flash" 0 "Slow Flash" ;
VAL_ 3221225472 FlashMalfuncIndicatorLamp 3 "Unavailable / Do Not Flash" 2 "Reserved" 1 "Fast Flash" 0 "Slow Flash" ;
VAL_ 3221225472 FlashAmberWarningLamp 3 "Unavailable / Do Not Flash" 2 "Reserved" 1 "Fast Flash" 0 "Slow Flash" ;
VAL_ 3221225472 FailureModeIdentifier3 31 "Not available" 19 "Received network data in error" 18 "Below normal (moderately severe)" 17 "Below normal (least severe)" 16 "Above normal (moderately severe)" 15 "Above normal (least severe)" 14 "Special intstructions" 13 "Out of calibration" 12 "Bad intelligent device" 11 "Root cause not known" 10 "Abnormal rate of change" 9 "Abnormal update rate" 8 "Abnormal frequency" 7 "Mechanical system not responding" 6 "Current above normal" 5 "Current below normal" 4 "Voltage below normal" 3 "Voltage above normal" 2 "Data erratic" 1 "Below normal (most severe)" 0 "Above normal (most severe)" ;
VAL_ 3221225472 FailureModeIdentifier2 31 "Not available" 19 "Received network data in error" 18 "Below normal (moderately severe)" 17 "Below normal (least severe)" 16 "Above normal (moderately severe)" 15 "Above normal (least severe)" 14 "Special intstructions" 13 "Out of calibration" 12 "Bad intelligent device" 11 "Root cause not known" 10 "Abnormal rate of change" 9 "Abnormal update rate" 8 "Abnormal frequency" 7 "Mechanical system not responding" 6 "Current above normal" 5 "Current below normal" 4 "Voltage below normal" 3 "Voltage above normal" 2 "Data erratic" 1 "Below normal (most severe)" 0 "Above normal (most severe)" ;
VAL_ 3221225472 FailureModeIdentifier1 31 "Not available" 19 "Received network data in error" 18 "Below normal (moderately severe)" 17 "Below normal (least severe)" 16 "Above normal (moderately severe)" 15 "Above normal (least severe)" 14 "Special intstructions" 13 "Out of calibration" 12 "Bad intelligent device" 11 "Root cause not known" 10 "Abnormal rate of change" 9 "Abnormal update rate" 8 "Abnormal frequency" 7 "Mechanical system not responding" 6 "Current above normal" 5 "Current below normal" 4 "Voltage below normal" 3 "Voltage above normal" 2 "Data erratic" 1 "Below normal (most severe)" 0 "Above normal (most severe)" ;
VAL_ 3221225472 MalfunctionIndicatorLampStatus 3 "Not available" 2 "Reserved" 1 "Lamp on" 0 "Lamp off" ;
VAL_ 3221225472 RedStopLampState 3 "Not available" 2 "Reserved" 1 "Lamp on" 0 "Lamp off" ;
VAL_ 3221225472 AmberWarningLampStatus 3 "Not available" 2 "Reserved" 1 "Lamp on" 0 "Lamp off" ;
VAL_ 3221225472 ProtectLampStatus 3 "Not available" 2 "Reserved" 1 "Lamp on" 0 "Lamp off" ;
VAL_ 3221225472 ControlPurpose 5 "TemporaryPowerTrainControl" 4 "EngineProtection" 3 "RoadSpeedGovernor" 2 "PTOGovernor" 1 "CruiseControl" 0 "AcceleratorPedal" ;
VAL_ 3221225472 TransmissionRate 7 "UseStandardRate" 6 "25ms" 5 "50ms" 4 "100ms" 3 "250ms" 2 "500ms" 1 "750ms" 0 "1000ms" ;
VAL_ 3221225472 OverrideCtrlModePriority 3 "LowPriority" 2 "MdmPrrtyUsdFrPwrtrnCtrlOprtnsWh" 1 "HighPriority" 0 "HghstPrrtyUsdFrSttnsThtRqrImmdt" ;
VAL_ 3221225472 EngRqedSpeedCtrlConditions 2 "ThsCtrlCndtnHsBnOptmzdTMnmzRpmO" 3 "StbltyOptmzdFrDrvlnEnggdAnd_OrI" 1 "StbltyOptmzdFrDrvlnDsnggdAndNnl" 0 "ThsSpdGvrnrGnSlctnIsAdjstdTPrvd" ;
VAL_ 3221225472 EngOverrideCtrlMode 3 "Speed/torque limit control" 2 "Torque control" 1 "Speed control" 0 "Override disabled" ;
VAL_ 3221225472 OverrideCtrlModePrio 3 "Low priority" 2 "Medium priority" 1 "High priority" 0 "Highest priority" ;
VAL_ 3221225472 EngRqedSpeedCtrlCond 2 "StabilityOpt_engaged/lockup_cond2" 3 "StabilityOpt_engaged/lockup_cond1" 1 "StabilityOpt_disengaged/non-lockup" 0 "TransientOpt_disengaged/non-lockup" ;
VAL_ 3221225472 RetarderLocation 15 "NotAvailable" 14 "Other" 6 "1101NotDefined" 5 "Trailer" 4 "Driveline" 3 "TransOutput" 2 "TransInput" 1 "EngExhaustBrake" 0 "EngCompressionReleaseBrake" ;
VAL_ 3221225472 RetarderType 15 "NotAvailable" 14 "Other" 5 "1101NotDefined" 4 "Exhaust" 3 "CompressionRelease" 2 "CooledFriction" 1 "Hyd" 0 "Electric_Magnetic" ;
VAL_ 3221225472 EngCoolantLoadIncrease 3 "NotAvailable" 2 "Error" 1 "CoolantLoadIncreasePossible" 0 "NoCoolantLoadIncrease" ;
VAL_ 3221225472 RetarderEnableShiftAssistSwitch 3 "NotAvailable" 2 "Error" 1 "RetarderShiftAssistEnabled" 0 "RetarderShiftAssistDisabled" ;
VAL_ 3221225472 RetarderEnableBrakeAssistSwitch 3 "NotAvailable" 2 "Error" 1 "RetarderBrakeAssistEnabled" 0 "RetarderBrakeAssistDisabled" ;
VAL_ 2565078782 FailureModeIdentifier1 31 "Not available" 19 "Received network data in error" 18 "Below normal (moderately severe)" 17 "Below normal (least severe)" 16 "Above normal (moderately severe)" 15 "Above normal (least severe)" 14 "Special intstructions" 13 "Out of calibration" 12 "Bad intelligent device" 11 "Root cause not known" 10 "Abnormal rate of change" 9 "Abnormal update rate" 8 "Abnormal frequency" 7 "Mechanical system not responding" 6 "Current above normal" 5 "Current below normal" 4 "Voltage below normal" 3 "Voltage above normal" 2 "Data erratic" 1 "Below normal (most severe)" 0 "Above normal (most severe)" ;
VAL_ 2560950014 FailureModeIdentifier1 31 "Not available" 19 "Received network data in error" 18 "Below normal (moderately severe)" 17 "Below normal (least severe)" 16 "Above normal (moderately severe)" 15 "Above normal (least severe)" 14 "Special intstructions" 13 "Out of calibration" 12 "Bad intelligent device" 11 "Root cause not known" 10 "Abnormal rate of change" 9 "Abnormal update rate" 8 "Abnormal frequency" 7 "Mechanical system not responding" 6 "Current above normal" 5 "Current below normal" 4 "Voltage below normal" 3 "Voltage above normal" 2 "Data erratic" 1 "Below normal (most severe)" 0 "Above normal (most severe)" ;
VAL_ 2348941054 TrnsShftSlctorDisplayModeSwitch 3 "NotAvailable" 2 "Error" 1 "On" 0 "Off" ;
VAL_ 2348941054 TransMode4 3 "TakeNoAction" 2 "Reserved" 1 "Enable" 0 "Disable" ;
VAL_ 2348941054 TransMode3 3 "TakeNoAction" 2 "Reserved" 1 "Enable" 0 "Disable" ;
VAL_ 2348941054 TransMode2 3 "TakeNoAction" 2 "Reserved" 1 "Enable" 0 "Disable" ;
VAL_ 2348941054 TransMode1 3 "TakeNoAction" 2 "Reserved" 1 "Enable" 0 "Disable" ;
VAL_ 2348941054 DisengageDiffLockRqCentralRear 2 "Reserved" 3 "TakeNoAction" 1 "DisengageDiffLock" 0 "EngageDiffLock" ;
VAL_ 2348941054 DisengageDiffLockRqCentralFront 2 "Reserved" 3 "TakeNoAction" 1 "DisengageDiffLock" 0 "EngageDiffLock" ;
VAL_ 2348941054 DisengageDiffLockRqCentral 2 "Reserved" 3 "TakeNoAction" 1 "DisengageDiffLock" 0 "EngageDiffLock" ;
VAL_ 2348941054 DisengageDiffLockRqRearAxle2 2 "Reserved" 3 "TakeNoAction" 1 "DisengageDiffLock" 0 "EngageDiffLock" ;
VAL_ 2348941054 DisengageDiffLockRqRearAxle1 2 "Reserved" 3 "TakeNoAction" 1 "DisengageDiffLock" 0 "EngageDiffLock" ;
VAL_ 2348941054 DisengageDiffLockRqFrontAxle2 2 "Reserved" 3 "TakeNoAction" 1 "DisengageDiffLock" 0 "EngageDiffLock" ;
VAL_ 2348941054 DisengageDiffLockRqFrontAxle1 2 "Reserved" 3 "TakeNoAction" 1 "DisengageDiffLock" 0 "EngageDiffLock" ;
VAL_ 2348941054 TransRqedGear 61 "Reserved" 222 "NeutralSelectorPos" 223 "ReverseSelectorPos" 224 "PsUnknownAnd_OrNoButtonsPressed" 225 "PrssOfMmntryBttnTRslctCrrentPos" 226 "BtwnRvrsAndPrkShiftSelectorPoss" 227 "BtwnNtrlAndRvrsShftSelectorPoss" 228 "BtwnDrvAndNtrlShiftSelectorPoss" 229 "BtwnD1AndDriveShiftSelectorPoss" 230 "BetweenD2AndD1ShiftSelectorPoss" 231 "BetweenD3AndD2ShiftSelectorPoss" 232 "BetweenD4AndD3ShiftSelectorPoss" 233 "BetweenD5AndD4ShiftSelectorPoss" 234 "BetweenD6AndD5ShiftSelectorPoss" 235 "BetweenD7AndD6ShiftSelectorPoss" 236 "BtwnTwoForwardShiftSelectorPoss" 237 "BtwnTwoReverseShiftSelectorPoss" 238 "BetweenTwoShiftSelectorPoss" 239 "D77thFrwrdSlctrPsRfrncdFrmDrive" 240 "D66thFrwrdSlctrPsRfrncdFrmDrive" 241 "D55thFrwrdSlctrPsRfrncdFrmDrive" 242 "D44thFrwrdSlctrPsRfrncdFrmDrive" 243 "D33rdFrwrdSlctrPsRfrncdFrmDrive" 244 "D22ndFrwrdSlctrPsRfrncdFrmDrive" 245 "D11stFrwrdSlctrPsRfrncdFrmDrive" 246 "Downshift2GearsFromCurrentPos" 247 "Downshift1GearFromCurrentPos" 248 "Upshift2GearsFromCurrentPos" 249 "Upshift1GearFromCurrentPos" 250 "ForwardLowPos" 251 "ParkPos" 252 "ForwardDrivePos" 253 "HoldCurrentGear" ;
VAL_ 2348941054 DisengageDrivelineRq 2 "Reserved" 3 "TakeNoAction" 1 "DisengageDriveline" 0 "AllowDrivelineEngagement" ;
VAL_ 2348941054 TorqueConverterLockupDisableRq 2 "Reserved" 3 "TakeNoAction" 1 "DisableTorqueConvertorLockup" 0 "AllowTorqueConvertorLockup" ;
VAL_ 2348941054 TransGearShiftInhibitRq 2 "Reserved" 3 "TakeNoAction" 1 "GearShiftsAreInhibited" 0 "GearShiftsAreAllowed" ;
VAL_ 2562981630 FailureModeIdentifier1 31 "Not available" 19 "Received network data in error" 18 "Below normal (moderately severe)" 17 "Below normal (least severe)" 16 "Above normal (moderately severe)" 15 "Above normal (least severe)" 14 "Special intstructions" 13 "Out of calibration" 12 "Bad intelligent device" 11 "Root cause not known" 10 "Abnormal rate of change" 9 "Abnormal update rate" 8 "Abnormal frequency" 7 "Mechanical system not responding" 6 "Current above normal" 5 "Current below normal" 4 "Voltage below normal" 3 "Voltage above normal" 2 "Data erratic" 1 "Below normal (most severe)" 0 "Above normal (most severe)" ;
VAL_ 2348875518 ControlPurpose 5 "TemporaryPowerTrainControl" 4 "EngineProtection" 3 "RoadSpeedGovernor" 2 "PTOGovernor" 1 "CruiseControl" 0 "AcceleratorPedal" ;
VAL_ 2348875518 TransmissionRate 7 "UseStandardRate" 6 "25ms" 5 "50ms" 4 "100ms" 3 "250ms" 2 "500ms" 1 "750ms" 0 "1000ms" ;
VAL_ 2348875518 OverrideCtrlModePriority 3 "LowPriority" 2 "MdmPrrtyUsdFrPwrtrnCtrlOprtnsWh" 1 "HighPriority" 0 "HghstPrrtyUsdFrSttnsThtRqrImmdt" ;
VAL_ 2348875518 EngRqedSpeedCtrlConditions 2 "ThsCtrlCndtnHsBnOptmzdTMnmzRpmO" 3 "StbltyOptmzdFrDrvlnEnggdAnd_OrI" 1 "StbltyOptmzdFrDrvlnDsnggdAndNnl" 0 "ThsSpdGvrnrGnSlctnIsAdjstdTPrvd" ;
VAL_ 2348875518 EngOverrideCtrlMode 3 "Spd_TrqLmtCtrlLmtSpdAnd_OrTrqBs" 2 "TrqCtrlCntrlTrqTInclddDsrdTrqVl" 1 "SpdCtrlGvrnSpdTInclddDsrdSpdVle" 0 "OvrrdDsbldDsblAnyExstngCtrlCmdd" ;
VAL_ 2566840830 RetarderLocation 15 "NotAvailable" 14 "Other" 6 "1101NotDefined" 5 "Trailer" 4 "Driveline" 3 "TransOutput" 2 "TransInput" 1 "EngExhaustBrake" 0 "EngCompressionReleaseBrake" ;
VAL_ 2566840830 RetarderType 15 "NotAvailable" 14 "Other" 5 "1101NotDefined" 4 "Exhaust" 3 "CompressionRelease" 2 "CooledFriction" 1 "Hyd" 0 "Electric_Magnetic" ;
VAL_ 2565865726 EngCoolantLoadIncrease 3 "NotAvailable" 2 "Error" 1 "CoolantLoadIncreasePossible" 0 "NoCoolantLoadIncrease" ;
VAL_ 2565865726 RetarderEnableShiftAssistSwitch 3 "NotAvailable" 2 "Error" 1 "RetarderShiftAssistEnabled" 0 "RetarderShiftAssistDisabled" ;
VAL_ 2565865726 RetarderEnableBrakeAssistSwitch 3 "NotAvailable" 2 "Error" 1 "RetarderBrakeAssistEnabled" 0 "RetarderBrakeAssistDisabled" ;
VAL_ 2565868030 SteerWheelAngleSensorType 3 "NotAvailable" 2 "Reserved" 1 "AbsMeasuringPrinciple" 0 "RelativeMeasuringPrinciple" ;
VAL_ 2566803454 YCBrakeCtrlActive 3 "DontCare_TakeNoAction" 2 "Reserved" 1 "YCBrakeCtrlActive" 0 "YCBrakeCtrlPassiveButInstalled" ;
VAL_ 2566803454 YCEngCtrlActive 3 "DontCare_TakeNoAction" 2 "Reserved" 1 "YCEngCtrlActive" 0 "YCEngCtrlPassiveButInstalled" ;
VAL_ 2566803454 ROPBrakeCtrlActive 3 "DontCare_TakeNoAction" 2 "Reserved" 1 "ROPBrakeCtrlActive" 0 "ROPBrakeCtrlPassiveButInstalled" ;
VAL_ 2566803454 ROPEngCtrlActive 3 "DontCare_TakeNoAction" 2 "Reserved" 1 "ROPEngCtrlActive" 0 "ROPEngCtrlPassiveButInstalled" ;
VAL_ 2566803454 VDCBrakeLightRq 3 "DontCare_TakeNoAction" 2 "Reserved" 1 "TurnBrakeLightOn" 0 "TurnBrakeLightNotOn" ;
VAL_ 2566803454 VDCFullyOperational 3 "DontCare_TakeNoAction" 2 "Reserved" 1 "FullyOperational" 0 "NotFullyOperational" ;
VAL_ 2566803454 VDCInformationSignal 3 "DontCare_TakeNoAction" 2 "Reserved" 1 "On" 0 "Off" ;
VAL_ 2566845694 TirePressThresholdDetection_21 7 "NotAvailable" 6 "ErrorIndicator" 5 "NotDefined" 4 "ExtrmUndrPrssTrPrssrIsAtALvlWhr" 3 "UndrPrssTrPrssrIsLwrThnThPrssrD" 2 "NWrnngPrssTrPrssrIsWthnThThrshl" 1 "OvrPrssTrPrssrIsHghrThnThPrssrD" 0 "ExtrmOvrPrssTrPrssrIsAtALvlWhrT" ;
VAL_ 2566845694 TirePressThresholdDetection_20 7 "NotAvailable" 6 "ErrorIndicator" 5 "NotDefined" 4 "ExtrmUndrPrssTrPrssrIsAtALvlWhr" 3 "UndrPrssTrPrssrIsLwrThnThPrssrD" 2 "NWrnngPrssTrPrssrIsWthnThThrshl" 1 "OvrPrssTrPrssrIsHghrThnThPrssrD" 0 "ExtrmOvrPrssTrPrssrIsAtALvlWhrT" ;
VAL_ 2566845694 TirePressThresholdDetection_11 7 "NotAvailable" 6 "ErrorIndicator" 5 "NotDefined" 4 "ExtrmUndrPrssTrPrssrIsAtALvlWhr" 3 "UndrPrssTrPrssrIsLwrThnThPrssrD" 2 "NWrnngPrssTrPrssrIsWthnThThrshl" 1 "OvrPrssTrPrssrIsHghrThnThPrssrD" 0 "ExtrmOvrPrssTrPrssrIsAtALvlWhrT" ;
VAL_ 2566845694 TirePressThresholdDetection_10 7 "NotAvailable" 6 "ErrorIndicator" 5 "NotDefined" 4 "ExtrmUndrPrssTrPrssrIsAtALvlWhr" 3 "UndrPrssTrPrssrIsLwrThnThPrssrD" 2 "NWrnngPrssTrPrssrIsWthnThThrshl" 1 "OvrPrssTrPrssrIsHghrThnThPrssrD" 0 "ExtrmOvrPrssTrPrssrIsAtALvlWhrT" ;
VAL_ 2566845694 TirePressThresholdDetection_01 7 "NotAvailable" 6 "ErrorIndicator" 5 "NotDefined" 4 "ExtrmUndrPrssTrPrssrIsAtALvlWhr" 3 "UndrPrssTrPrssrIsLwrThnThPrssrD" 2 "NWrnngPrssTrPrssrIsWthnThThrshl" 1 "OvrPrssTrPrssrIsHghrThnThPrssrD" 0 "ExtrmOvrPrssTrPrssrIsAtALvlWhrT" ;
VAL_ 2566845694 TirePressThresholdDetection_00 7 "NotAvailable" 6 "ErrorIndicator" 5 "NotDefined" 4 "ExtrmUndrPrssTrPrssrIsAtALvlWhr" 3 "UndrPrssTrPrssrIsLwrThnThPrssrD" 2 "NWrnngPrssTrPrssrIsWthnThThrshl" 1 "OvrPrssTrPrssrIsHghrThnThPrssrD" 0 "ExtrmOvrPrssTrPrssrIsAtALvlWhrT" ;
VAL_ 2566845694 CTIWheelSensorStatus_21 3 "NotSupported" 2 "NotDefined" 1 "On" 0 "Off_IsolatedFromCTIPressCtrl" ;
VAL_ 2566845694 CTIWheelSensorStatus_20 3 "NotSupported" 2 "NotDefined" 1 "On" 0 "Off_IsolatedFromCTIPressCtrl" ;
VAL_ 2566845694 CTIWheelSensorStatus_11 3 "NotSupported" 2 "NotDefined" 1 "On" 0 "Off_IsolatedFromCTIPressCtrl" ;
VAL_ 2566845694 CTIWheelSensorStatus_10 3 "NotSupported" 2 "NotDefined" 1 "On" 0 "Off_IsolatedFromCTIPressCtrl" ;
VAL_ 2566845694 CTIWheelSensorStatus_01 3 "NotSupported" 2 "NotDefined" 1 "On" 0 "Off_IsolatedFromCTIPressCtrl" ;
VAL_ 2566845694 CTIWheelSensorStatus_00 3 "NotSupported" 2 "NotDefined" 1 "On" 0 "Off_IsolatedFromCTIPressCtrl" ;
VAL_ 2566845694 CTIWheelEndElectricalFault_21 3 "NotSupported" 2 "Error" 1 "NotDefined" 0 "Ok" ;
VAL_ 2566845694 CTIWheelEndElectricalFault_20 3 "NotSupported" 2 "Error" 1 "NotDefined" 0 "Ok" ;
VAL_ 2566845694 CTIWheelEndElectricalFault_11 3 "NotSupported" 2 "Error" 1 "NotDefined" 0 "Ok" ;
VAL_ 2566845694 CTIWheelEndElectricalFault_10 3 "NotSupported" 2 "Error" 1 "NotDefined" 0 "Ok" ;
VAL_ 2566845694 CTIWheelEndElectricalFault_01 3 "NotSupported" 2 "Error" 1 "NotDefined" 0 "Ok" ;
VAL_ 2566845694 CTIWheelEndElectricalFault_00 3 "NotSupported" 2 "Error" 1 "NotDefined" 0 "Ok" ;
VAL_ 2566845694 CTITireStatus_21 3 "NotSupported" 2 "Error" 1 "TireLeakDetected" 0 "Ok" ;
VAL_ 2566845694 CTITireStatus_20 3 "NotSupported" 2 "Error" 1 "TireLeakDetected" 0 "Ok" ;
VAL_ 2566845694 CTITireStatus_11 3 "NotSupported" 2 "Error" 1 "TireLeakDetected" 0 "Ok" ;
VAL_ 2566845694 CTITireStatus_10 3 "NotSupported" 2 "Error" 1 "TireLeakDetected" 0 "Ok" ;
VAL_ 2566845694 CTITireStatus_01 3 "NotSupported" 2 "Error" 1 "TireLeakDetected" 0 "Ok" ;
VAL_ 2566845694 CTITireStatus_00 3 "NotSupported" 2 "Error" 1 "TireLeakDetected" 0 "Ok" ;
VAL_ 2566845694 TireLocation 33 "Axle2_Position1" 32 "Axle2_Position0" 17 "Axle1_Position1" 16 "Axle1_Position0" 1 "Axle0_Position1" 0 "Axle0_Position0" ;
VAL_ 2365484286 DirectionIndicator 3 "NotAvailable" 2 "Error" 1 "Reverse" 0 "Forward" ;
VAL_ 2365484286 TachographPerformance 3 "NotAvailable" 2 "Error" 1 "PerformanceAnalysis" 0 "NormalPerformance" ;
VAL_ 2365484286 HandlingInformation 3 "NotAvailable" 2 "Error" 1 "HandlingInformation" 0 "NoHandlingInformation" ;
VAL_ 2365484286 SystemEvent 3 "NotAvailable" 2 "Error" 1 "TachographEvent" 0 "NoTachographEvent" ;
VAL_ 2365484286 DriverCardDriver2 3 "NotAvailable" 2 "Error" 1 "DriverCardPresent" 0 "DriverCardNotPresent" ;
VAL_ 2365484286 Driver2TimeRelatedStates 15 "NotAvailable" 14 "Error" 13 "Other" 7 "1100Reserved" 6 "Limit616HReached" 5 "Limit515MinBefore16H" 4 "Limit49HReached" 3 "Limit315MinBefore9H" 2 "Limit24HReached" 1 "Limit115MinBefore4H" 0 "Normal_NoLimitsReached" ;
VAL_ 2365484286 Overspeed 3 "NotAvailable" 2 "Error" 1 "Overspeed" 0 "NoOverspeed" ;
VAL_ 2365484286 DriverCardDriver1 3 "NotAvailable" 2 "Error" 1 "DriverCardPresent" 0 "DriverCardNotPresent" ;
VAL_ 2365484286 Driver1TimeRelatedStates 15 "NotAvailable" 14 "Error" 13 "Other" 7 "1100Reserved" 6 "Limit616HReached" 5 "Limit515MinBefore16H" 4 "Limit49HReached" 3 "Limit315MinBefore9H" 2 "Limit24HReached" 1 "Limit115MinBefore4H" 0 "Normal_NoLimitsReached" ;
VAL_ 2365484286 DriveRecognize 3 "NotAvailable" 2 "Error" 1 "VehicleMotionDetected" 0 "VehicleMotionNotDetected" ;
VAL_ 2365484286 Driver2WorkingState 7 "NotAvailable" 6 "Error" 4 "101Reserved" 3 "DriveBehindWheel" 2 "WrkLdngUnldingWorkingInAnOffice" 1 "DriverAvailableShortBreak" 0 "RestSleeping" ;
VAL_ 2365484286 Driver1WorkingState 7 "NotAvailable" 6 "Error" 4 "101Reserved" 3 "DriveBehindWheel" 2 "WrkLdngUnldingWorkingInAnOffice" 1 "DriverAvailableShortBreak" 0 "RestSleeping" ;
VAL_ 2566841598 EngOverspeedTest 3 "NotAvailable" 2 "Reserved" 1 "EngOverspeedTestActive" 0 "EngOverspeedTestNotActive" ;
VAL_ 2566841598 EngAirShutoffCmdStatus 0 "ArShtffDsbldNtAttmptngTShtffEng" 3 "NotAvailable" 2 "Reserved" 1 "ArShtffEnbldAttmptngTShtffEngAr" ;
VAL_ 2566841598 EngAlarmOutputCmdStatus 3 "NotAvailable" 2 "Reserved" 1 "EngAlarmOutputCmdActive" 0 "EngAlarmOutputCmdNotActive" ;
VAL_ 2566841598 EngAlarmAcknowledge 3 "NotAvailable" 2 "Error" 1 "EngAlarmAcknowledgeActive" 0 "EngAlarmAcknowledgeNotActive" ;
VAL_ 2566841598 EngProtectionSystemConfig 3 "NotAvailable" 2 "Error" 1 "EnabledInCalib" 0 "DisabledInCalib" ;
VAL_ 2566841598 EngProtectionSystemTimerState 3 "NotAvailable" 2 "Error" 1 "Active" 0 "Inactive" ;
VAL_ 2566841598 EngPrtectionSystemTimerOverride 3 "NotAvailable" 2 "Error" 1 "Active" 0 "Inactive" ;
VAL_ 2566841598 EngPrtctnSystmApprchingShutdown 3 "NotAvailable" 2 "Error" 1 "Approaching" 0 "NotApproaching" ;
VAL_ 2566841598 EngPrtctionSystemHasShutdownEng 0 "No" ;
VAL_ 2566841598 EngWaitToStartLamp 3 "NotAvailable" 2 "Error" 1 "On" 0 "Off" ;
VAL_ 2566841598 RefrigerantHighPressSwitch 3 "NotAvailable" 2 "Error" 1 "PrssTHghCmprssrCltchMyBDsngaged" 0 "PressNormal" ;
VAL_ 2566841598 RefrigerantLowPressSwitch 3 "NotAvailable" 2 "Error" 1 "PrssTLwCmprssrCltchMyBDsengaged" 0 "PressNormal" ;
VAL_ 2566841598 A_CHighPressFanSwitch 3 "NotAvailable" 2 "Error" 1 "PressHighFanMayBeEngaged" 0 "PressNormal" ;
VAL_ 2566841598 EngIdleShutdownTimerFunction 3 "NotAvailable" 2 "Error" 1 "EnabledInCalib" 0 "DisabledInCalib" ;
VAL_ 2566841598 EngIdleShutdownTimerState 3 "NotAvailable" 2 "Error" 1 "Active" 0 "Inactive" ;
VAL_ 2566841598 EngIdleShutdownTimerOverride 3 "NotAvailable" 2 "Error" 1 "Active" 0 "Inactive" ;
VAL_ 2566841598 EngIdleShutdownDriverAlertMode 3 "NotAvailable" 2 "Error" 1 "Active" 0 "Inactive" ;
VAL_ 2566841598 EngIdleShutdownHasShutdownEng 1 "Yes" 0 "No" ;
VAL_ 2631859966 EngBuildHoursReset 2 "Reserved" 3 "TakeNoAction" 1 "Reset" 0 "DoNotReset" ;
VAL_ 2631859966 TripGroup2Proprietary 2 "Reserved" 3 "NotApplicable" 1 "Reset" 0 "TakeNoAction" ;
VAL_ 2631859966 TripGroup1 2 "Reserved" 3 "NotApplicable" 1 "Reset" 0 "TakeNoAction" ;
VAL_ 2566844670 OperatorPTOMemorySelectSwitch 3 "notAvailable" 2 "error" 1 "PTOSetSpeedMemory2Selected" 0 "PTOSetSpeedMemory1Selected" ;
VAL_ 2566844670 EngPTOAccelerateSwitch 3 "NotAvailable" 2 "Error" 1 "On" 0 "Off" ;
VAL_ 2566844670 EngPTOResumeSwitch 3 "NotAvailable" 2 "Error" 1 "On" 0 "Off" ;
VAL_ 2566844670 EngPTOCoast_DecelerateSwitch 3 "NotAvailable" 2 "Error" 1 "On" 0 "Off" ;
VAL_ 2566844670 EngPTOSetSwitch 3 "NotAvailable" 2 "Error" 1 "On" 0 "Off" ;
VAL_ 2566844670 EngRmtPTOVriableSpeedCtrlSwitch 3 "NotAvailable" 2 "Error" 1 "On" 0 "Off" ;
VAL_ 2566844670 EngRmtPTOPrprgrmmdSpdCtrlSwitch 3 "NotAvailable" 2 "Error" 1 "On" 0 "Off" ;
VAL_ 2566844670 EngPTOEnableSwitch 3 "NotAvailable" 2 "Error" 1 "On" 0 "Off" ;
VAL_ 2566844670 RmtPTOPrprgrmmdSpeedCtrlSwitch2 3 "NotAvailable" 2 "Error" 1 "On" 0 "Off" ;
VAL_ 2566844670 AuxInputIgnoreSwitch 3 "NotAvailable" 2 "Error" 1 "On" 0 "Off" ;
VAL_ 2566831614 FanDriveState 15 "NotAvailable" 14 "Other" 13 "EngBrake" 12 "Timer" 11 "A_CSystem" 10 "TransRetarder" 9 "ManualCtrl" 8 "NotDefined" 7 "DefaultOperation" 6 "ExcessiveHydOilTemp" 5 "ExcessiveTransOilTemp" 4 "ExcessiveEngCoolantTemp" 3 "ExcessiveEngOilTemp" 2 "ExcessiveEngAirTemp" 1 "EngSystemGeneral" 0 "FanOff" ;
VAL_ 2566802174 TransMode1Indicator 3 "NotAvailable" 2 "Error" 1 "TransMode1Active" 0 "TransMode1NotActive" ;
VAL_ 2566802174 TransMode2Indicator 3 "NotAvailable" 2 "Error" 1 "TransMode2Active" 0 "TransMode2NotActive" ;
VAL_ 2566802174 TransMode3Indicator 3 "NotAvailable" 2 "Error" 1 "TransMode3Active" 0 "TransMode3NotActive" ;
VAL_ 2566802174 TransMode4Indicator 3 "NotAvailable" 2 "Error" 1 "TransMode4Active" 0 "TransMode4NotActive" ;
VAL_ 2566802174 TransShiftInhibitIndicator 3 "TakeNoAction" 2 "Reserved" 1 "ActiveShiftIsInhibited" 0 "InactiveShiftIsNotInhibited" ;
VAL_ 2566802174 TransEngCrankEnable 3 "NotAvailable" 2 "Error" 1 "CrnkngEnbldEngCrnkngIsAllwdByTr" 0 "CrnkngDsbldEngCrnkngIsPrhbtdByT" ;
VAL_ 2566802174 ActiveShiftConsoleIndicator 3 "NotAvailable" 2 "Reserved" 1 "SecondShiftConsoleIsActive" 0 "PrimaryShiftConsoleIsActive" ;
VAL_ 2566802174 TransReadyForBrakeRelease 3 "DontCare" 2 "Reserved" 1 "TransReadyForBrakeRelease" 0 "TransNotReadyForBrakeRelease" ;
VAL_ 2566802174 TransRqedRangeDisplayFlashState 3 "TakeNoAction" 2 "Reserved" 1 "ActvTrnsRqdRngDsplyShldBFlshing" 0 "InctvTrnsRqdRngDsplyShldNtBFlsh" ;
VAL_ 2566802174 TransRqedRangeDisplayBlankState 3 "TakeNoAction" 2 "Reserved" 1 "ActvTrnsRqdRngDsplyShldBBlanked" 0 "InctvTrnsRqdRngDsplyShldNtBBlnk" ;
